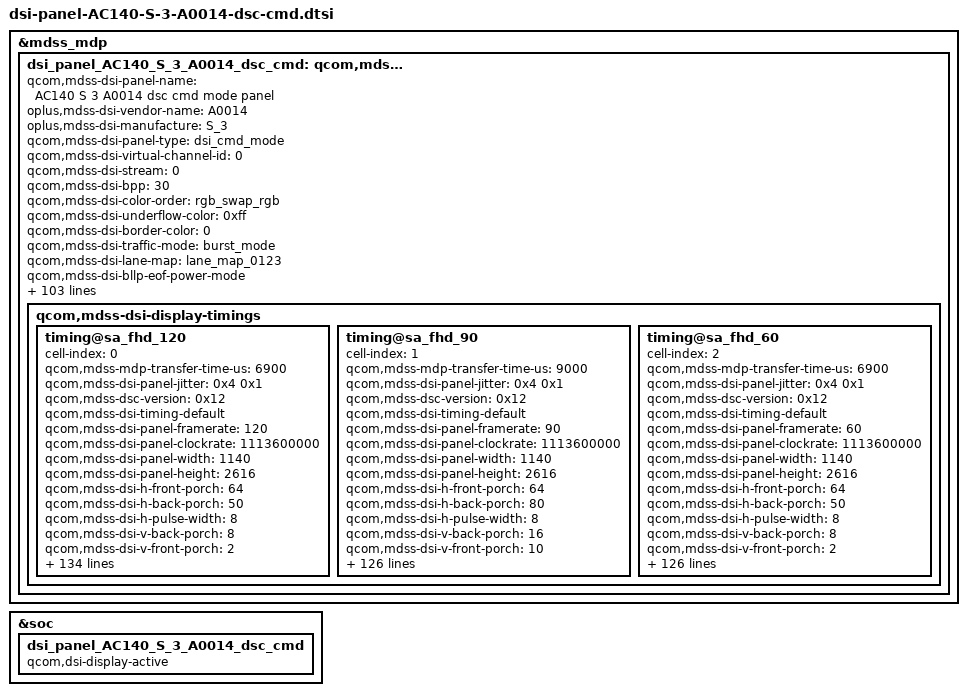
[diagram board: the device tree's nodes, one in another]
&mdss_mdp {
	dsi_panel_AC140_S_3_A0014_dsc_cmd: qcom,mdss_dsi_panel_AC140_S_3_A0014_dsc_cmd {
		qcom,mdss-dsi-panel-name = "AC140 S 3 A0014 dsc cmd mode panel";
		oplus,mdss-dsi-vendor-name = "A0014";
		oplus,mdss-dsi-manufacture = "S_3";
		qcom,mdss-dsi-panel-type = "dsi_cmd_mode";
		qcom,mdss-dsi-virtual-channel-id = <0>;
		qcom,mdss-dsi-stream = <0>;
		qcom,mdss-dsi-bpp = <30>;
		qcom,mdss-dsi-color-order = "rgb_swap_rgb";
		qcom,mdss-dsi-underflow-color = <0xff>;
		qcom,mdss-dsi-border-color = <0>;
		qcom,mdss-dsi-traffic-mode = "burst_mode";
		qcom,mdss-dsi-lane-map = "lane_map_0123";
		qcom,mdss-dsi-bllp-eof-power-mode;
		qcom,mdss-dsi-bllp-power-mode;
		qcom,mdss-dsi-lane-0-state;
		qcom,mdss-dsi-lane-1-state;
		qcom,mdss-dsi-lane-2-state;
		qcom,mdss-dsi-lane-3-state;
		qcom,mdss-dsi-dma-trigger = "trigger_sw";
		qcom,mdss-loading-effect;
		qcom,mdss-dsi-mdp-trigger = "none";
		qcom,mdss-dsi-reset-sequence = <1 2>, <0 5>, <1 30>;
		qcom,mdss-dsi-te-pin-select = <1>;
		qcom,mdss-dsi-te-dcs-command = <1>;
		qcom,mdss-pan-physical-width-dimension = <65>;
		qcom,mdss-pan-physical-height-dimension = <146>;
		qcom,mdss-dsi-init-delay-us = <1000>;
		qcom,mdss-dsi-te-check-enable;
		qcom,mdss-dsi-te-using-te-pin;
		//qcom,mdss-dsi-lp11-init;
		qcom,mdss-dsi-wr-mem-start = <0x2c>;
		qcom,mdss-dsi-wr-mem-continue = <0x3c>;
		qcom,mdss-dsi-panel-jitter = <0x4 0x1>;
		qcom,mdss-dsc-scr-version = <0x1>;
		qcom,mdss-bl-high2bit;
		/* HDR Setting */
		qcom,mdss-dsi-panel-hdr-enabled;
		qcom,mdss-dsi-panel-hdr-color-primaries = <15635 16450 34000 16000 13250 34500 7500 3000>;
		//update for [MPC15]android.mediapc.cts.PerformanceClassTest#testDisplayHdr pass
		//qcom,mdss-dsi-panel-peak-brightness = <16000000>;
		qcom,mdss-dsi-panel-peak-brightness = <22000000>;
		qcom,mdss-dsi-panel-average-brightness = <2000000>;
		qcom,mdss-dsi-panel-blackness-level = <4000>;
		qcom,dynamic-mode-switch-enabled;
		qcom,dynamic-mode-switch-type = "dynamic-resolution-switch-immediate";
		qcom,mdss-dsi-display-timings {
			timing@sa_fhd_120{
				cell-index = <0>;
				#include "dsi-panel-AC140-S-3-A0014-common.dtsi"
				qcom,mdss-mdp-transfer-time-us = <6900>;
				qcom,mdss-dsi-panel-jitter = <0x4 0x1>;
				qcom,mdss-dsc-version = <0x12>;
				qcom,mdss-dsi-timing-default;
				qcom,mdss-dsi-panel-framerate = <120>;
				qcom,mdss-dsi-panel-clockrate = <1113600000>;
				qcom,mdss-dsi-panel-width = <1140>;
				qcom,mdss-dsi-panel-height = <2616>;
				qcom,mdss-dsi-h-front-porch = <64>;
				qcom,mdss-dsi-h-back-porch = <50>;
				qcom,mdss-dsi-h-pulse-width = <8>;
				qcom,mdss-dsi-v-back-porch = <8>;
				qcom,mdss-dsi-v-front-porch = <2>;
				qcom,mdss-dsi-v-pulse-width = <2>;
				qcom,mdss-dsi-h-sync-pulse = <0>;

				qcom,mdss-dsi-h-left-border = <0>;
				qcom,mdss-dsi-h-right-border = <0>;
				qcom,mdss-dsi-v-top-border = <0>;
				qcom,mdss-dsi-v-bottom-border = <0>;
				qcom,dsi-mode-te-width-us = <270>;

				/* Apollo vsync config, need to measure TE signal */
				//oplus,apollo-panel-vsync-width = <13000>;
				//oplus,apollo-panel-vsync-period = <16600>;

				oplus,fod-on-vblank = <0>;
				oplus,fod-off-vblank = <0>;

				qcom,mdss-dsi-timing-switch-command = [
					//Switch to 120Hz(3+18pulse)
					15 00 00 40 00 00 02 2F 02
					39 00 00 40 00 00 06 35 00 00 00 00 00
					15 00 00 00 08 00 02 5A 10
					15 00 00 40 00 00 02 6D 00
					15 00 00 40 00 00 02 2F 32
					//Base 120hz(3+18pulse) SEQ Setting
					39 00 00 40 00 00 06 F0 55 AA 52 08 00
					15 00 00 40 00 00 02 6F 1C
					39 00 00 40 00 00 11 BA 01 00 00 00 00 00 00 00 00 00 00 00 00 00 00 00
					15 00 00 40 00 00 02 6F 2C
					39 00 00 40 00 00 11 BA 00 00 00 00 00 00 00 00 00 00 00 00 00 00 00 00
					15 00 00 40 00 00 02 6F 3C
					39 00 00 40 00 00 11 BA 00 00 00 00 00 00 00 00 00 00 00 00 00 00 00 00
					15 00 00 40 00 00 02 6F 4C
					39 00 00 40 00 00 11 BA 00 00 00 00 00 00 00 00 00 00 00 00 00 00 00 00
					15 00 00 40 00 00 02 6F 5C
					39 00 00 40 00 00 11 BA 01 01 01 01 01 01 01 01 01 01 01 01 01 01 01 01
					15 00 00 40 00 00 02 6F 6C
					39 00 00 40 00 00 09 BA 00 00 00 00 00 00 00 00
					15 00 00 40 00 00 02 6F 74
					39 00 00 40 00 00 11 BA 00 01 02 03 05 0B 17 77 00 02 05 08 11 59 00 00
					15 00 00 40 00 00 02 6F 84
					39 00 00 40 00 00 11 BA 00 01 02 03 05 0B 17 77 00 02 05 08 11 59 00 00
					15 00 00 40 00 00 02 6F 94
					39 00 00 40 00 00 11 BA 00 00 00 00 00 00 00 00 00 00 00 00 00 00 00 00
					15 00 00 40 00 00 02 6F A4
					39 00 00 40 00 00 11 BA 01 01 01 01 00 00 00 00 00 00 00 00 00 00 00 00
					15 00 00 40 00 00 02 6F B4
					39 00 00 40 00 00 05 BA 00 00 00 00
					15 00 00 40 00 00 02 6F B8
					39 00 00 40 00 00 09 BA 22 22 22 22 11 11 11 22
					15 00 00 40 00 00 02 6F C0
					39 00 00 00 00 00 09 BA 22 22 22 22 11 11 11 22
					];
				qcom,mdss-dsi-on-command = [
					39 00 00 40 00 00 06 F0 55 AA 52 08 00
					15 00 00 40 00 00 02 6F 03
					15 00 00 40 00 00 02 B5 65
					39 00 00 40 00 00 06 F0 55 AA 52 08 08
					15 00 00 40 00 00 02 6F 80
					39 00 00 40 00 00 0D B8 00 10 00 10 00 10 00 00 00 00 00 00
					39 00 00 00 00 00 11 E9 00 00 00 C5 18 94 0F E6 01 90 00 78 14 48 0F C6
					/* Drag optimization */
					39 00 00 40 00 00 06 F0 55 AA 52 08 08
					15 00 00 40 00 00 02 E0 31
					15 00 00 40 00 00 02 6F 05
					15 00 00 40 00 00 02 E0 20
					15 00 00 40 00 00 02 6F 02
					15 00 00 40 00 00 02 E1 05
					15 00 00 40 00 00 02 6F 02
					15 00 00 40 00 00 02 E2 0A
					15 00 00 40 00 00 02 6F 0E
					39 00 00 40 00 00 04 E1 00 00 0D
					15 00 00 40 00 00 02 6F 0E
					39 00 00 40 00 00 04 E2 02 06 13
					15 00 00 40 00 00 02 6F 0E
					39 00 00 40 00 00 04 E3 00 02 00
					15 00 00 40 00 00 02 6F 1E
					15 00 00 40 00 00 02 E1 00
					15 00 00 40 00 00 02 6F 1E
					15 00 00 40 00 00 02 E2 1C
					15 00 00 40 00 00 02 6F 2C
					15 00 00 40 00 00 02 E2 0A
					15 00 00 40 00 00 02 6F 2C
					15 00 00 40 00 00 02 E3 01
					15 00 00 40 00 00 02 6F 3A
					15 00 00 40 00 00 02 E1 04
					15 00 00 40 00 00 02 6F 3A
					15 00 00 40 00 00 02 E2 0B
					15 00 00 40 00 00 02 6F 48
					15 00 00 40 00 00 02 E2 06
					15 00 00 40 00 00 02 6F 48
					15 00 00 40 00 00 02 E3 04
					15 00 00 40 00 00 02 6F 56
					15 00 00 40 00 00 02 E2 06
					15 00 00 40 00 00 02 6F 56
					15 00 00 40 00 00 02 E3 04
					15 00 00 40 00 00 02 6F 64
					15 00 00 40 00 00 02 E2 04
					15 00 00 40 00 00 02 6F 64
					15 00 00 00 00 00 02 E3 01
					/* Power consumption optimization */
					39 00 00 40 00 00 06 F0 55 AA 52 08 03
					15 00 00 40 00 00 02 6F 33
					39 00 00 40 00 00 0B B0 00 00 00 00 00 00 00 00 00 00
					15 00 00 40 00 00 02 6F 3D
					39 00 00 40 00 00 0B B0 00 00 00 00 00 00 00 00 00 00
					15 00 00 40 00 00 02 6F 47
					39 00 00 40 00 00 0B B0 00 00 00 00 00 00 00 00 00 00
					15 00 00 40 00 00 02 6F 51
					39 00 00 40 00 00 0B B0 00 00 00 00 00 00 00 00 00 00
					15 00 00 40 00 00 02 6F 0C
					39 00 00 00 00 00 04 C3 44 00 04
					/*Common Setting*/
					39 00 00 40 00 00 06 F0 55 AA 52 08 00
					15 00 00 40 00 00 02 6F 5A
					39 00 00 00 00 00 08 D1 33 33 33 33 11 11 11
					39 00 00 40 00 00 06 F0 55 AA 52 08 01
					15 00 00 40 00 00 02 6F 03
					39 00 00 40 00 00 04 C5 00 24 24
					15 00 00 40 00 00 02 E5 00
					39 00 00 40 00 00 06 F0 55 AA 52 00 00
					39 00 00 40 00 00 05 FF AA 55 A5 80
					15 00 00 40 00 00 02 6F 16
					39 00 00 40 00 00 03 F4 02 74
					15 00 00 40 00 00 02 6F 31
					39 00 00 40 00 00 03 F8 01 73
					15 00 00 40 00 00 02 6F 15
					39 00 00 40 00 00 03 F8 01 8F
					15 00 00 40 00 00 02 6F 42
					15 00 00 40 00 00 02 F4 00
					15 00 00 40 00 00 02 6F 49
					15 00 00 40 00 00 02 F2 10
					39 00 00 40 00 00 05 FF AA 55 A5 81
					15 00 00 40 00 00 02 6F 0D
					15 00 00 40 00 00 02 FB 80
					15 00 00 40 00 00 02 6F 10
					15 00 00 40 00 00 02 FB 40
					15 00 00 40 00 00 02 6F 0C
					15 00 00 40 00 00 02 FD 08
					15 00 00 40 00 00 02 6F 05
					39 00 00 40 00 00 03 FE 3C 3C
					15 00 00 40 00 00 02 6F 0B
					15 00 00 40 00 00 02 FD 04
					39 00 00 40 00 00 05 FF AA 55 A5 82
					15 00 00 40 00 00 02 6F 09
					15 00 00 40 00 00 02 F2 FF
					39 00 00 40 00 00 05 FF AA 55 A5 83
					39 00 00 40 00 00 05 FF AA 55 A5 00
					05 00 00 00 00 00 01 35
					15 00 00 40 00 00 02 53 20
					39 00 00 40 00 00 05 2A 00 00 04 73
					39 00 00 40 00 00 05 2B 00 00 0A 37
					15 00 00 40 00 00 02 26 00
					39 00 00 00 00 00 03 81 01 19
					/*DSC Setting*/
					39 00 00 40 00 00 03 90 03 43
					39 00 00 00 00 00 13 91 A0 F0 00 0C D1 00 01 CC 00 50 00 2F 09 75 2D 7A 11 50
					//Switch to 120Hz(3+18pulse)
					15 00 00 40 00 00 02 2F 02
					39 00 00 40 00 00 06 35 00 00 00 00 00
					15 00 00 00 08 00 02 5A 10
					15 00 00 40 00 00 02 6D 00
					15 00 00 40 00 00 02 2F 32
					//Base 120hz(3+18pulse) SEQ Setting
					39 00 00 40 00 00 06 F0 55 AA 52 08 00
					15 00 00 40 00 00 02 6F 1C
					39 00 00 40 00 00 11 BA 01 00 00 00 00 00 00 00 00 00 00 00 00 00 00 00
					15 00 00 40 00 00 02 6F 2C
					39 00 00 40 00 00 11 BA 00 00 00 00 00 00 00 00 00 00 00 00 00 00 00 00
					15 00 00 40 00 00 02 6F 3C
					39 00 00 40 00 00 11 BA 00 00 00 00 00 00 00 00 00 00 00 00 00 00 00 00
					15 00 00 40 00 00 02 6F 4C
					39 00 00 40 00 00 11 BA 00 00 00 00 00 00 00 00 00 00 00 00 00 00 00 00
					15 00 00 40 00 00 02 6F 5C
					39 00 00 40 00 00 11 BA 01 01 01 01 01 01 01 01 01 01 01 01 01 01 01 01
					15 00 00 40 00 00 02 6F 6C
					39 00 00 40 00 00 09 BA 00 00 00 00 00 00 00 00
					15 00 00 40 00 00 02 6F 74
					39 00 00 40 00 00 11 BA 00 01 02 03 05 0B 17 77 00 02 05 08 11 59 00 00
					15 00 00 40 00 00 02 6F 84
					39 00 00 40 00 00 11 BA 00 01 02 03 05 0B 17 77 00 02 05 08 11 59 00 00
					15 00 00 40 00 00 02 6F 94
					39 00 00 40 00 00 11 BA 00 00 00 00 00 00 00 00 00 00 00 00 00 00 00 00
					15 00 00 40 00 00 02 6F A4
					39 00 00 40 00 00 11 BA 01 01 01 01 00 00 00 00 00 00 00 00 00 00 00 00
					15 00 00 40 00 00 02 6F B4
					39 00 00 40 00 00 05 BA 00 00 00 00
					15 00 00 40 00 00 02 6F B8
					39 00 00 40 00 00 09 BA 22 22 22 22 11 11 11 22
					15 00 00 40 00 00 02 6F C0
					39 00 00 00 00 00 09 BA 22 22 22 22 11 11 11 22
					/* delay 8ms make sure pmic timing normal */
					39 00 00 40 00 00 06 F0 55 AA 52 08 00
					15 00 00 40 00 00 02 6F 02
					39 00 00 00 00 00 03 B5 2A 95
					/*add VDC code resolve 100%APL brightness */
					39 00 00 40 00 00 06 F0 55 AA 52 08 08
					39 00 00 40 00 00 11 BE 03 F1 00 5B 02 C0 03 C6 BA 6C 03 C6 BA 6C 03 59
					39 00 00 40 00 00 02 6F 10
					39 00 00 40 00 00 11 BE CA BA 03 59 CA BA 01 22 04 BA 01 22 04 BA 01 01
					39 00 00 40 00 00 02 6F 20
					39 00 00 00 00 00 11 BE 56 6B 01 01 56 6B 04 A9 BB B4 01 66 1E B6 80 64
					39 00 00 40 00 00 06 F0 55 AA 52 08 07
					39 00 00 40 00 00 04 C0 07 01 F8
					15 00 00 40 00 00 02 6F 03
					39 00 00 40 00 00 05 C0 00 00 00 00
					39 00 00 40 00 00 16 C1 30 0F 02 40 04 00 FA 00 3F FE 12 00 3F FC 52 00 00 00 65 C0 00
					15 00 00 40 00 00 02 6F 15
					39 00 00 40 00 00 11 C1 20 00 1F 77 00 00 20 33 F0 E0 A8 0B 00 00 00 00
					15 00 00 40 00 00 02 6F 25
					39 00 00 40 00 00 08 C1 00 00 1E 00 00 20 00
					39 00 00 40 00 00 16 C2 38 0F 06 40 02 40 F8 80 3F FB 3D 40 3F FD E9 A0 00 00 78 D9 80
					15 00 00 40 00 00 02 6F 15
					39 00 00 40 00 00 11 C2 64 00 00 1E 00 21 85 33 F0 9C E2 0B B8 00 00 00
					15 00 00 40 00 00 02 6F 25
					39 00 00 40 00 00 08 C2 44 55 73 00 00 20 00
					39 00 00 40 00 00 16 C3 3C 00 0E 89 03 C1 0E C6 3F F1 59 00 00 00 00 00 00 00 00 00 00
					15 00 00 40 00 00 02 6F 15
					39 00 00 40 00 00 11 C3 70 00 00 1F 9A A3 16 33 C0 8D 1F 00 00 00 00 00
					15 00 00 40 00 00 02 6F 25
					39 00 00 40 00 00 08 C3 00 00 1F AA 17 37 00
					39 00 00 40 00 00 16 C4 34 00 03 84 03 C1 07 44 3F FC 6C 0C 00 03 93 F4 00 00 00 00 00
					15 00 00 40 00 00 02 6F 15
					39 00 00 40 00 00 11 C4 20 00 20 7D AA 17 37 33 C0 E0 5D 00 00 00 00 00
					15 00 00 40 00 00 02 6F 25
					39 00 00 40 00 00 08 C4 44 54 73 AA 17 37 00
					39 00 00 40 00 00 16 C5 2A 0F 0D 24 03 49 F2 DC 00 0A 36 88 00 01 BF 3C 7F FE 92 11 64
					15 00 00 40 00 00 02 6F 15
					39 00 00 40 00 00 11 C5 70 44 54 73 9A A4 16 33 0F 72 1F F2 32 00 00 00
					15 00 00 40 00 00 02 6F 25
					39 00 00 40 00 00 08 C5 00 00 00 00 00 00 00
					39 00 00 40 00 00 16 C6 2A 0F 01 E4 04 00 FA 80 00 01 20 30 00 04 15 60 7F FF 6D 54 00
					15 00 00 40 00 00 02 6F 15
					39 00 00 40 00 00 11 C6 00 34 FF 53 AA 17 37 33 0F 20 54 F5 80 00 00 00
					15 00 00 40 00 00 02 6F 25
					39 00 00 40 00 00 08 C6 00 00 00 00 00 00 00
					39 00 00 40 00 00 16 C7 26 00 02 40 04 84 06 60 00 00 64 00 3F FA 0B 00 00 00 00 00 00
					15 00 00 40 00 00 02 6F 15
					39 00 00 40 00 00 11 C7 1F 34 FC 54 00 00 20 33 30 20 A8 00 00 00 00 00
					15 00 00 40 00 00 02 6F 25
					39 00 00 40 00 00 08 C7 00 00 00 00 00 00 00
					39 00 00 40 00 00 16 C8 26 00 0B 64 02 A4 0A F8 00 03 D4 00 3F FC 2C 00 00 00 00 00 00
					15 00 00 40 00 00 02 6F 15
					39 00 00 40 00 00 11 C8 00 44 55 73 00 21 8F 33 30 6E E2 00 00 00 00 00
					15 00 00 40 00 00 02 6F 25
					39 00 00 40 00 00 08 C8 00 00 00 00 00 00 00
					39 00 00 40 00 00 16 C9 21 00 05 10 05 10 00 00 3F FE 93 80 3F FE 93 80 00 00 1C 84 20
					15 00 00 40 00 00 02 6F 15
					39 00 00 40 00 00 11 C9 0A 22 14 39 00 1C 41 55 F0 DC DC 05 10 F0 FF FF
					15 00 00 40 00 00 02 6F 25
					39 00 00 40 00 00 08 C9 00 00 00 00 00 00 00
					39 00 00 40 00 00 16 CA 27 00 05 10 05 10 00 00 00 00 00 00 3F FE 93 80 00 00 01 71 90
					15 00 00 40 00 00 02 6F 15
					39 00 00 40 00 00 11 CA 0A 22 3A 5F 00 1C 41 55 30 24 DC 00 00 C0 00 FF
					15 00 00 40 00 00 02 6F 25
					39 00 00 40 00 00 08 CA 00 00 00 00 00 00 00
					39 00 00 40 00 00 16 CB 2D 00 05 10 05 10 00 00 3F FE 93 80 00 00 00 00 00 00 01 71 90
					15 00 00 40 00 00 02 6F 15
					39 00 00 40 00 00 11 CB 19 22 14 39 00 42 67 55 C0 DC 24 00 00 30 FF 00
					15 00 00 40 00 00 02 6F 25
					39 00 00 40 00 00 08 CB 00 00 00 00 00 00 00
					39 00 00 40 00 00 16 CC 2B 00 05 10 05 10 00 00 00 00 00 00 00 00 00 00 7F FF E6 5F 00
					15 00 00 40 00 00 02 6F 15
					39 00 00 40 00 00 11 CC 19 22 3A 5F 00 42 67 55 0F 24 24 FA F0 00 00 00
					15 00 00 40 00 00 02 6F 25
					39 00 00 40 00 00 08 CC 00 00 00 00 00 00 00
					39 00 00 40 00 00 16 CD 00 00 00 00 00 00 00 00 00 00 00 00 00 00 00 00 00 00 00 00 00
					15 00 00 40 00 00 02 6F 15
					39 00 00 40 00 00 11 CD 00 00 00 00 00 00 00 00 00 00 00 00 00 00 00 00
					15 00 00 40 00 00 02 6F 25
					39 00 00 40 00 00 08 CD 00 00 00 00 00 00 00
					39 00 00 40 00 00 16 CE 00 00 00 00 00 00 00 00 00 00 00 00 00 00 00 00 00 00 00 00 00
					15 00 00 40 00 00 02 6F 15
					39 00 00 40 00 00 11 CE 00 00 00 00 00 00 00 00 00 00 00 00 00 00 00 00
					15 00 00 40 00 00 02 6F 25
					39 00 00 40 00 00 08 CE 00 00 00 00 00 00 00
					39 00 00 40 00 00 16 CF 00 00 00 00 00 00 00 00 00 00 00 00 00 00 00 00 00 00 00 00 00
					15 00 00 40 00 00 02 6F 15
					39 00 00 40 00 00 11 CF 00 00 00 00 00 00 00 00 00 00 00 00 00 00 00 00
					15 00 00 40 00 00 02 6F 25
					39 00 00 40 00 00 08 CF 00 00 00 00 00 00 00
					39 00 00 40 00 00 16 D0 00 00 00 00 00 00 00 00 00 00 00 00 00 00 00 00 00 00 00 00 00
					15 00 00 40 00 00 02 6F 15
					39 00 00 40 00 00 11 D0 00 00 00 00 00 00 00 00 00 00 00 00 00 00 00 00
					15 00 00 40 00 00 02 6F 25
					39 00 00 40 00 00 08 D0 00 00 00 00 00 00 00
					39 00 00 40 00 00 0F D1 80 00 00 00 00 04 73 80 00 00 00 00 04 73
					15 00 00 40 00 00 02 6F 0E
					39 00 00 40 00 00 0F D1 FF FE 70 57 49 04 73 FF FF 2A 07 00 04 73
					15 00 00 40 00 00 02 6F 1C
					39 00 00 40 00 00 0F D1 00 00 00 00 00 04 74 00 00 00 00 00 04 74
					15 00 00 40 00 00 02 6F 2A
					39 00 00 40 00 00 0C D1 00 00 66 70 00 04 74 00 00 9A E3
					39 00 00 00 00 00 12 D2 90 04 74 00 00 01 71 90 04 5C 00 00 1C 84 20 04 5C
					//SPR SETTING
					39 00 00 40 00 00 06 F0 55 AA 52 08 02
					15 00 00 40 00 00 02 C1 02
					39 00 00 40 00 00 05 C2 19 00 91 00
					39 00 00 40 00 00 06 F0 55 AA 52 08 03
					15 00 00 40 00 00 02 6F 08
					15 00 00 40 00 00 02 DE 00
					15 00 00 40 00 00 02 6F 09
					39 00 00 40 00 00 07 DE 30 14 25 10 34 25
					39 00 00 40 00 00 06 F0 55 AA 52 08 07
					39 00 00 40 00 00 06 B0 84 C4 00 00 40
					39 00 00 00 00 00 07 B1 08 18 00 18 08 00
					/*VDC setting only for EVT1 and before*/
					39 00 00 40 00 00 06 F0 55 AA 52 08 08
					39 00 00 40 00 00 02 6F 80
					39 00 00 40 00 00 0D B8 00 10 00 10 00 10 00 00 00 00 00 00
					39 00 00 00 00 00 11 E9 00 00 00 C5 18 94 0F E6 01 90 00 78 14 48 0F C6
					/*DDIC round corner*/
                    39 00 00 40 00 00 06 F0 55 AA 52 08 07
                    39 00 00 40 00 00 04 C0 07 01 F8
                    15 00 00 40 00 00 02 6F 03
                    39 00 00 40 00 00 05 C0 00 00 00 00
                    39 00 00 40 00 00 16 C1 36 00 03 49 0B 64 0C 3C 00 00 26 74 3F F3 88 64 00 00 00 00 00
                    15 00 00 40 00 00 02 6F 15
                    39 00 00 40 00 00 11 C1 1E 34 E1 51 00 00 1F 33 30 1F 90 00 00 00 00 00
                    15 00 00 40 00 00 02 6F 25
                    39 00 00 40 00 00 08 C1 44 52 73 00 00 1F 00
                    39 00 00 40 00 00 16 C2 36 00 0A 29 03 49 0B 8E 00 04 49 78 3F FB 6A D8 00 00 00 00 00
                    15 00 00 40 00 00 02 6F 15
                    39 00 00 40 00 00 11 C2 01 44 52 73 00 20 8D 33 30 6D DF 00 00 00 00 00
                    15 00 00 40 00 00 02 6F 25
                    39 00 00 40 00 00 08 C2 00 00 21 00 01 1F 00
                    39 00 00 40 00 00 16 C3 30 0F 0A 29 03 C1 F3 A6 3F F8 E6 92 3F FC A6 1A 00 00 BF 0E C5
                    15 00 00 40 00 00 02 6F 15
                    39 00 00 40 00 00 11 C3 02 00 00 21 00 20 8D 33 F0 93 DF 0E 0D 00 00 00
                    15 00 00 40 00 00 02 6F 25
                    39 00 00 40 00 00 08 C3 44 52 72 AA 18 37 00
                    39 00 00 40 00 00 16 C4 30 0F 03 C1 0B 64 F2 EC 3F FC B7 20 3F F8 AF E4 00 00 B7 F1 00
                    15 00 00 40 00 00 02 6F 15
                    39 00 00 40 00 00 11 C4 1D 00 22 92 00 00 1F 33 F0 E1 90 0D 90 00 00 00
                    15 00 00 40 00 00 02 6F 25
                    39 00 00 40 00 00 08 C4 00 00 21 AA 18 36 00
                    39 00 00 40 00 00 16 C5 2A 0F 03 49 0B 64 F3 C4 00 01 A1 B8 00 09 B5 64 7F FE A8 46 80
                    15 00 00 40 00 00 02 6F 15
                    39 00 00 40 00 00 11 C5 00 34 E1 51 AA 18 37 33 0F 1F 70 F2 70 00 00 00
                    15 00 00 40 00 00 02 6F 25
                    39 00 00 40 00 00 08 C5 00 00 00 00 00 00 00
                    39 00 00 40 00 00 16 C6 2A 0F 0A 29 03 49 F4 72 00 09 34 EE 00 01 C8 FE 7F FE A4 F4 E9
                    15 00 00 40 00 00 02 6F 15
                    39 00 00 40 00 00 11 C6 6B 44 52 73 9A AA 17 33 0F 6D 21 F1 F3 00 00 00
                    15 00 00 40 00 00 02 6F 25
                    39 00 00 40 00 00 08 C6 00 00 00 00 00 00 00
                    39 00 00 40 00 00 16 C7 2C 00 03 C1 0B 64 0D 14 3F FB 21 B4 00 04 8D E4 00 00 00 00 00
                    15 00 00 40 00 00 02 6F 15
                    39 00 00 40 00 00 11 C7 01 00 22 92 AA 18 37 33 C0 E1 70 00 00 00 00 00
                    15 00 00 40 00 00 02 6F 25
                    39 00 00 40 00 00 08 C7 00 00 00 00 00 00 00
                    39 00 00 40 00 00 16 C8 2C 00 0A 29 03 C1 0C 5A 3F F3 A4 40 00 00 27 8C 00 00 00 00 00
                    15 00 00 40 00 00 02 6F 15
                    39 00 00 40 00 00 11 C8 6A 00 00 21 9A AA 17 33 C0 93 21 00 00 00 00 00
                    15 00 00 40 00 00 02 6F 25
                    39 00 00 40 00 00 08 C8 00 00 00 00 00 00 00
                    39 00 00 40 00 00 16 C9 21 00 05 10 05 10 00 00 3F FE 93 80 3F FE 93 80 00 00 1C 84 20
                    15 00 00 40 00 00 02 6F 15
                    39 00 00 40 00 00 11 C9 0A 22 14 39 00 1C 41 55 F0 DC DC 05 10 F0 FF FF
                    15 00 00 40 00 00 02 6F 25
                    39 00 00 40 00 00 08 C9 00 00 00 00 00 00 00
                    39 00 00 40 00 00 16 CA 27 00 05 10 05 10 00 00 00 00 00 00 3F FE 93 80 00 00 01 71 90
                    15 00 00 40 00 00 02 6F 15
                    39 00 00 40 00 00 11 CA 0A 22 3A 5F 00 1C 41 55 30 24 DC 00 00 C0 00 FF
                    15 00 00 40 00 00 02 6F 25
                    39 00 00 40 00 00 08 CA 00 00 00 00 00 00 00
                    39 00 00 40 00 00 16 CB 2D 00 05 10 05 10 00 00 3F FE 93 80 00 00 00 00 00 00 01 71 90
                    15 00 00 40 00 00 02 6F 15
                    39 00 00 40 00 00 11 CB 19 22 14 39 00 42 67 55 C0 DC 24 00 00 30 FF 00
                    15 00 00 40 00 00 02 6F 25
                    39 00 00 40 00 00 08 CB 00 00 00 00 00 00 00
                    39 00 00 40 00 00 16 CC 2B 00 05 10 05 10 00 00 00 00 00 00 00 00 00 00 7F FF E6 5F 00
                    15 00 00 40 00 00 02 6F 15
                    39 00 00 40 00 00 11 CC 19 22 3A 5F 00 42 67 55 0F 24 24 FA F0 00 00 00
                    15 00 00 40 00 00 02 6F 25
                    39 00 00 40 00 00 08 CC 00 00 00 00 00 00 00
                    39 00 00 40 00 00 16 CD 00 00 00 00 00 00 00 00 00 00 00 00 00 00 00 00 00 00 00 00 00
                    15 00 00 40 00 00 02 6F 15
                    39 00 00 40 00 00 11 CD 00 00 00 00 00 00 00 00 00 00 00 00 00 00 00 00
                    15 00 00 40 00 00 02 6F 25
                    39 00 00 40 00 00 08 CD 00 00 00 00 00 00 00
                    39 00 00 40 00 00 16 CE 00 00 00 00 00 00 00 00 00 00 00 00 00 00 00 00 00 00 00 00 00
                    15 00 00 40 00 00 02 6F 15
                    39 00 00 40 00 00 11 CE 00 00 00 00 00 00 00 00 00 00 00 00 00 00 00 00
                    15 00 00 40 00 00 02 6F 25
                    39 00 00 40 00 00 08 CE 00 00 00 00 00 00 00
                    39 00 00 40 00 00 16 CF 00 00 00 00 00 00 00 00 00 00 00 00 00 00 00 00 00 00 00 00 00
                    15 00 00 40 00 00 02 6F 15
                    39 00 00 40 00 00 11 CF 00 00 00 00 00 00 00 00 00 00 00 00 00 00 00 00
                    15 00 00 40 00 00 02 6F 25
                    39 00 00 40 00 00 08 CF 00 00 00 00 00 00 00
                    39 00 00 40 00 00 16 D0 00 00 00 00 00 00 00 00 00 00 00 00 00 00 00 00 00 00 00 00 00
                    15 00 00 40 00 00 02 6F 15
                    39 00 00 40 00 00 11 D0 00 00 00 00 00 00 00 00 00 00 00 00 00 00 00 00
                    15 00 00 40 00 00 02 6F 25
                    39 00 00 40 00 00 08 D0 00 00 00 00 00 00 00
                    39 00 00 40 00 00 0F D1 00 00 B1 CB C0 04 74 00 00 B8 B0 E1 04 74
                    15 00 00 40 00 00 02 6F 0E
                    39 00 00 40 00 00 0F D1 00 00 00 00 00 00 00 00 00 00 00 00 00 00
                    15 00 00 40 00 00 02 6F 1C
                    39 00 00 40 00 00 0F D1 00 00 00 00 00 00 00 00 00 00 00 00 00 00
                    15 00 00 40 00 00 02 6F 2A
                    39 00 00 40 00 00 0C D1 7F FE 96 AF C0 00 00 7F FE 93 64
                    39 00 00 40 00 00 12 D2 A9 00 00 00 00 01 71 90 04 5C 00 00 1C 84 20 04 5C
                    39 00 00 40 00 00 06 F0 55 AA 52 08 00
                    15 00 00 40 00 00 02 6F 13
                    39 00 00 40 00 00 19 DF 00 00 00 00 00 00 00 00 00 00 00 00 00 00 00 00 00 00 00 00 00 00 00 00
                    39 00 00 00 00 00 0A 88 00 00 00 00 00 00 00 00 00
					/* elvdd 4.8V */
					39 00 00 40 00 00 06 F0 55 AA 52 08 00
					15 00 00 40 00 00 02 6F 63
					15 00 00 00 00 00 02 D5 20
					39 00 00 40 00 00 06 F0 55 AA 52 08 00
					15 00 00 40 00 00 02 BE 54
					15 00 00 40 00 00 02 6F 08
					15 00 00 00 00 00 02 B2 C0
					/* Remove black insertion */
					39 00 00 40 00 00 06 F0 55 AA 52 08 01
					15 00 00 40 00 00 02 6F 01
					15 00 00 40 00 00 02 D2 00
					39 00 00 00 00 00 06 F0 55 AA 52 08 00
					/* Elvdd timing delay */
					39 00 00 40 00 00 06 F0 55 AA 52 08 01
					15 00 00 40 00 00 02 CD 61
					39 00 00 00 00 00 06 F0 55 AA 52 08 00
					/* Enable 60 to 30 */
					39 00 00 40 00 00 06 F0 55 AA 52 08 00
					15 00 00 40 00 00 02 6F 6E
					39 00 00 00 00 00 03 D1 FF FF
					/* Vin3 delay */
					39 00 00 40 00 00 06 F0 55 AA 52 08 01
					15 00 00 40 00 00 02 6F 00
					15 00 00 40 00 00 02 D8 40
					39 00 00 00 00 00 06 F0 55 AA 52 08 00
					/*sleep out*/
					05 00 00 00 78 00 01 11
					/*display on*/
					05 00 00 00 00 00 01 29
				];
				qcom,mdss-dsi-optimize-on-command = [
					39 00 00 40 00 00 06 F0 55 AA 52 08 00
					15 00 00 40 00 00 02 6F 03
					15 00 00 40 00 00 02 B5 65
					39 00 00 40 00 00 06 F0 55 AA 52 08 08
					15 00 00 40 00 00 02 6F 80
					39 00 00 40 00 00 0D B8 00 10 00 10 00 10 00 00 00 00 00 00
					39 00 00 40 00 00 11 E9 00 00 00 C5 18 94 0F E6 01 90 00 78 14 48 0F C6
					/*Common Setting*/
					39 00 00 40 00 00 06 F0 55 AA 52 08 00
					15 00 00 40 00 00 02 6F 5A
					39 00 00 00 00 00 08 D1 33 33 33 33 11 11 11
					39 00 00 40 00 00 06 F0 55 AA 52 08 01
					15 00 00 40 00 00 02 6F 03
					39 00 00 40 00 00 04 C5 00 24 24
					15 00 00 40 00 00 02 E5 00
					39 00 00 40 00 00 06 F0 55 AA 52 00 00
					39 00 00 40 00 00 05 FF AA 55 A5 80
					15 00 00 40 00 00 02 6F 16
					39 00 00 40 00 00 03 F4 02 74
					15 00 00 40 00 00 02 6F 31
					39 00 00 40 00 00 03 F8 01 73
					15 00 00 40 00 00 02 6F 15
					39 00 00 40 00 00 03 F8 01 8F
					15 00 00 40 00 00 02 6F 42
					15 00 00 40 00 00 02 F4 00
					15 00 00 40 00 00 02 6F 49
					15 00 00 40 00 00 02 F2 10
					39 00 00 40 00 00 05 FF AA 55 A5 81
					15 00 00 40 00 00 02 6F 0D
					15 00 00 40 00 00 02 FB 80
					15 00 00 40 00 00 02 6F 10
					15 00 00 40 00 00 02 FB 40
					15 00 00 40 00 00 02 6F 0C
					15 00 00 40 00 00 02 FD 08
					15 00 00 40 00 00 02 6F 05
					39 00 00 40 00 00 03 FE 3C 3C
					15 00 00 40 00 00 02 6F 0B
					15 00 00 40 00 00 02 FD 04
					39 00 00 40 00 00 05 FF AA 55 A5 82
					15 00 00 40 00 00 02 6F 09
					15 00 00 40 00 00 02 F2 FF
					39 00 00 40 00 00 05 FF AA 55 A5 83
					39 00 00 40 00 00 05 FF AA 55 A5 00
					05 00 00 00 00 00 01 35
					15 00 00 40 00 00 02 53 20
					39 00 00 40 00 00 05 2A 00 00 04 73
					39 00 00 40 00 00 05 2B 00 00 0A 37
					15 00 00 40 00 00 02 26 00
					39 00 00 00 00 00 03 81 01 19
					/*DSC Setting*/
					39 00 00 40 00 00 03 90 03 43
					39 00 00 00 00 00 13 91 A0 F0 00 0C D1 00 01 CC 00 50 00 2F 09 75 2D 7A 11 50
					//Switch to 120Hz(3+18pulse)
					15 00 00 40 00 00 02 2F 02
					39 00 00 40 00 00 06 35 00 00 00 00 00
					15 00 00 00 08 00 02 5A 10
					15 00 00 40 00 00 02 6D 00
					15 00 00 40 00 00 02 2F 32
					//Base 120hz(3+18pulse) SEQ Setting
					39 00 00 40 00 00 06 F0 55 AA 52 08 00
					15 00 00 40 00 00 02 6F 1C
					39 00 00 40 00 00 11 BA 01 00 00 00 00 00 00 00 00 00 00 00 00 00 00 00
					15 00 00 40 00 00 02 6F 2C
					39 00 00 40 00 00 11 BA 00 00 00 00 00 00 00 00 00 00 00 00 00 00 00 00
					15 00 00 40 00 00 02 6F 3C
					39 00 00 40 00 00 11 BA 00 00 00 00 00 00 00 00 00 00 00 00 00 00 00 00
					15 00 00 40 00 00 02 6F 4C
					39 00 00 40 00 00 11 BA 00 00 00 00 00 00 00 00 00 00 00 00 00 00 00 00
					15 00 00 40 00 00 02 6F 5C
					39 00 00 40 00 00 11 BA 01 01 01 01 01 01 01 01 01 01 01 01 01 01 01 01
					15 00 00 40 00 00 02 6F 6C
					39 00 00 40 00 00 09 BA 00 00 00 00 00 00 00 00
					15 00 00 40 00 00 02 6F 74
					39 00 00 40 00 00 11 BA 00 01 02 03 05 0B 17 77 00 02 05 08 11 59 00 00
					15 00 00 40 00 00 02 6F 84
					39 00 00 40 00 00 11 BA 00 01 02 03 05 0B 17 77 00 02 05 08 11 59 00 00
					15 00 00 40 00 00 02 6F 94
					39 00 00 40 00 00 11 BA 00 00 00 00 00 00 00 00 00 00 00 00 00 00 00 00
					15 00 00 40 00 00 02 6F A4
					39 00 00 40 00 00 11 BA 01 01 01 01 00 00 00 00 00 00 00 00 00 00 00 00
					15 00 00 40 00 00 02 6F B4
					39 00 00 40 00 00 05 BA 00 00 00 00
					15 00 00 40 00 00 02 6F B8
					39 00 00 40 00 00 09 BA 22 22 22 22 11 11 11 22
					15 00 00 40 00 00 02 6F C0
					39 00 00 00 00 00 09 BA 22 22 22 22 11 11 11 22
					/* delay 8ms make sure pmic timing normal */
					39 00 00 40 00 00 06 F0 55 AA 52 08 00
					15 00 00 40 00 00 02 6F 02
					39 00 00 00 00 00 03 B5 2A 95
					/*add VDC code resolve 100%APL brightness */
					39 00 00 40 00 00 06 F0 55 AA 52 08 08
					39 00 00 40 00 00 11 BE 03 F1 00 5B 02 C0 03 C6 BA 6C 03 C6 BA 6C 03 59
					39 00 00 40 00 00 02 6F 10
					39 00 00 40 00 00 11 BE CA BA 03 59 CA BA 01 22 04 BA 01 22 04 BA 01 01
					39 00 00 40 00 00 02 6F 20
					39 00 00 00 00 00 11 BE 56 6B 01 01 56 6B 04 A9 BB B4 01 66 1E B6 80 64
					39 00 00 40 00 00 06 F0 55 AA 52 08 07
					39 00 00 40 00 00 04 C0 07 01 F8
					15 00 00 40 00 00 02 6F 03
					39 00 00 40 00 00 05 C0 00 00 00 00
					39 00 00 40 00 00 16 C1 30 0F 02 40 04 00 FA 00 3F FE 12 00 3F FC 52 00 00 00 65 C0 00
					15 00 00 40 00 00 02 6F 15
					39 00 00 40 00 00 11 C1 20 00 1F 77 00 00 20 33 F0 E0 A8 0B 00 00 00 00
					15 00 00 40 00 00 02 6F 25
					39 00 00 40 00 00 08 C1 00 00 1E 00 00 20 00
					39 00 00 40 00 00 16 C2 38 0F 06 40 02 40 F8 80 3F FB 3D 40 3F FD E9 A0 00 00 78 D9 80
					15 00 00 40 00 00 02 6F 15
					39 00 00 40 00 00 11 C2 64 00 00 1E 00 21 85 33 F0 9C E2 0B B8 00 00 00
					15 00 00 40 00 00 02 6F 25
					39 00 00 40 00 00 08 C2 44 55 73 00 00 20 00
					39 00 00 40 00 00 16 C3 3C 00 0E 89 03 C1 0E C6 3F F1 59 00 00 00 00 00 00 00 00 00 00
					15 00 00 40 00 00 02 6F 15
					39 00 00 40 00 00 11 C3 70 00 00 1F 9A A3 16 33 C0 8D 1F 00 00 00 00 00
					15 00 00 40 00 00 02 6F 25
					39 00 00 40 00 00 08 C3 00 00 1F AA 17 37 00
					39 00 00 40 00 00 16 C4 34 00 03 84 03 C1 07 44 3F FC 6C 0C 00 03 93 F4 00 00 00 00 00
					15 00 00 40 00 00 02 6F 15
					39 00 00 40 00 00 11 C4 20 00 20 7D AA 17 37 33 C0 E0 5D 00 00 00 00 00
					15 00 00 40 00 00 02 6F 25
					39 00 00 40 00 00 08 C4 44 54 73 AA 17 37 00
					39 00 00 40 00 00 16 C5 2A 0F 0D 24 03 49 F2 DC 00 0A 36 88 00 01 BF 3C 7F FE 92 11 64
					15 00 00 40 00 00 02 6F 15
					39 00 00 40 00 00 11 C5 70 44 54 73 9A A4 16 33 0F 72 1F F2 32 00 00 00
					15 00 00 40 00 00 02 6F 25
					39 00 00 40 00 00 08 C5 00 00 00 00 00 00 00
					39 00 00 40 00 00 16 C6 2A 0F 01 E4 04 00 FA 80 00 01 20 30 00 04 15 60 7F FF 6D 54 00
					15 00 00 40 00 00 02 6F 15
					39 00 00 40 00 00 11 C6 00 34 FF 53 AA 17 37 33 0F 20 54 F5 80 00 00 00
					15 00 00 40 00 00 02 6F 25
					39 00 00 40 00 00 08 C6 00 00 00 00 00 00 00
					39 00 00 40 00 00 16 C7 26 00 02 40 04 84 06 60 00 00 64 00 3F FA 0B 00 00 00 00 00 00
					15 00 00 40 00 00 02 6F 15
					39 00 00 40 00 00 11 C7 1F 34 FC 54 00 00 20 33 30 20 A8 00 00 00 00 00
					15 00 00 40 00 00 02 6F 25
					39 00 00 40 00 00 08 C7 00 00 00 00 00 00 00
					39 00 00 40 00 00 16 C8 26 00 0B 64 02 A4 0A F8 00 03 D4 00 3F FC 2C 00 00 00 00 00 00
					15 00 00 40 00 00 02 6F 15
					39 00 00 40 00 00 11 C8 00 44 55 73 00 21 8F 33 30 6E E2 00 00 00 00 00
					15 00 00 40 00 00 02 6F 25
					39 00 00 40 00 00 08 C8 00 00 00 00 00 00 00
					39 00 00 40 00 00 16 C9 21 00 05 10 05 10 00 00 3F FE 93 80 3F FE 93 80 00 00 1C 84 20
					15 00 00 40 00 00 02 6F 15
					39 00 00 40 00 00 11 C9 0A 22 14 39 00 1C 41 55 F0 DC DC 05 10 F0 FF FF
					15 00 00 40 00 00 02 6F 25
					39 00 00 40 00 00 08 C9 00 00 00 00 00 00 00
					39 00 00 40 00 00 16 CA 27 00 05 10 05 10 00 00 00 00 00 00 3F FE 93 80 00 00 01 71 90
					15 00 00 40 00 00 02 6F 15
					39 00 00 40 00 00 11 CA 0A 22 3A 5F 00 1C 41 55 30 24 DC 00 00 C0 00 FF
					15 00 00 40 00 00 02 6F 25
					39 00 00 40 00 00 08 CA 00 00 00 00 00 00 00
					39 00 00 40 00 00 16 CB 2D 00 05 10 05 10 00 00 3F FE 93 80 00 00 00 00 00 00 01 71 90
					15 00 00 40 00 00 02 6F 15
					39 00 00 40 00 00 11 CB 19 22 14 39 00 42 67 55 C0 DC 24 00 00 30 FF 00
					15 00 00 40 00 00 02 6F 25
					39 00 00 40 00 00 08 CB 00 00 00 00 00 00 00
					39 00 00 40 00 00 16 CC 2B 00 05 10 05 10 00 00 00 00 00 00 00 00 00 00 7F FF E6 5F 00
					15 00 00 40 00 00 02 6F 15
					39 00 00 40 00 00 11 CC 19 22 3A 5F 00 42 67 55 0F 24 24 FA F0 00 00 00
					15 00 00 40 00 00 02 6F 25
					39 00 00 40 00 00 08 CC 00 00 00 00 00 00 00
					39 00 00 40 00 00 16 CD 00 00 00 00 00 00 00 00 00 00 00 00 00 00 00 00 00 00 00 00 00
					15 00 00 40 00 00 02 6F 15
					39 00 00 40 00 00 11 CD 00 00 00 00 00 00 00 00 00 00 00 00 00 00 00 00
					15 00 00 40 00 00 02 6F 25
					39 00 00 40 00 00 08 CD 00 00 00 00 00 00 00
					39 00 00 40 00 00 16 CE 00 00 00 00 00 00 00 00 00 00 00 00 00 00 00 00 00 00 00 00 00
					15 00 00 40 00 00 02 6F 15
					39 00 00 40 00 00 11 CE 00 00 00 00 00 00 00 00 00 00 00 00 00 00 00 00
					15 00 00 40 00 00 02 6F 25
					39 00 00 40 00 00 08 CE 00 00 00 00 00 00 00
					39 00 00 40 00 00 16 CF 00 00 00 00 00 00 00 00 00 00 00 00 00 00 00 00 00 00 00 00 00
					15 00 00 40 00 00 02 6F 15
					39 00 00 40 00 00 11 CF 00 00 00 00 00 00 00 00 00 00 00 00 00 00 00 00
					15 00 00 40 00 00 02 6F 25
					39 00 00 40 00 00 08 CF 00 00 00 00 00 00 00
					39 00 00 40 00 00 16 D0 00 00 00 00 00 00 00 00 00 00 00 00 00 00 00 00 00 00 00 00 00
					15 00 00 40 00 00 02 6F 15
					39 00 00 40 00 00 11 D0 00 00 00 00 00 00 00 00 00 00 00 00 00 00 00 00
					15 00 00 40 00 00 02 6F 25
					39 00 00 40 00 00 08 D0 00 00 00 00 00 00 00
					39 00 00 40 00 00 0F D1 80 00 00 00 00 04 73 80 00 00 00 00 04 73
					15 00 00 40 00 00 02 6F 0E
					39 00 00 40 00 00 0F D1 FF FE 70 57 49 04 73 FF FF 2A 07 00 04 73
					15 00 00 40 00 00 02 6F 1C
					39 00 00 40 00 00 0F D1 00 00 00 00 00 04 74 00 00 00 00 00 04 74
					15 00 00 40 00 00 02 6F 2A
					39 00 00 40 00 00 0C D1 00 00 66 70 00 04 74 00 00 9A E3
					39 00 00 00 00 00 12 D2 90 04 74 00 00 01 71 90 04 5C 00 00 1C 84 20 04 5C
					//SPR SETTING
					39 00 00 40 00 00 06 F0 55 AA 52 08 02
					15 00 00 40 00 00 02 C1 02
					39 00 00 40 00 00 05 C2 19 00 91 00
					39 00 00 40 00 00 06 F0 55 AA 52 08 03
					15 00 00 40 00 00 02 6F 08
					15 00 00 40 00 00 02 DE 00
					15 00 00 40 00 00 02 6F 09
					39 00 00 40 00 00 07 DE 30 14 25 10 34 25
					39 00 00 40 00 00 06 F0 55 AA 52 08 07
					39 00 00 40 00 00 06 B0 84 C4 00 00 40
					39 00 00 00 00 00 07 B1 08 18 00 18 08 00
					/*VDC setting only for EVT1 and before*/
					39 00 00 40 00 00 06 F0 55 AA 52 08 08
					39 00 00 40 00 00 02 6F 80
					39 00 00 40 00 00 0D B8 00 10 00 10 00 10 00 00 00 00 00 00
					39 00 00 00 00 00 11 E9 00 00 00 C5 18 94 0F E6 01 90 00 78 14 48 0F C6
					/*DDIC round corner*/
                    39 00 00 40 00 00 06 F0 55 AA 52 08 07
                    39 00 00 40 00 00 04 C0 07 01 F8
                    15 00 00 40 00 00 02 6F 03
                    39 00 00 40 00 00 05 C0 00 00 00 00
                    39 00 00 40 00 00 16 C1 36 00 03 49 0B 64 0C 3C 00 00 26 74 3F F3 88 64 00 00 00 00 00
                    15 00 00 40 00 00 02 6F 15
                    39 00 00 40 00 00 11 C1 1E 34 E1 51 00 00 1F 33 30 1F 90 00 00 00 00 00
                    15 00 00 40 00 00 02 6F 25
                    39 00 00 40 00 00 08 C1 44 52 73 00 00 1F 00
                    39 00 00 40 00 00 16 C2 36 00 0A 29 03 49 0B 8E 00 04 49 78 3F FB 6A D8 00 00 00 00 00
                    15 00 00 40 00 00 02 6F 15
                    39 00 00 40 00 00 11 C2 01 44 52 73 00 20 8D 33 30 6D DF 00 00 00 00 00
                    15 00 00 40 00 00 02 6F 25
                    39 00 00 40 00 00 08 C2 00 00 21 00 01 1F 00
                    39 00 00 40 00 00 16 C3 30 0F 0A 29 03 C1 F3 A6 3F F8 E6 92 3F FC A6 1A 00 00 BF 0E C5
                    15 00 00 40 00 00 02 6F 15
                    39 00 00 40 00 00 11 C3 02 00 00 21 00 20 8D 33 F0 93 DF 0E 0D 00 00 00
                    15 00 00 40 00 00 02 6F 25
                    39 00 00 40 00 00 08 C3 44 52 72 AA 18 37 00
                    39 00 00 40 00 00 16 C4 30 0F 03 C1 0B 64 F2 EC 3F FC B7 20 3F F8 AF E4 00 00 B7 F1 00
                    15 00 00 40 00 00 02 6F 15
                    39 00 00 40 00 00 11 C4 1D 00 22 92 00 00 1F 33 F0 E1 90 0D 90 00 00 00
                    15 00 00 40 00 00 02 6F 25
                    39 00 00 40 00 00 08 C4 00 00 21 AA 18 36 00
                    39 00 00 40 00 00 16 C5 2A 0F 03 49 0B 64 F3 C4 00 01 A1 B8 00 09 B5 64 7F FE A8 46 80
                    15 00 00 40 00 00 02 6F 15
                    39 00 00 40 00 00 11 C5 00 34 E1 51 AA 18 37 33 0F 1F 70 F2 70 00 00 00
                    15 00 00 40 00 00 02 6F 25
                    39 00 00 40 00 00 08 C5 00 00 00 00 00 00 00
                    39 00 00 40 00 00 16 C6 2A 0F 0A 29 03 49 F4 72 00 09 34 EE 00 01 C8 FE 7F FE A4 F4 E9
                    15 00 00 40 00 00 02 6F 15
                    39 00 00 40 00 00 11 C6 6B 44 52 73 9A AA 17 33 0F 6D 21 F1 F3 00 00 00
                    15 00 00 40 00 00 02 6F 25
                    39 00 00 40 00 00 08 C6 00 00 00 00 00 00 00
                    39 00 00 40 00 00 16 C7 2C 00 03 C1 0B 64 0D 14 3F FB 21 B4 00 04 8D E4 00 00 00 00 00
                    15 00 00 40 00 00 02 6F 15
                    39 00 00 40 00 00 11 C7 01 00 22 92 AA 18 37 33 C0 E1 70 00 00 00 00 00
                    15 00 00 40 00 00 02 6F 25
                    39 00 00 40 00 00 08 C7 00 00 00 00 00 00 00
                    39 00 00 40 00 00 16 C8 2C 00 0A 29 03 C1 0C 5A 3F F3 A4 40 00 00 27 8C 00 00 00 00 00
                    15 00 00 40 00 00 02 6F 15
                    39 00 00 40 00 00 11 C8 6A 00 00 21 9A AA 17 33 C0 93 21 00 00 00 00 00
                    15 00 00 40 00 00 02 6F 25
                    39 00 00 40 00 00 08 C8 00 00 00 00 00 00 00
                    39 00 00 40 00 00 16 C9 21 00 05 10 05 10 00 00 3F FE 93 80 3F FE 93 80 00 00 1C 84 20
                    15 00 00 40 00 00 02 6F 15
                    39 00 00 40 00 00 11 C9 0A 22 14 39 00 1C 41 55 F0 DC DC 05 10 F0 FF FF
                    15 00 00 40 00 00 02 6F 25
                    39 00 00 40 00 00 08 C9 00 00 00 00 00 00 00
                    39 00 00 40 00 00 16 CA 27 00 05 10 05 10 00 00 00 00 00 00 3F FE 93 80 00 00 01 71 90
                    15 00 00 40 00 00 02 6F 15
                    39 00 00 40 00 00 11 CA 0A 22 3A 5F 00 1C 41 55 30 24 DC 00 00 C0 00 FF
                    15 00 00 40 00 00 02 6F 25
                    39 00 00 40 00 00 08 CA 00 00 00 00 00 00 00
                    39 00 00 40 00 00 16 CB 2D 00 05 10 05 10 00 00 3F FE 93 80 00 00 00 00 00 00 01 71 90
                    15 00 00 40 00 00 02 6F 15
                    39 00 00 40 00 00 11 CB 19 22 14 39 00 42 67 55 C0 DC 24 00 00 30 FF 00
                    15 00 00 40 00 00 02 6F 25
                    39 00 00 40 00 00 08 CB 00 00 00 00 00 00 00
                    39 00 00 40 00 00 16 CC 2B 00 05 10 05 10 00 00 00 00 00 00 00 00 00 00 7F FF E6 5F 00
                    15 00 00 40 00 00 02 6F 15
                    39 00 00 40 00 00 11 CC 19 22 3A 5F 00 42 67 55 0F 24 24 FA F0 00 00 00
                    15 00 00 40 00 00 02 6F 25
                    39 00 00 40 00 00 08 CC 00 00 00 00 00 00 00
                    39 00 00 40 00 00 16 CD 00 00 00 00 00 00 00 00 00 00 00 00 00 00 00 00 00 00 00 00 00
                    15 00 00 40 00 00 02 6F 15
                    39 00 00 40 00 00 11 CD 00 00 00 00 00 00 00 00 00 00 00 00 00 00 00 00
                    15 00 00 40 00 00 02 6F 25
                    39 00 00 40 00 00 08 CD 00 00 00 00 00 00 00
                    39 00 00 40 00 00 16 CE 00 00 00 00 00 00 00 00 00 00 00 00 00 00 00 00 00 00 00 00 00
                    15 00 00 40 00 00 02 6F 15
                    39 00 00 40 00 00 11 CE 00 00 00 00 00 00 00 00 00 00 00 00 00 00 00 00
                    15 00 00 40 00 00 02 6F 25
                    39 00 00 40 00 00 08 CE 00 00 00 00 00 00 00
                    39 00 00 40 00 00 16 CF 00 00 00 00 00 00 00 00 00 00 00 00 00 00 00 00 00 00 00 00 00
                    15 00 00 40 00 00 02 6F 15
                    39 00 00 40 00 00 11 CF 00 00 00 00 00 00 00 00 00 00 00 00 00 00 00 00
                    15 00 00 40 00 00 02 6F 25
                    39 00 00 40 00 00 08 CF 00 00 00 00 00 00 00
                    39 00 00 40 00 00 16 D0 00 00 00 00 00 00 00 00 00 00 00 00 00 00 00 00 00 00 00 00 00
                    15 00 00 40 00 00 02 6F 15
                    39 00 00 40 00 00 11 D0 00 00 00 00 00 00 00 00 00 00 00 00 00 00 00 00
                    15 00 00 40 00 00 02 6F 25
                    39 00 00 40 00 00 08 D0 00 00 00 00 00 00 00
                    39 00 00 40 00 00 0F D1 00 00 B1 CB C0 04 74 00 00 B8 B0 E1 04 74
                    15 00 00 40 00 00 02 6F 0E
                    39 00 00 40 00 00 0F D1 00 00 00 00 00 00 00 00 00 00 00 00 00 00
                    15 00 00 40 00 00 02 6F 1C
                    39 00 00 40 00 00 0F D1 00 00 00 00 00 00 00 00 00 00 00 00 00 00
                    15 00 00 40 00 00 02 6F 2A
                    39 00 00 40 00 00 0C D1 7F FE 96 AF C0 00 00 7F FE 93 64
                    39 00 00 40 00 00 12 D2 A9 00 00 00 00 01 71 90 04 5C 00 00 1C 84 20 04 5C
                    39 00 00 40 00 00 06 F0 55 AA 52 08 00
                    15 00 00 40 00 00 02 6F 13
                    39 00 00 40 00 00 19 DF 00 00 00 00 00 00 00 00 00 00 00 00 00 00 00 00 00 00 00 00 00 00 00 00
                    39 00 00 00 00 00 0A 88 00 00 00 00 00 00 00 00 00
					39 00 00 40 00 00 06 F0 55 AA 52 08 00
					15 00 00 40 00 00 02 BE 54
					15 00 00 40 00 00 02 6F 08
					15 00 00 00 00 00 02 B2 C0
					/* Remove black insertion */
					39 00 00 40 00 00 06 F0 55 AA 52 08 01
					15 00 00 40 00 00 02 6F 01
					15 00 00 40 00 00 02 D2 00
					39 00 00 00 00 00 06 F0 55 AA 52 08 00
					/* Elvdd timing delay */
					39 00 00 40 00 00 06 F0 55 AA 52 08 01
					15 00 00 40 00 00 02 CD 61
					39 00 00 00 00 00 06 F0 55 AA 52 08 00
					/* Enable 60 to 30 */
					39 00 00 40 00 00 06 F0 55 AA 52 08 00
					15 00 00 40 00 00 02 6F 6E
					39 00 00 00 00 00 03 D1 FF FF
					/* Vin3 delay */
					39 00 00 40 00 00 06 F0 55 AA 52 08 01
					15 00 00 40 00 00 02 6F 00
					15 00 00 40 00 00 02 D8 40
					39 00 00 00 00 00 06 F0 55 AA 52 08 00
					/*sleep out*/
					05 00 00 00 78 00 01 11
					/*display on*/
					05 00 00 00 00 00 01 29
				];
				qcom,mdss-dsi-panel-info-switch-page-command = [
					/*read panel info switch page 01*/
					39 00 00 00 00 00 06 F0 55 AA 52 08 01
				];
				qcom,mdss-dsi-default-switch-page-command = [
					/*switch default page*/
					39 00 00 00 00 00 06 F0 55 AA 52 08 00
				];
				qcom,mdss-dsi-off-command = [
					05 00 00 00 14 00 01 28
					05 00 00 00 78 00 01 10
				];
				qcom,mdss-dsi-lp1-command = [
					/* AOD mode on */
					39 00 00 40 00 00 02 5F 00
					39 00 00 40 00 00 06 F0 55 AA 52 08 00
					15 00 00 40 00 00 02 2F 02
					05 00 00 40 00 00 01 39
					/* AOD Switch */
					15 00 00 40 00 00 02 6F 04
					39 00 00 00 00 00 03 51 09 D3
				];
				qcom,mdss-dsi-nolp-command = [
					/* AOD Mode OFF */
					05 00 00 40 00 00 01 38
					/* AOD OFF SEQ 3+18pulse*/
					15 00 00 40 00 00 02 5A 10
					15 00 00 40 00 00 02 6D 00
					15 00 00 00 00 00 02 2F 32
				];
				qcom,mdss-dsi-aod-high-mode-command = [
					/* AOD 50nit */
					15 00 00 40 00 00 02 6F 04
					39 00 00 00 00 00 03 51 09 D3
				];
				qcom,mdss-dsi-aod-low-mode-command = [
					/* AOD 10nit */
					15 00 00 40 00 00 02 6F 04
					39 00 00 00 00 00 03 51 00 03
				];
				qcom,mdss-dsi-ultra-low-power-aod-on-command = [
					39 00 00 40 00 00 06 F0 55 AA 52 08 00
					15 00 00 40 00 00 02 6F 08
					39 00 00 40 00 00 05 BB 01 00 00 00
					15 00 00 40 00 00 02 6F 0C
					39 00 00 40 00 00 05 BB 01 00 00 00
					15 00 00 40 00 00 02 6F 10
					39 00 00 40 00 00 05 BB 01 00 00 00
					15 00 00 40 00 00 02 6F 14
					39 00 00 40 00 00 05 BB 01 00 00 00
					15 00 00 40 00 00 02 6F 18
					39 00 00 40 00 00 06 BB 01 00 1D 1D 00
					15 00 00 40 00 00 02 6F 1D
					39 00 00 40 00 00 05 BB 01 00 00 00
					15 00 00 00 00 00 02 2F 30
				];
				qcom,mdss-dsi-ultra-low-power-aod-off-command = [
					39 00 00 40 00 00 06 F0 55 AA 52 08 00
					15 00 00 00 00 00 02 2F 02
				];
				qcom,mdss-dsi-loading-effect-1-command = [
					/* Loading On 100% */
					39 00 00 00 00 00 02 5F 00
				];
				qcom,mdss-dsi-loading-effect-2-command = [
					/* Loading On 110% */
					39 00 00 00 00 00 02 5F 01
				];
				qcom,mdss-dsi-loading-effect-3-command = [
				];
				qcom,mdss-dsi-loading-effect-4-command = [
				];
				qcom,mdss-dsi-loading-effect-off-command = [
					39 00 00 00 00 00 02 5F 02
				];
				qcom,mdss-dsi-loading-effect-1-command-state = "dsi_hs_mode";
				qcom,mdss-dsi-loading-effect-2-command-state = "dsi_hs_mode";
				qcom,mdss-dsi-loading-effect-3-command-state = "dsi_hs_mode";
				qcom,mdss-dsi-loading-effect-4-command-state = "dsi_hs_mode";
				qcom,mdss-dsi-timing-switch-command-state = "dsi_hs_mode";
				qcom,mdss-dsi-on-command-state = "dsi_lp_mode";
				qcom,mdss-dsi-optimize-on-command-state = "dsi_lp_mode";
				qcom,mdss-dsi-off-command-state = "dsi_hs_mode";
				qcom,mdss-dsi-panel-info-switch-page-command-state = "dsi_lp_mode";
				qcom,mdss-dsi-default-switch-page-command-state = "dsi_lp_mode";

				qcom,lm-split = <570 570>;
				qcom,compression-mode = "dsc";
				qcom,mdss-dsc-encoders = <2>;
				qcom,mdss-dsc-slice-height = <12>;
				qcom,mdss-dsc-slice-width = <570>;
				qcom,mdss-dsc-slice-per-pkt = <2>;
				qcom,mdss-dsc-bit-per-component = <10>;
				qcom,mdss-dsc-bit-per-pixel = <8>;
				qcom,mdss-dsc-block-prediction-enable;
				qcom,src-chroma-format = <1>;
				/* SPR CONFIG */
				qcom,spr-pack-type = "pentile";
			};
			timing@sa_fhd_90{
				cell-index = <1>;
				#include "dsi-panel-AC140-S-3-A0014-common.dtsi"
				qcom,mdss-mdp-transfer-time-us = <9000>;
				qcom,mdss-dsi-panel-jitter = <0x4 0x1>;
				qcom,mdss-dsc-version = <0x12>;
				qcom,mdss-dsi-timing-default;
				qcom,mdss-dsi-panel-framerate = <90>;
				qcom,mdss-dsi-panel-clockrate = <1113600000>;
				qcom,mdss-dsi-panel-width = <1140>;
				qcom,mdss-dsi-panel-height = <2616>;
				qcom,mdss-dsi-h-front-porch = <64>;
				qcom,mdss-dsi-h-back-porch = <80>;
				qcom,mdss-dsi-h-pulse-width = <8>;
				qcom,mdss-dsi-v-back-porch = <16>;
				qcom,mdss-dsi-v-front-porch = <10>;
				qcom,mdss-dsi-v-pulse-width = <2>;
				qcom,mdss-dsi-h-sync-pulse = <0>;

				qcom,mdss-dsi-h-left-border = <0>;
				qcom,mdss-dsi-h-right-border = <0>;
				qcom,mdss-dsi-v-top-border = <0>;
				qcom,mdss-dsi-v-bottom-border = <0>;
				qcom,dsi-mode-te-width-us = <3020>;

				/* Apollo vsync config, need to measure TE signal */
				//oplus,apollo-panel-vsync-width = <13000>;
				//oplus,apollo-panel-vsync-period = <16600>;

				oplus,fod-on-vblank = <0>;
				oplus,fod-off-vblank = <0>;

				qcom,mdss-dsi-timing-switch-command = [
					//Switch to 90Hz(3+18pulse)
					15 00 00 40 00 00 02 2F 01
					39 00 00 40 00 00 06 35 00 00 00 00 00
					15 00 00 00 0B 00 02 5A 10
					15 00 00 40 00 00 02 6D 08
					15 00 00 40 00 00 02 2F 31
					//Base 120hz(1+18pulse) SEQ Setting
					39 00 00 40 00 00 06 F0 55 AA 52 08 00
					15 00 00 40 00 00 02 6F 1C
					39 00 00 40 00 00 11 BA 01 00 00 00 00 00 00 00 00 00 00 00 00 00 00 00
					15 00 00 40 00 00 02 6F 2C
					39 00 00 40 00 00 11 BA 00 00 00 00 00 00 00 00 00 00 00 00 00 00 00 00
					15 00 00 40 00 00 02 6F 3C
					39 00 00 40 00 00 11 BA 00 00 00 00 00 00 00 00 00 00 00 00 00 00 00 00
					15 00 00 40 00 00 02 6F 4C
					39 00 00 40 00 00 11 BA 00 00 00 00 00 00 00 00 00 00 00 00 00 00 00 00
					15 00 00 40 00 00 02 6F 5C
					39 00 00 40 00 00 11 BA 01 01 01 01 01 01 01 01 01 01 01 01 01 01 01 01
					15 00 00 40 00 00 02 6F 6C
					39 00 00 40 00 00 09 BA 00 00 00 00 00 00 00 00
					15 00 00 40 00 00 02 6F 74
					39 00 00 40 00 00 11 BA 00 01 02 03 05 0B 17 77 00 02 05 08 11 59 00 00
					15 00 00 40 00 00 02 6F 84
					39 00 00 40 00 00 11 BA 00 01 02 03 05 0B 17 77 00 02 05 08 11 59 00 00
					15 00 00 40 00 00 02 6F 94
					39 00 00 40 00 00 11 BA 00 00 00 00 00 00 00 00 00 00 00 00 00 00 00 00
					15 00 00 40 00 00 02 6F A4
					39 00 00 40 00 00 11 BA 01 01 01 01 00 00 00 00 00 00 00 00 00 00 00 00
					15 00 00 40 00 00 02 6F B4
					39 00 00 40 00 00 05 BA 00 00 00 00
					15 00 00 40 00 00 02 6F B8
					39 00 00 40 00 00 09 BA 33 33 33 33 11 11 11 33
					15 00 00 40 00 00 02 6F C0
					39 00 00 00 00 00 09 BA 00 00 00 00 11 11 11 00
					];
				qcom,mdss-dsi-on-command = [
					39 00 00 40 00 00 06 F0 55 AA 52 08 00
					15 00 00 40 00 00 02 6F 03
					15 00 00 40 00 00 02 B5 65
					39 00 00 40 00 00 06 F0 55 AA 52 08 08
					15 00 00 40 00 00 02 6F 80
					39 00 00 40 00 00 0D B8 00 10 00 10 00 10 00 00 00 00 00 00
					39 00 00 00 00 00 11 E9 00 00 00 C5 18 94 0F E6 01 90 00 78 14 48 0F C6
					/* Drag optimization */
					39 00 00 40 00 00 06 F0 55 AA 52 08 08
					15 00 00 40 00 00 02 E0 31
					15 00 00 40 00 00 02 6F 05
					15 00 00 40 00 00 02 E0 20
					15 00 00 40 00 00 02 6F 02
					15 00 00 40 00 00 02 E1 05
					15 00 00 40 00 00 02 6F 02
					15 00 00 40 00 00 02 E2 0A
					15 00 00 40 00 00 02 6F 0E
					39 00 00 40 00 00 04 E1 00 00 0D
					15 00 00 40 00 00 02 6F 0E
					39 00 00 40 00 00 04 E2 02 06 13
					15 00 00 40 00 00 02 6F 0E
					39 00 00 40 00 00 04 E3 00 02 00
					15 00 00 40 00 00 02 6F 1E
					15 00 00 40 00 00 02 E1 00
					15 00 00 40 00 00 02 6F 1E
					15 00 00 40 00 00 02 E2 1C
					15 00 00 40 00 00 02 6F 2C
					15 00 00 40 00 00 02 E2 0A
					15 00 00 40 00 00 02 6F 2C
					15 00 00 40 00 00 02 E3 01
					15 00 00 40 00 00 02 6F 3A
					15 00 00 40 00 00 02 E1 04
					15 00 00 40 00 00 02 6F 3A
					15 00 00 40 00 00 02 E2 0B
					15 00 00 40 00 00 02 6F 48
					15 00 00 40 00 00 02 E2 06
					15 00 00 40 00 00 02 6F 48
					15 00 00 40 00 00 02 E3 04
					15 00 00 40 00 00 02 6F 56
					15 00 00 40 00 00 02 E2 06
					15 00 00 40 00 00 02 6F 56
					15 00 00 40 00 00 02 E3 04
					15 00 00 40 00 00 02 6F 64
					15 00 00 40 00 00 02 E2 04
					15 00 00 40 00 00 02 6F 64
					15 00 00 00 00 00 02 E3 01
					/* Power consumption optimization */
					39 00 00 40 00 00 06 F0 55 AA 52 08 03
					15 00 00 40 00 00 02 6F 33
					39 00 00 40 00 00 0B B0 00 00 00 00 00 00 00 00 00 00
					15 00 00 40 00 00 02 6F 3D
					39 00 00 40 00 00 0B B0 00 00 00 00 00 00 00 00 00 00
					15 00 00 40 00 00 02 6F 47
					39 00 00 40 00 00 0B B0 00 00 00 00 00 00 00 00 00 00
					15 00 00 40 00 00 02 6F 51
					39 00 00 40 00 00 0B B0 00 00 00 00 00 00 00 00 00 00
					15 00 00 40 00 00 02 6F 0C
					39 00 00 00 00 00 04 C3 44 00 04
					/*Common Setting*/
					39 00 00 40 00 00 06 F0 55 AA 52 08 00
					15 00 00 40 00 00 02 6F 5A
					39 00 00 00 00 00 08 D1 33 33 33 33 11 11 11
					39 00 00 40 00 00 06 F0 55 AA 52 08 01
					15 00 00 40 00 00 02 6F 03
					39 00 00 40 00 00 04 C5 00 24 24
					15 00 00 40 00 00 02 E5 00
					39 00 00 40 00 00 06 F0 55 AA 52 00 00
					39 00 00 40 00 00 05 FF AA 55 A5 80
					15 00 00 40 00 00 02 6F 16
					39 00 00 40 00 00 03 F4 02 74
					15 00 00 40 00 00 02 6F 31
					39 00 00 40 00 00 03 F8 01 73
					15 00 00 40 00 00 02 6F 15
					39 00 00 40 00 00 03 F8 01 8F
					15 00 00 40 00 00 02 6F 42
					15 00 00 40 00 00 02 F4 00
					15 00 00 40 00 00 02 6F 49
					15 00 00 40 00 00 02 F2 10
					39 00 00 40 00 00 05 FF AA 55 A5 81
					15 00 00 40 00 00 02 6F 0D
					15 00 00 40 00 00 02 FB 80
					15 00 00 40 00 00 02 6F 10
					15 00 00 40 00 00 02 FB 40
					15 00 00 40 00 00 02 6F 0C
					15 00 00 40 00 00 02 FD 08
					15 00 00 40 00 00 02 6F 05
					39 00 00 40 00 00 03 FE 3C 3C
					15 00 00 40 00 00 02 6F 0B
					15 00 00 40 00 00 02 FD 04
					39 00 00 40 00 00 05 FF AA 55 A5 82
					15 00 00 40 00 00 02 6F 09
					15 00 00 40 00 00 02 F2 FF
					39 00 00 40 00 00 05 FF AA 55 A5 83
					39 00 00 40 00 00 05 FF AA 55 A5 00
					05 00 00 00 00 00 01 35
					15 00 00 40 00 00 02 53 20
					39 00 00 40 00 00 05 2A 00 00 04 73
					39 00 00 40 00 00 05 2B 00 00 0A 37
					15 00 00 40 00 00 02 26 00
					39 00 00 00 00 00 03 81 01 19
					/*DSC Setting*/
					39 00 00 40 00 00 03 90 03 43
					39 00 00 00 00 00 13 91 A0 F0 00 0C D1 00 01 CC 00 50 00 2F 09 75 2D 7A 11 50
					//Switch to 90Hz(3+18pulse)
					15 00 00 40 00 00 02 2F 01
					39 00 00 40 00 00 06 35 00 00 00 00 00
					15 00 00 00 0B 00 02 5A 10
					15 00 00 40 00 00 02 6D 08
					15 00 00 40 00 00 02 2F 31
					//Base 120hz(1+18pulse) SEQ Setting
					39 00 00 40 00 00 06 F0 55 AA 52 08 00
					15 00 00 40 00 00 02 6F 1C
					39 00 00 40 00 00 11 BA 01 00 00 00 00 00 00 00 00 00 00 00 00 00 00 00
					15 00 00 40 00 00 02 6F 2C
					39 00 00 40 00 00 11 BA 00 00 00 00 00 00 00 00 00 00 00 00 00 00 00 00
					15 00 00 40 00 00 02 6F 3C
					39 00 00 40 00 00 11 BA 00 00 00 00 00 00 00 00 00 00 00 00 00 00 00 00
					15 00 00 40 00 00 02 6F 4C
					39 00 00 40 00 00 11 BA 00 00 00 00 00 00 00 00 00 00 00 00 00 00 00 00
					15 00 00 40 00 00 02 6F 5C
					39 00 00 40 00 00 11 BA 01 01 01 01 01 01 01 01 01 01 01 01 01 01 01 01
					15 00 00 40 00 00 02 6F 6C
					39 00 00 40 00 00 09 BA 00 00 00 00 00 00 00 00
					15 00 00 40 00 00 02 6F 74
					39 00 00 40 00 00 11 BA 00 01 02 03 05 0B 17 77 00 02 05 08 11 59 00 00
					15 00 00 40 00 00 02 6F 84
					39 00 00 40 00 00 11 BA 00 01 02 03 05 0B 17 77 00 02 05 08 11 59 00 00
					15 00 00 40 00 00 02 6F 94
					39 00 00 40 00 00 11 BA 00 00 00 00 00 00 00 00 00 00 00 00 00 00 00 00
					15 00 00 40 00 00 02 6F A4
					39 00 00 40 00 00 11 BA 01 01 01 01 00 00 00 00 00 00 00 00 00 00 00 00
					15 00 00 40 00 00 02 6F B4
					39 00 00 40 00 00 05 BA 00 00 00 00
					15 00 00 40 00 00 02 6F B8
					39 00 00 40 00 00 09 BA 33 33 33 33 11 11 11 33
					15 00 00 40 00 00 02 6F C0
					39 00 00 00 00 00 09 BA 00 00 00 00 11 11 11 00
					/* delay 8ms make sure pmic timing normal */
					39 00 00 40 00 00 06 F0 55 AA 52 08 00
					15 00 00 40 00 00 02 6F 02
					39 00 00 00 00 00 03 B5 2A 95
					/*add VDC code resolve 100%APL brightness */
					39 00 00 40 00 00 06 F0 55 AA 52 08 08
					39 00 00 40 00 00 11 BE 03 F1 00 5B 02 C0 03 C6 BA 6C 03 C6 BA 6C 03 59
					39 00 00 40 00 00 02 6F 10
					39 00 00 40 00 00 11 BE CA BA 03 59 CA BA 01 22 04 BA 01 22 04 BA 01 01
					39 00 00 40 00 00 02 6F 20
					39 00 00 00 00 00 11 BE 56 6B 01 01 56 6B 04 A9 BB B4 01 66 1E B6 80 64
					39 00 00 40 00 00 06 F0 55 AA 52 08 07
					39 00 00 40 00 00 04 C0 07 01 F8
					15 00 00 40 00 00 02 6F 03
					39 00 00 40 00 00 05 C0 00 00 00 00
					39 00 00 40 00 00 16 C1 30 0F 02 40 04 00 FA 00 3F FE 12 00 3F FC 52 00 00 00 65 C0 00
					15 00 00 40 00 00 02 6F 15
					39 00 00 40 00 00 11 C1 20 00 1F 77 00 00 20 33 F0 E0 A8 0B 00 00 00 00
					15 00 00 40 00 00 02 6F 25
					39 00 00 40 00 00 08 C1 00 00 1E 00 00 20 00
					39 00 00 40 00 00 16 C2 38 0F 06 40 02 40 F8 80 3F FB 3D 40 3F FD E9 A0 00 00 78 D9 80
					15 00 00 40 00 00 02 6F 15
					39 00 00 40 00 00 11 C2 64 00 00 1E 00 21 85 33 F0 9C E2 0B B8 00 00 00
					15 00 00 40 00 00 02 6F 25
					39 00 00 40 00 00 08 C2 44 55 73 00 00 20 00
					39 00 00 40 00 00 16 C3 3C 00 0E 89 03 C1 0E C6 3F F1 59 00 00 00 00 00 00 00 00 00 00
					15 00 00 40 00 00 02 6F 15
					39 00 00 40 00 00 11 C3 70 00 00 1F 9A A3 16 33 C0 8D 1F 00 00 00 00 00
					15 00 00 40 00 00 02 6F 25
					39 00 00 40 00 00 08 C3 00 00 1F AA 17 37 00
					39 00 00 40 00 00 16 C4 34 00 03 84 03 C1 07 44 3F FC 6C 0C 00 03 93 F4 00 00 00 00 00
					15 00 00 40 00 00 02 6F 15
					39 00 00 40 00 00 11 C4 20 00 20 7D AA 17 37 33 C0 E0 5D 00 00 00 00 00
					15 00 00 40 00 00 02 6F 25
					39 00 00 40 00 00 08 C4 44 54 73 AA 17 37 00
					39 00 00 40 00 00 16 C5 2A 0F 0D 24 03 49 F2 DC 00 0A 36 88 00 01 BF 3C 7F FE 92 11 64
					15 00 00 40 00 00 02 6F 15
					39 00 00 40 00 00 11 C5 70 44 54 73 9A A4 16 33 0F 72 1F F2 32 00 00 00
					15 00 00 40 00 00 02 6F 25
					39 00 00 40 00 00 08 C5 00 00 00 00 00 00 00
					39 00 00 40 00 00 16 C6 2A 0F 01 E4 04 00 FA 80 00 01 20 30 00 04 15 60 7F FF 6D 54 00
					15 00 00 40 00 00 02 6F 15
					39 00 00 40 00 00 11 C6 00 34 FF 53 AA 17 37 33 0F 20 54 F5 80 00 00 00
					15 00 00 40 00 00 02 6F 25
					39 00 00 40 00 00 08 C6 00 00 00 00 00 00 00
					39 00 00 40 00 00 16 C7 26 00 02 40 04 84 06 60 00 00 64 00 3F FA 0B 00 00 00 00 00 00
					15 00 00 40 00 00 02 6F 15
					39 00 00 40 00 00 11 C7 1F 34 FC 54 00 00 20 33 30 20 A8 00 00 00 00 00
					15 00 00 40 00 00 02 6F 25
					39 00 00 40 00 00 08 C7 00 00 00 00 00 00 00
					39 00 00 40 00 00 16 C8 26 00 0B 64 02 A4 0A F8 00 03 D4 00 3F FC 2C 00 00 00 00 00 00
					15 00 00 40 00 00 02 6F 15
					39 00 00 40 00 00 11 C8 00 44 55 73 00 21 8F 33 30 6E E2 00 00 00 00 00
					15 00 00 40 00 00 02 6F 25
					39 00 00 40 00 00 08 C8 00 00 00 00 00 00 00
					39 00 00 40 00 00 16 C9 21 00 05 10 05 10 00 00 3F FE 93 80 3F FE 93 80 00 00 1C 84 20
					15 00 00 40 00 00 02 6F 15
					39 00 00 40 00 00 11 C9 0A 22 14 39 00 1C 41 55 F0 DC DC 05 10 F0 FF FF
					15 00 00 40 00 00 02 6F 25
					39 00 00 40 00 00 08 C9 00 00 00 00 00 00 00
					39 00 00 40 00 00 16 CA 27 00 05 10 05 10 00 00 00 00 00 00 3F FE 93 80 00 00 01 71 90
					15 00 00 40 00 00 02 6F 15
					39 00 00 40 00 00 11 CA 0A 22 3A 5F 00 1C 41 55 30 24 DC 00 00 C0 00 FF
					15 00 00 40 00 00 02 6F 25
					39 00 00 40 00 00 08 CA 00 00 00 00 00 00 00
					39 00 00 40 00 00 16 CB 2D 00 05 10 05 10 00 00 3F FE 93 80 00 00 00 00 00 00 01 71 90
					15 00 00 40 00 00 02 6F 15
					39 00 00 40 00 00 11 CB 19 22 14 39 00 42 67 55 C0 DC 24 00 00 30 FF 00
					15 00 00 40 00 00 02 6F 25
					39 00 00 40 00 00 08 CB 00 00 00 00 00 00 00
					39 00 00 40 00 00 16 CC 2B 00 05 10 05 10 00 00 00 00 00 00 00 00 00 00 7F FF E6 5F 00
					15 00 00 40 00 00 02 6F 15
					39 00 00 40 00 00 11 CC 19 22 3A 5F 00 42 67 55 0F 24 24 FA F0 00 00 00
					15 00 00 40 00 00 02 6F 25
					39 00 00 40 00 00 08 CC 00 00 00 00 00 00 00
					39 00 00 40 00 00 16 CD 00 00 00 00 00 00 00 00 00 00 00 00 00 00 00 00 00 00 00 00 00
					15 00 00 40 00 00 02 6F 15
					39 00 00 40 00 00 11 CD 00 00 00 00 00 00 00 00 00 00 00 00 00 00 00 00
					15 00 00 40 00 00 02 6F 25
					39 00 00 40 00 00 08 CD 00 00 00 00 00 00 00
					39 00 00 40 00 00 16 CE 00 00 00 00 00 00 00 00 00 00 00 00 00 00 00 00 00 00 00 00 00
					15 00 00 40 00 00 02 6F 15
					39 00 00 40 00 00 11 CE 00 00 00 00 00 00 00 00 00 00 00 00 00 00 00 00
					15 00 00 40 00 00 02 6F 25
					39 00 00 40 00 00 08 CE 00 00 00 00 00 00 00
					39 00 00 40 00 00 16 CF 00 00 00 00 00 00 00 00 00 00 00 00 00 00 00 00 00 00 00 00 00
					15 00 00 40 00 00 02 6F 15
					39 00 00 40 00 00 11 CF 00 00 00 00 00 00 00 00 00 00 00 00 00 00 00 00
					15 00 00 40 00 00 02 6F 25
					39 00 00 40 00 00 08 CF 00 00 00 00 00 00 00
					39 00 00 40 00 00 16 D0 00 00 00 00 00 00 00 00 00 00 00 00 00 00 00 00 00 00 00 00 00
					15 00 00 40 00 00 02 6F 15
					39 00 00 40 00 00 11 D0 00 00 00 00 00 00 00 00 00 00 00 00 00 00 00 00
					15 00 00 40 00 00 02 6F 25
					39 00 00 40 00 00 08 D0 00 00 00 00 00 00 00
					39 00 00 40 00 00 0F D1 80 00 00 00 00 04 73 80 00 00 00 00 04 73
					15 00 00 40 00 00 02 6F 0E
					39 00 00 40 00 00 0F D1 FF FE 70 57 49 04 73 FF FF 2A 07 00 04 73
					15 00 00 40 00 00 02 6F 1C
					39 00 00 40 00 00 0F D1 00 00 00 00 00 04 74 00 00 00 00 00 04 74
					15 00 00 40 00 00 02 6F 2A
					39 00 00 40 00 00 0C D1 00 00 66 70 00 04 74 00 00 9A E3
					39 00 00 00 00 00 12 D2 90 04 74 00 00 01 71 90 04 5C 00 00 1C 84 20 04 5C
					//SPR SETTING
					39 00 00 40 00 00 06 F0 55 AA 52 08 02
					15 00 00 40 00 00 02 C1 02
					39 00 00 40 00 00 05 C2 19 00 91 00
					39 00 00 40 00 00 06 F0 55 AA 52 08 03
					15 00 00 40 00 00 02 6F 08
					15 00 00 40 00 00 02 DE 00
					15 00 00 40 00 00 02 6F 09
					39 00 00 40 00 00 07 DE 30 14 25 10 34 25
					39 00 00 40 00 00 06 F0 55 AA 52 08 07
					39 00 00 40 00 00 06 B0 84 C4 00 00 40
					39 00 00 00 00 00 07 B1 08 18 00 18 08 00
					/*VDC setting only for EVT1 and before*/
					39 00 00 40 00 00 06 F0 55 AA 52 08 08
					39 00 00 40 00 00 02 6F 80
					39 00 00 40 00 00 0D B8 00 10 00 10 00 10 00 00 00 00 00 00
					39 00 00 00 00 00 11 E9 00 00 00 C5 18 94 0F E6 01 90 00 78 14 48 0F C6
					/*DDIC round corner*/
                    39 00 00 40 00 00 06 F0 55 AA 52 08 07
                    39 00 00 40 00 00 04 C0 07 01 F8
                    15 00 00 40 00 00 02 6F 03
                    39 00 00 40 00 00 05 C0 00 00 00 00
                    39 00 00 40 00 00 16 C1 36 00 03 49 0B 64 0C 3C 00 00 26 74 3F F3 88 64 00 00 00 00 00
                    15 00 00 40 00 00 02 6F 15
                    39 00 00 40 00 00 11 C1 1E 34 E1 51 00 00 1F 33 30 1F 90 00 00 00 00 00
                    15 00 00 40 00 00 02 6F 25
                    39 00 00 40 00 00 08 C1 44 52 73 00 00 1F 00
                    39 00 00 40 00 00 16 C2 36 00 0A 29 03 49 0B 8E 00 04 49 78 3F FB 6A D8 00 00 00 00 00
                    15 00 00 40 00 00 02 6F 15
                    39 00 00 40 00 00 11 C2 01 44 52 73 00 20 8D 33 30 6D DF 00 00 00 00 00
                    15 00 00 40 00 00 02 6F 25
                    39 00 00 40 00 00 08 C2 00 00 21 00 01 1F 00
                    39 00 00 40 00 00 16 C3 30 0F 0A 29 03 C1 F3 A6 3F F8 E6 92 3F FC A6 1A 00 00 BF 0E C5
                    15 00 00 40 00 00 02 6F 15
                    39 00 00 40 00 00 11 C3 02 00 00 21 00 20 8D 33 F0 93 DF 0E 0D 00 00 00
                    15 00 00 40 00 00 02 6F 25
                    39 00 00 40 00 00 08 C3 44 52 72 AA 18 37 00
                    39 00 00 40 00 00 16 C4 30 0F 03 C1 0B 64 F2 EC 3F FC B7 20 3F F8 AF E4 00 00 B7 F1 00
                    15 00 00 40 00 00 02 6F 15
                    39 00 00 40 00 00 11 C4 1D 00 22 92 00 00 1F 33 F0 E1 90 0D 90 00 00 00
                    15 00 00 40 00 00 02 6F 25
                    39 00 00 40 00 00 08 C4 00 00 21 AA 18 36 00
                    39 00 00 40 00 00 16 C5 2A 0F 03 49 0B 64 F3 C4 00 01 A1 B8 00 09 B5 64 7F FE A8 46 80
                    15 00 00 40 00 00 02 6F 15
                    39 00 00 40 00 00 11 C5 00 34 E1 51 AA 18 37 33 0F 1F 70 F2 70 00 00 00
                    15 00 00 40 00 00 02 6F 25
                    39 00 00 40 00 00 08 C5 00 00 00 00 00 00 00
                    39 00 00 40 00 00 16 C6 2A 0F 0A 29 03 49 F4 72 00 09 34 EE 00 01 C8 FE 7F FE A4 F4 E9
                    15 00 00 40 00 00 02 6F 15
                    39 00 00 40 00 00 11 C6 6B 44 52 73 9A AA 17 33 0F 6D 21 F1 F3 00 00 00
                    15 00 00 40 00 00 02 6F 25
                    39 00 00 40 00 00 08 C6 00 00 00 00 00 00 00
                    39 00 00 40 00 00 16 C7 2C 00 03 C1 0B 64 0D 14 3F FB 21 B4 00 04 8D E4 00 00 00 00 00
                    15 00 00 40 00 00 02 6F 15
                    39 00 00 40 00 00 11 C7 01 00 22 92 AA 18 37 33 C0 E1 70 00 00 00 00 00
                    15 00 00 40 00 00 02 6F 25
                    39 00 00 40 00 00 08 C7 00 00 00 00 00 00 00
                    39 00 00 40 00 00 16 C8 2C 00 0A 29 03 C1 0C 5A 3F F3 A4 40 00 00 27 8C 00 00 00 00 00
                    15 00 00 40 00 00 02 6F 15
                    39 00 00 40 00 00 11 C8 6A 00 00 21 9A AA 17 33 C0 93 21 00 00 00 00 00
                    15 00 00 40 00 00 02 6F 25
                    39 00 00 40 00 00 08 C8 00 00 00 00 00 00 00
                    39 00 00 40 00 00 16 C9 21 00 05 10 05 10 00 00 3F FE 93 80 3F FE 93 80 00 00 1C 84 20
                    15 00 00 40 00 00 02 6F 15
                    39 00 00 40 00 00 11 C9 0A 22 14 39 00 1C 41 55 F0 DC DC 05 10 F0 FF FF
                    15 00 00 40 00 00 02 6F 25
                    39 00 00 40 00 00 08 C9 00 00 00 00 00 00 00
                    39 00 00 40 00 00 16 CA 27 00 05 10 05 10 00 00 00 00 00 00 3F FE 93 80 00 00 01 71 90
                    15 00 00 40 00 00 02 6F 15
                    39 00 00 40 00 00 11 CA 0A 22 3A 5F 00 1C 41 55 30 24 DC 00 00 C0 00 FF
                    15 00 00 40 00 00 02 6F 25
                    39 00 00 40 00 00 08 CA 00 00 00 00 00 00 00
                    39 00 00 40 00 00 16 CB 2D 00 05 10 05 10 00 00 3F FE 93 80 00 00 00 00 00 00 01 71 90
                    15 00 00 40 00 00 02 6F 15
                    39 00 00 40 00 00 11 CB 19 22 14 39 00 42 67 55 C0 DC 24 00 00 30 FF 00
                    15 00 00 40 00 00 02 6F 25
                    39 00 00 40 00 00 08 CB 00 00 00 00 00 00 00
                    39 00 00 40 00 00 16 CC 2B 00 05 10 05 10 00 00 00 00 00 00 00 00 00 00 7F FF E6 5F 00
                    15 00 00 40 00 00 02 6F 15
                    39 00 00 40 00 00 11 CC 19 22 3A 5F 00 42 67 55 0F 24 24 FA F0 00 00 00
                    15 00 00 40 00 00 02 6F 25
                    39 00 00 40 00 00 08 CC 00 00 00 00 00 00 00
                    39 00 00 40 00 00 16 CD 00 00 00 00 00 00 00 00 00 00 00 00 00 00 00 00 00 00 00 00 00
                    15 00 00 40 00 00 02 6F 15
                    39 00 00 40 00 00 11 CD 00 00 00 00 00 00 00 00 00 00 00 00 00 00 00 00
                    15 00 00 40 00 00 02 6F 25
                    39 00 00 40 00 00 08 CD 00 00 00 00 00 00 00
                    39 00 00 40 00 00 16 CE 00 00 00 00 00 00 00 00 00 00 00 00 00 00 00 00 00 00 00 00 00
                    15 00 00 40 00 00 02 6F 15
                    39 00 00 40 00 00 11 CE 00 00 00 00 00 00 00 00 00 00 00 00 00 00 00 00
                    15 00 00 40 00 00 02 6F 25
                    39 00 00 40 00 00 08 CE 00 00 00 00 00 00 00
                    39 00 00 40 00 00 16 CF 00 00 00 00 00 00 00 00 00 00 00 00 00 00 00 00 00 00 00 00 00
                    15 00 00 40 00 00 02 6F 15
                    39 00 00 40 00 00 11 CF 00 00 00 00 00 00 00 00 00 00 00 00 00 00 00 00
                    15 00 00 40 00 00 02 6F 25
                    39 00 00 40 00 00 08 CF 00 00 00 00 00 00 00
                    39 00 00 40 00 00 16 D0 00 00 00 00 00 00 00 00 00 00 00 00 00 00 00 00 00 00 00 00 00
                    15 00 00 40 00 00 02 6F 15
                    39 00 00 40 00 00 11 D0 00 00 00 00 00 00 00 00 00 00 00 00 00 00 00 00
                    15 00 00 40 00 00 02 6F 25
                    39 00 00 40 00 00 08 D0 00 00 00 00 00 00 00
                    39 00 00 40 00 00 0F D1 00 00 B1 CB C0 04 74 00 00 B8 B0 E1 04 74
                    15 00 00 40 00 00 02 6F 0E
                    39 00 00 40 00 00 0F D1 00 00 00 00 00 00 00 00 00 00 00 00 00 00
                    15 00 00 40 00 00 02 6F 1C
                    39 00 00 40 00 00 0F D1 00 00 00 00 00 00 00 00 00 00 00 00 00 00
                    15 00 00 40 00 00 02 6F 2A
                    39 00 00 40 00 00 0C D1 7F FE 96 AF C0 00 00 7F FE 93 64
                    39 00 00 40 00 00 12 D2 A9 00 00 00 00 01 71 90 04 5C 00 00 1C 84 20 04 5C
                    39 00 00 40 00 00 06 F0 55 AA 52 08 00
                    15 00 00 40 00 00 02 6F 13
                    39 00 00 40 00 00 19 DF 00 00 00 00 00 00 00 00 00 00 00 00 00 00 00 00 00 00 00 00 00 00 00 00
                    39 00 00 00 00 00 0A 88 00 00 00 00 00 00 00 00 00
					/* elvdd 4.8V */
					39 00 00 40 00 00 06 F0 55 AA 52 08 00
					15 00 00 40 00 00 02 6F 63
					15 00 00 00 00 00 02 D5 20
					39 00 00 40 00 00 06 F0 55 AA 52 08 00
					15 00 00 40 00 00 02 BE 54
					15 00 00 40 00 00 02 6F 08
					15 00 00 00 00 00 02 B2 C0
					/* Remove black insertion */
					39 00 00 40 00 00 06 F0 55 AA 52 08 01
					15 00 00 40 00 00 02 6F 01
					15 00 00 40 00 00 02 D2 00
					39 00 00 00 00 00 06 F0 55 AA 52 08 00
					/* Elvdd timing delay */
					39 00 00 40 00 00 06 F0 55 AA 52 08 01
					15 00 00 40 00 00 02 CD 61
					39 00 00 00 00 00 06 F0 55 AA 52 08 00
					/* Enable 60 to 30 */
					39 00 00 40 00 00 06 F0 55 AA 52 08 00
					15 00 00 40 00 00 02 6F 6E
					39 00 00 00 00 00 03 D1 FF FF
					/* Vin3 delay */
					39 00 00 40 00 00 06 F0 55 AA 52 08 01
					15 00 00 40 00 00 02 6F 00
					15 00 00 40 00 00 02 D8 40
					39 00 00 00 00 00 06 F0 55 AA 52 08 00
					/*sleep out*/
					05 00 00 00 78 00 01 11
					/*display on*/
					05 00 00 00 00 00 01 29
				];
				qcom,mdss-dsi-optimize-on-command = [
					39 00 00 40 00 00 06 F0 55 AA 52 08 00
					15 00 00 40 00 00 02 6F 03
					15 00 00 40 00 00 02 B5 65
					39 00 00 40 00 00 06 F0 55 AA 52 08 08
					15 00 00 40 00 00 02 6F 80
					39 00 00 40 00 00 0D B8 00 10 00 10 00 10 00 00 00 00 00 00
					39 00 00 40 00 00 11 E9 00 00 00 C5 18 94 0F E6 01 90 00 78 14 48 0F C6
					/*Common Setting*/
					39 00 00 40 00 00 06 F0 55 AA 52 08 00
					15 00 00 40 00 00 02 6F 5A
					39 00 00 00 00 00 08 D1 33 33 33 33 11 11 11
					39 00 00 40 00 00 06 F0 55 AA 52 08 01
					15 00 00 40 00 00 02 6F 03
					39 00 00 40 00 00 04 C5 00 24 24
					15 00 00 40 00 00 02 E5 00
					39 00 00 40 00 00 06 F0 55 AA 52 00 00
					39 00 00 40 00 00 05 FF AA 55 A5 80
					15 00 00 40 00 00 02 6F 16
					39 00 00 40 00 00 03 F4 02 74
					15 00 00 40 00 00 02 6F 31
					39 00 00 40 00 00 03 F8 01 73
					15 00 00 40 00 00 02 6F 15
					39 00 00 40 00 00 03 F8 01 8F
					15 00 00 40 00 00 02 6F 42
					15 00 00 40 00 00 02 F4 00
					15 00 00 40 00 00 02 6F 49
					15 00 00 40 00 00 02 F2 10
					39 00 00 40 00 00 05 FF AA 55 A5 81
					15 00 00 40 00 00 02 6F 0D
					15 00 00 40 00 00 02 FB 80
					15 00 00 40 00 00 02 6F 10
					15 00 00 40 00 00 02 FB 40
					15 00 00 40 00 00 02 6F 0C
					15 00 00 40 00 00 02 FD 08
					15 00 00 40 00 00 02 6F 05
					39 00 00 40 00 00 03 FE 3C 3C
					15 00 00 40 00 00 02 6F 0B
					15 00 00 40 00 00 02 FD 04
					39 00 00 40 00 00 05 FF AA 55 A5 82
					15 00 00 40 00 00 02 6F 09
					15 00 00 40 00 00 02 F2 FF
					39 00 00 40 00 00 05 FF AA 55 A5 83
					39 00 00 40 00 00 05 FF AA 55 A5 00
					05 00 00 00 00 00 01 35
					15 00 00 40 00 00 02 53 20
					39 00 00 40 00 00 05 2A 00 00 04 73
					39 00 00 40 00 00 05 2B 00 00 0A 37
					15 00 00 40 00 00 02 26 00
					39 00 00 00 00 00 03 81 01 19
					/*DSC Setting*/
					39 00 00 40 00 00 03 90 03 43
					39 00 00 00 00 00 13 91 A0 F0 00 0C D1 00 01 CC 00 50 00 2F 09 75 2D 7A 11 50
					//Switch to 90Hz(3+18pulse)
					15 00 00 40 00 00 02 2F 01
					39 00 00 40 00 00 06 35 00 00 00 00 00
					15 00 00 00 0B 00 02 5A 10
					15 00 00 40 00 00 02 6D 08
					15 00 00 40 00 00 02 2F 31
					//Base 120hz(1+18pulse) SEQ Setting
					39 00 00 40 00 00 06 F0 55 AA 52 08 00
					15 00 00 40 00 00 02 6F 1C
					39 00 00 40 00 00 11 BA 01 00 00 00 00 00 00 00 00 00 00 00 00 00 00 00
					15 00 00 40 00 00 02 6F 2C
					39 00 00 40 00 00 11 BA 00 00 00 00 00 00 00 00 00 00 00 00 00 00 00 00
					15 00 00 40 00 00 02 6F 3C
					39 00 00 40 00 00 11 BA 00 00 00 00 00 00 00 00 00 00 00 00 00 00 00 00
					15 00 00 40 00 00 02 6F 4C
					39 00 00 40 00 00 11 BA 00 00 00 00 00 00 00 00 00 00 00 00 00 00 00 00
					15 00 00 40 00 00 02 6F 5C
					39 00 00 40 00 00 11 BA 01 01 01 01 01 01 01 01 01 01 01 01 01 01 01 01
					15 00 00 40 00 00 02 6F 6C
					39 00 00 40 00 00 09 BA 00 00 00 00 00 00 00 00
					15 00 00 40 00 00 02 6F 74
					39 00 00 40 00 00 11 BA 00 01 02 03 05 0B 17 77 00 02 05 08 11 59 00 00
					15 00 00 40 00 00 02 6F 84
					39 00 00 40 00 00 11 BA 00 01 02 03 05 0B 17 77 00 02 05 08 11 59 00 00
					15 00 00 40 00 00 02 6F 94
					39 00 00 40 00 00 11 BA 00 00 00 00 00 00 00 00 00 00 00 00 00 00 00 00
					15 00 00 40 00 00 02 6F A4
					39 00 00 40 00 00 11 BA 01 01 01 01 00 00 00 00 00 00 00 00 00 00 00 00
					15 00 00 40 00 00 02 6F B4
					39 00 00 40 00 00 05 BA 00 00 00 00
					15 00 00 40 00 00 02 6F B8
					39 00 00 40 00 00 09 BA 33 33 33 33 11 11 11 33
					15 00 00 40 00 00 02 6F C0
					39 00 00 00 00 00 09 BA 00 00 00 00 11 11 11 00
					/* delay 8ms make sure pmic timing normal */
					39 00 00 40 00 00 06 F0 55 AA 52 08 00
					15 00 00 40 00 00 02 6F 02
					39 00 00 00 00 00 03 B5 2A 95
					/*add VDC code resolve 100%APL brightness */
					39 00 00 40 00 00 06 F0 55 AA 52 08 08
					39 00 00 40 00 00 11 BE 03 F1 00 5B 02 C0 03 C6 BA 6C 03 C6 BA 6C 03 59
					39 00 00 40 00 00 02 6F 10
					39 00 00 40 00 00 11 BE CA BA 03 59 CA BA 01 22 04 BA 01 22 04 BA 01 01
					39 00 00 40 00 00 02 6F 20
					39 00 00 00 00 00 11 BE 56 6B 01 01 56 6B 04 A9 BB B4 01 66 1E B6 80 64
					39 00 00 40 00 00 06 F0 55 AA 52 08 07
					39 00 00 40 00 00 04 C0 07 01 F8
					15 00 00 40 00 00 02 6F 03
					39 00 00 40 00 00 05 C0 00 00 00 00
					39 00 00 40 00 00 16 C1 30 0F 02 40 04 00 FA 00 3F FE 12 00 3F FC 52 00 00 00 65 C0 00
					15 00 00 40 00 00 02 6F 15
					39 00 00 40 00 00 11 C1 20 00 1F 77 00 00 20 33 F0 E0 A8 0B 00 00 00 00
					15 00 00 40 00 00 02 6F 25
					39 00 00 40 00 00 08 C1 00 00 1E 00 00 20 00
					39 00 00 40 00 00 16 C2 38 0F 06 40 02 40 F8 80 3F FB 3D 40 3F FD E9 A0 00 00 78 D9 80
					15 00 00 40 00 00 02 6F 15
					39 00 00 40 00 00 11 C2 64 00 00 1E 00 21 85 33 F0 9C E2 0B B8 00 00 00
					15 00 00 40 00 00 02 6F 25
					39 00 00 40 00 00 08 C2 44 55 73 00 00 20 00
					39 00 00 40 00 00 16 C3 3C 00 0E 89 03 C1 0E C6 3F F1 59 00 00 00 00 00 00 00 00 00 00
					15 00 00 40 00 00 02 6F 15
					39 00 00 40 00 00 11 C3 70 00 00 1F 9A A3 16 33 C0 8D 1F 00 00 00 00 00
					15 00 00 40 00 00 02 6F 25
					39 00 00 40 00 00 08 C3 00 00 1F AA 17 37 00
					39 00 00 40 00 00 16 C4 34 00 03 84 03 C1 07 44 3F FC 6C 0C 00 03 93 F4 00 00 00 00 00
					15 00 00 40 00 00 02 6F 15
					39 00 00 40 00 00 11 C4 20 00 20 7D AA 17 37 33 C0 E0 5D 00 00 00 00 00
					15 00 00 40 00 00 02 6F 25
					39 00 00 40 00 00 08 C4 44 54 73 AA 17 37 00
					39 00 00 40 00 00 16 C5 2A 0F 0D 24 03 49 F2 DC 00 0A 36 88 00 01 BF 3C 7F FE 92 11 64
					15 00 00 40 00 00 02 6F 15
					39 00 00 40 00 00 11 C5 70 44 54 73 9A A4 16 33 0F 72 1F F2 32 00 00 00
					15 00 00 40 00 00 02 6F 25
					39 00 00 40 00 00 08 C5 00 00 00 00 00 00 00
					39 00 00 40 00 00 16 C6 2A 0F 01 E4 04 00 FA 80 00 01 20 30 00 04 15 60 7F FF 6D 54 00
					15 00 00 40 00 00 02 6F 15
					39 00 00 40 00 00 11 C6 00 34 FF 53 AA 17 37 33 0F 20 54 F5 80 00 00 00
					15 00 00 40 00 00 02 6F 25
					39 00 00 40 00 00 08 C6 00 00 00 00 00 00 00
					39 00 00 40 00 00 16 C7 26 00 02 40 04 84 06 60 00 00 64 00 3F FA 0B 00 00 00 00 00 00
					15 00 00 40 00 00 02 6F 15
					39 00 00 40 00 00 11 C7 1F 34 FC 54 00 00 20 33 30 20 A8 00 00 00 00 00
					15 00 00 40 00 00 02 6F 25
					39 00 00 40 00 00 08 C7 00 00 00 00 00 00 00
					39 00 00 40 00 00 16 C8 26 00 0B 64 02 A4 0A F8 00 03 D4 00 3F FC 2C 00 00 00 00 00 00
					15 00 00 40 00 00 02 6F 15
					39 00 00 40 00 00 11 C8 00 44 55 73 00 21 8F 33 30 6E E2 00 00 00 00 00
					15 00 00 40 00 00 02 6F 25
					39 00 00 40 00 00 08 C8 00 00 00 00 00 00 00
					39 00 00 40 00 00 16 C9 21 00 05 10 05 10 00 00 3F FE 93 80 3F FE 93 80 00 00 1C 84 20
					15 00 00 40 00 00 02 6F 15
					39 00 00 40 00 00 11 C9 0A 22 14 39 00 1C 41 55 F0 DC DC 05 10 F0 FF FF
					15 00 00 40 00 00 02 6F 25
					39 00 00 40 00 00 08 C9 00 00 00 00 00 00 00
					39 00 00 40 00 00 16 CA 27 00 05 10 05 10 00 00 00 00 00 00 3F FE 93 80 00 00 01 71 90
					15 00 00 40 00 00 02 6F 15
					39 00 00 40 00 00 11 CA 0A 22 3A 5F 00 1C 41 55 30 24 DC 00 00 C0 00 FF
					15 00 00 40 00 00 02 6F 25
					39 00 00 40 00 00 08 CA 00 00 00 00 00 00 00
					39 00 00 40 00 00 16 CB 2D 00 05 10 05 10 00 00 3F FE 93 80 00 00 00 00 00 00 01 71 90
					15 00 00 40 00 00 02 6F 15
					39 00 00 40 00 00 11 CB 19 22 14 39 00 42 67 55 C0 DC 24 00 00 30 FF 00
					15 00 00 40 00 00 02 6F 25
					39 00 00 40 00 00 08 CB 00 00 00 00 00 00 00
					39 00 00 40 00 00 16 CC 2B 00 05 10 05 10 00 00 00 00 00 00 00 00 00 00 7F FF E6 5F 00
					15 00 00 40 00 00 02 6F 15
					39 00 00 40 00 00 11 CC 19 22 3A 5F 00 42 67 55 0F 24 24 FA F0 00 00 00
					15 00 00 40 00 00 02 6F 25
					39 00 00 40 00 00 08 CC 00 00 00 00 00 00 00
					39 00 00 40 00 00 16 CD 00 00 00 00 00 00 00 00 00 00 00 00 00 00 00 00 00 00 00 00 00
					15 00 00 40 00 00 02 6F 15
					39 00 00 40 00 00 11 CD 00 00 00 00 00 00 00 00 00 00 00 00 00 00 00 00
					15 00 00 40 00 00 02 6F 25
					39 00 00 40 00 00 08 CD 00 00 00 00 00 00 00
					39 00 00 40 00 00 16 CE 00 00 00 00 00 00 00 00 00 00 00 00 00 00 00 00 00 00 00 00 00
					15 00 00 40 00 00 02 6F 15
					39 00 00 40 00 00 11 CE 00 00 00 00 00 00 00 00 00 00 00 00 00 00 00 00
					15 00 00 40 00 00 02 6F 25
					39 00 00 40 00 00 08 CE 00 00 00 00 00 00 00
					39 00 00 40 00 00 16 CF 00 00 00 00 00 00 00 00 00 00 00 00 00 00 00 00 00 00 00 00 00
					15 00 00 40 00 00 02 6F 15
					39 00 00 40 00 00 11 CF 00 00 00 00 00 00 00 00 00 00 00 00 00 00 00 00
					15 00 00 40 00 00 02 6F 25
					39 00 00 40 00 00 08 CF 00 00 00 00 00 00 00
					39 00 00 40 00 00 16 D0 00 00 00 00 00 00 00 00 00 00 00 00 00 00 00 00 00 00 00 00 00
					15 00 00 40 00 00 02 6F 15
					39 00 00 40 00 00 11 D0 00 00 00 00 00 00 00 00 00 00 00 00 00 00 00 00
					15 00 00 40 00 00 02 6F 25
					39 00 00 40 00 00 08 D0 00 00 00 00 00 00 00
					39 00 00 40 00 00 0F D1 80 00 00 00 00 04 73 80 00 00 00 00 04 73
					15 00 00 40 00 00 02 6F 0E
					39 00 00 40 00 00 0F D1 FF FE 70 57 49 04 73 FF FF 2A 07 00 04 73
					15 00 00 40 00 00 02 6F 1C
					39 00 00 40 00 00 0F D1 00 00 00 00 00 04 74 00 00 00 00 00 04 74
					15 00 00 40 00 00 02 6F 2A
					39 00 00 40 00 00 0C D1 00 00 66 70 00 04 74 00 00 9A E3
					39 00 00 00 00 00 12 D2 90 04 74 00 00 01 71 90 04 5C 00 00 1C 84 20 04 5C
					//SPR SETTING
					39 00 00 40 00 00 06 F0 55 AA 52 08 02
					15 00 00 40 00 00 02 C1 02
					39 00 00 40 00 00 05 C2 19 00 91 00
					39 00 00 40 00 00 06 F0 55 AA 52 08 03
					15 00 00 40 00 00 02 6F 08
					15 00 00 40 00 00 02 DE 00
					15 00 00 40 00 00 02 6F 09
					39 00 00 40 00 00 07 DE 30 14 25 10 34 25
					39 00 00 40 00 00 06 F0 55 AA 52 08 07
					39 00 00 40 00 00 06 B0 84 C4 00 00 40
					39 00 00 00 00 00 07 B1 08 18 00 18 08 00
					/*VDC setting only for EVT1 and before*/
					39 00 00 40 00 00 06 F0 55 AA 52 08 08
					39 00 00 40 00 00 02 6F 80
					39 00 00 40 00 00 0D B8 00 10 00 10 00 10 00 00 00 00 00 00
					39 00 00 00 00 00 11 E9 00 00 00 C5 18 94 0F E6 01 90 00 78 14 48 0F C6
					/*DDIC round corner*/
                    39 00 00 40 00 00 06 F0 55 AA 52 08 07
                    39 00 00 40 00 00 04 C0 07 01 F8
                    15 00 00 40 00 00 02 6F 03
                    39 00 00 40 00 00 05 C0 00 00 00 00
                    39 00 00 40 00 00 16 C1 36 00 03 49 0B 64 0C 3C 00 00 26 74 3F F3 88 64 00 00 00 00 00
                    15 00 00 40 00 00 02 6F 15
                    39 00 00 40 00 00 11 C1 1E 34 E1 51 00 00 1F 33 30 1F 90 00 00 00 00 00
                    15 00 00 40 00 00 02 6F 25
                    39 00 00 40 00 00 08 C1 44 52 73 00 00 1F 00
                    39 00 00 40 00 00 16 C2 36 00 0A 29 03 49 0B 8E 00 04 49 78 3F FB 6A D8 00 00 00 00 00
                    15 00 00 40 00 00 02 6F 15
                    39 00 00 40 00 00 11 C2 01 44 52 73 00 20 8D 33 30 6D DF 00 00 00 00 00
                    15 00 00 40 00 00 02 6F 25
                    39 00 00 40 00 00 08 C2 00 00 21 00 01 1F 00
                    39 00 00 40 00 00 16 C3 30 0F 0A 29 03 C1 F3 A6 3F F8 E6 92 3F FC A6 1A 00 00 BF 0E C5
                    15 00 00 40 00 00 02 6F 15
                    39 00 00 40 00 00 11 C3 02 00 00 21 00 20 8D 33 F0 93 DF 0E 0D 00 00 00
                    15 00 00 40 00 00 02 6F 25
                    39 00 00 40 00 00 08 C3 44 52 72 AA 18 37 00
                    39 00 00 40 00 00 16 C4 30 0F 03 C1 0B 64 F2 EC 3F FC B7 20 3F F8 AF E4 00 00 B7 F1 00
                    15 00 00 40 00 00 02 6F 15
                    39 00 00 40 00 00 11 C4 1D 00 22 92 00 00 1F 33 F0 E1 90 0D 90 00 00 00
                    15 00 00 40 00 00 02 6F 25
                    39 00 00 40 00 00 08 C4 00 00 21 AA 18 36 00
                    39 00 00 40 00 00 16 C5 2A 0F 03 49 0B 64 F3 C4 00 01 A1 B8 00 09 B5 64 7F FE A8 46 80
                    15 00 00 40 00 00 02 6F 15
                    39 00 00 40 00 00 11 C5 00 34 E1 51 AA 18 37 33 0F 1F 70 F2 70 00 00 00
                    15 00 00 40 00 00 02 6F 25
                    39 00 00 40 00 00 08 C5 00 00 00 00 00 00 00
                    39 00 00 40 00 00 16 C6 2A 0F 0A 29 03 49 F4 72 00 09 34 EE 00 01 C8 FE 7F FE A4 F4 E9
                    15 00 00 40 00 00 02 6F 15
                    39 00 00 40 00 00 11 C6 6B 44 52 73 9A AA 17 33 0F 6D 21 F1 F3 00 00 00
                    15 00 00 40 00 00 02 6F 25
                    39 00 00 40 00 00 08 C6 00 00 00 00 00 00 00
                    39 00 00 40 00 00 16 C7 2C 00 03 C1 0B 64 0D 14 3F FB 21 B4 00 04 8D E4 00 00 00 00 00
                    15 00 00 40 00 00 02 6F 15
                    39 00 00 40 00 00 11 C7 01 00 22 92 AA 18 37 33 C0 E1 70 00 00 00 00 00
                    15 00 00 40 00 00 02 6F 25
                    39 00 00 40 00 00 08 C7 00 00 00 00 00 00 00
                    39 00 00 40 00 00 16 C8 2C 00 0A 29 03 C1 0C 5A 3F F3 A4 40 00 00 27 8C 00 00 00 00 00
                    15 00 00 40 00 00 02 6F 15
                    39 00 00 40 00 00 11 C8 6A 00 00 21 9A AA 17 33 C0 93 21 00 00 00 00 00
                    15 00 00 40 00 00 02 6F 25
                    39 00 00 40 00 00 08 C8 00 00 00 00 00 00 00
                    39 00 00 40 00 00 16 C9 21 00 05 10 05 10 00 00 3F FE 93 80 3F FE 93 80 00 00 1C 84 20
                    15 00 00 40 00 00 02 6F 15
                    39 00 00 40 00 00 11 C9 0A 22 14 39 00 1C 41 55 F0 DC DC 05 10 F0 FF FF
                    15 00 00 40 00 00 02 6F 25
                    39 00 00 40 00 00 08 C9 00 00 00 00 00 00 00
                    39 00 00 40 00 00 16 CA 27 00 05 10 05 10 00 00 00 00 00 00 3F FE 93 80 00 00 01 71 90
                    15 00 00 40 00 00 02 6F 15
                    39 00 00 40 00 00 11 CA 0A 22 3A 5F 00 1C 41 55 30 24 DC 00 00 C0 00 FF
                    15 00 00 40 00 00 02 6F 25
                    39 00 00 40 00 00 08 CA 00 00 00 00 00 00 00
                    39 00 00 40 00 00 16 CB 2D 00 05 10 05 10 00 00 3F FE 93 80 00 00 00 00 00 00 01 71 90
                    15 00 00 40 00 00 02 6F 15
                    39 00 00 40 00 00 11 CB 19 22 14 39 00 42 67 55 C0 DC 24 00 00 30 FF 00
                    15 00 00 40 00 00 02 6F 25
                    39 00 00 40 00 00 08 CB 00 00 00 00 00 00 00
                    39 00 00 40 00 00 16 CC 2B 00 05 10 05 10 00 00 00 00 00 00 00 00 00 00 7F FF E6 5F 00
                    15 00 00 40 00 00 02 6F 15
                    39 00 00 40 00 00 11 CC 19 22 3A 5F 00 42 67 55 0F 24 24 FA F0 00 00 00
                    15 00 00 40 00 00 02 6F 25
                    39 00 00 40 00 00 08 CC 00 00 00 00 00 00 00
                    39 00 00 40 00 00 16 CD 00 00 00 00 00 00 00 00 00 00 00 00 00 00 00 00 00 00 00 00 00
                    15 00 00 40 00 00 02 6F 15
                    39 00 00 40 00 00 11 CD 00 00 00 00 00 00 00 00 00 00 00 00 00 00 00 00
                    15 00 00 40 00 00 02 6F 25
                    39 00 00 40 00 00 08 CD 00 00 00 00 00 00 00
                    39 00 00 40 00 00 16 CE 00 00 00 00 00 00 00 00 00 00 00 00 00 00 00 00 00 00 00 00 00
                    15 00 00 40 00 00 02 6F 15
                    39 00 00 40 00 00 11 CE 00 00 00 00 00 00 00 00 00 00 00 00 00 00 00 00
                    15 00 00 40 00 00 02 6F 25
                    39 00 00 40 00 00 08 CE 00 00 00 00 00 00 00
                    39 00 00 40 00 00 16 CF 00 00 00 00 00 00 00 00 00 00 00 00 00 00 00 00 00 00 00 00 00
                    15 00 00 40 00 00 02 6F 15
                    39 00 00 40 00 00 11 CF 00 00 00 00 00 00 00 00 00 00 00 00 00 00 00 00
                    15 00 00 40 00 00 02 6F 25
                    39 00 00 40 00 00 08 CF 00 00 00 00 00 00 00
                    39 00 00 40 00 00 16 D0 00 00 00 00 00 00 00 00 00 00 00 00 00 00 00 00 00 00 00 00 00
                    15 00 00 40 00 00 02 6F 15
                    39 00 00 40 00 00 11 D0 00 00 00 00 00 00 00 00 00 00 00 00 00 00 00 00
                    15 00 00 40 00 00 02 6F 25
                    39 00 00 40 00 00 08 D0 00 00 00 00 00 00 00
                    39 00 00 40 00 00 0F D1 00 00 B1 CB C0 04 74 00 00 B8 B0 E1 04 74
                    15 00 00 40 00 00 02 6F 0E
                    39 00 00 40 00 00 0F D1 00 00 00 00 00 00 00 00 00 00 00 00 00 00
                    15 00 00 40 00 00 02 6F 1C
                    39 00 00 40 00 00 0F D1 00 00 00 00 00 00 00 00 00 00 00 00 00 00
                    15 00 00 40 00 00 02 6F 2A
                    39 00 00 40 00 00 0C D1 7F FE 96 AF C0 00 00 7F FE 93 64
                    39 00 00 40 00 00 12 D2 A9 00 00 00 00 01 71 90 04 5C 00 00 1C 84 20 04 5C
                    39 00 00 40 00 00 06 F0 55 AA 52 08 00
                    15 00 00 40 00 00 02 6F 13
                    39 00 00 40 00 00 19 DF 00 00 00 00 00 00 00 00 00 00 00 00 00 00 00 00 00 00 00 00 00 00 00 00
                    39 00 00 00 00 00 0A 88 00 00 00 00 00 00 00 00 00
					39 00 00 40 00 00 06 F0 55 AA 52 08 00
					15 00 00 40 00 00 02 BE 54
					15 00 00 40 00 00 02 6F 08
					15 00 00 00 00 00 02 B2 C0
					/* Remove black insertion */
					39 00 00 40 00 00 06 F0 55 AA 52 08 01
					15 00 00 40 00 00 02 6F 01
					15 00 00 40 00 00 02 D2 00
					39 00 00 00 00 00 06 F0 55 AA 52 08 00
					/* Elvdd timing delay */
					39 00 00 40 00 00 06 F0 55 AA 52 08 01
					15 00 00 40 00 00 02 CD 61
					39 00 00 00 00 00 06 F0 55 AA 52 08 00
					/* Enable 60 to 30 */
					39 00 00 40 00 00 06 F0 55 AA 52 08 00
					15 00 00 40 00 00 02 6F 6E
					39 00 00 00 00 00 03 D1 FF FF
					/* Vin3 delay */
					39 00 00 40 00 00 06 F0 55 AA 52 08 01
					15 00 00 40 00 00 02 6F 00
					15 00 00 40 00 00 02 D8 40
					39 00 00 00 00 00 06 F0 55 AA 52 08 00
					/*sleep out*/
					05 00 00 00 78 00 01 11
					/*display on*/
					05 00 00 00 00 00 01 29
				];
				qcom,mdss-dsi-panel-info-switch-page-command = [
					/*read panel info switch page 01*/
					39 00 00 00 00 00 06 F0 55 AA 52 08 01
				];
				qcom,mdss-dsi-default-switch-page-command = [
					/*switch default page*/
					39 00 00 00 00 00 06 F0 55 AA 52 08 00
				];
				qcom,mdss-dsi-off-command = [
					05 00 00 00 14 00 01 28
					05 00 00 00 78 00 01 10
				];
				qcom,mdss-dsi-lp1-command = [
					/* AOD mode on */
					39 00 00 40 00 00 02 5F 00
					39 00 00 40 00 00 06 F0 55 AA 52 08 00
					15 00 00 40 00 00 02 2F 01
					05 00 00 40 00 00 01 39
					/* AOD Switch */
					15 00 00 40 00 00 02 6F 04
					39 00 00 00 00 00 03 51 09 D3
				];
				qcom,mdss-dsi-nolp-command = [
					/* AOD Mode OFF */
					05 00 00 40 00 00 01 38
					/* AOD OFF SEQ 3+18pulse*/
					15 00 00 40 00 00 02 5A 10
					15 00 00 40 00 00 02 6D 08
					15 00 00 00 00 00 02 2F 31
				];
				qcom,mdss-dsi-aod-high-mode-command = [
					/* AOD 50nit */
					15 00 00 40 00 00 02 6F 04
					39 00 00 00 00 00 03 51 09 D3
				];
				qcom,mdss-dsi-aod-low-mode-command = [
					/* AOD 10nit */
					15 00 00 40 00 00 02 6F 04
					39 00 00 00 00 00 03 51 00 03
				];
				 qcom,mdss-dsi-ultra-low-power-aod-on-command = [
                                        39 00 00 40 00 00 06 F0 55 AA 52 08 00
                                        15 00 00 40 00 00 02 6F 08
                                        39 00 00 40 00 00 05 BB 01 00 00 00
                                        15 00 00 40 00 00 02 6F 0C
                                        39 00 00 40 00 00 05 BB 01 00 00 00
                                        15 00 00 40 00 00 02 6F 10
                                        39 00 00 40 00 00 05 BB 01 00 00 00
                                        15 00 00 40 00 00 02 6F 14
                                        39 00 00 40 00 00 05 BB 01 00 00 00
                                        15 00 00 40 00 00 02 6F 18
                                        39 00 00 40 00 00 06 BB 01 00 1D 1D 00
                                        15 00 00 40 00 00 02 6F 1D
                                        39 00 00 40 00 00 05 BB 01 00 00 00
                                        15 00 00 00 00 00 02 2F 30
                                ];
				qcom,mdss-dsi-ultra-low-power-aod-off-command = [
					39 00 00 40 00 00 06 F0 55 AA 52 08 00
					15 00 00 00 00 00 02 2F 02
				];
				qcom,mdss-dsi-loading-effect-1-command = [
					/* Loading On 100% */
					39 00 00 00 00 00 02 5F 00
				];
				qcom,mdss-dsi-loading-effect-2-command = [
					/* Loading On 110% */
					39 00 00 00 00 00 02 5F 01
				];
				qcom,mdss-dsi-loading-effect-3-command = [
				];
				qcom,mdss-dsi-loading-effect-4-command = [
				];
				qcom,mdss-dsi-loading-effect-off-command = [
					39 00 00 00 00 00 02 5F 02
				];
				qcom,mdss-dsi-loading-effect-1-command-state = "dsi_hs_mode";
				qcom,mdss-dsi-loading-effect-2-command-state = "dsi_hs_mode";
				qcom,mdss-dsi-loading-effect-3-command-state = "dsi_hs_mode";
				qcom,mdss-dsi-loading-effect-4-command-state = "dsi_hs_mode";
				qcom,mdss-dsi-timing-switch-command-state = "dsi_hs_mode";
				qcom,mdss-dsi-on-command-state = "dsi_lp_mode";
				qcom,mdss-dsi-optimize-on-command-state = "dsi_lp_mode";
				qcom,mdss-dsi-off-command-state = "dsi_hs_mode";
				qcom,mdss-dsi-panel-info-switch-page-command-state = "dsi_lp_mode";
				qcom,mdss-dsi-default-switch-page-command-state = "dsi_lp_mode";

				qcom,lm-split = <570 570>;
				qcom,compression-mode = "dsc";
				qcom,mdss-dsc-encoders = <2>;
				qcom,mdss-dsc-slice-height = <12>;
				qcom,mdss-dsc-slice-width = <570>;
				qcom,mdss-dsc-slice-per-pkt = <2>;
				qcom,mdss-dsc-bit-per-component = <10>;
				qcom,mdss-dsc-bit-per-pixel = <8>;
				qcom,mdss-dsc-block-prediction-enable;
				qcom,src-chroma-format = <1>;
				/* SPR CONFIG */
				qcom,spr-pack-type = "pentile";
			};
			timing@sa_fhd_60{
				cell-index = <2>;
				#include "dsi-panel-AC140-S-3-A0014-common.dtsi"
				qcom,mdss-mdp-transfer-time-us = <6900>;
				qcom,mdss-dsi-panel-jitter = <0x4 0x1>;
				qcom,mdss-dsc-version = <0x12>;
				qcom,mdss-dsi-timing-default;
				qcom,mdss-dsi-panel-framerate = <60>;
				qcom,mdss-dsi-panel-clockrate = <1113600000>;
				qcom,mdss-dsi-panel-width = <1140>;
				qcom,mdss-dsi-panel-height = <2616>;
				qcom,mdss-dsi-h-front-porch = <64>;
				qcom,mdss-dsi-h-back-porch = <50>;
				qcom,mdss-dsi-h-pulse-width = <8>;
				qcom,mdss-dsi-v-back-porch = <8>;
				qcom,mdss-dsi-v-front-porch = <2>;
				qcom,mdss-dsi-v-pulse-width = <2>;
				qcom,mdss-dsi-h-sync-pulse = <0>;

				qcom,mdss-dsi-h-left-border = <0>;
				qcom,mdss-dsi-h-right-border = <0>;
				qcom,mdss-dsi-v-top-border = <0>;
				qcom,mdss-dsi-v-bottom-border = <0>;
				qcom,dsi-mode-te-width-us = <270>;

				/* Apollo vsync config, need to measure TE signal */
				//oplus,apollo-panel-vsync-width = <13000>;
				//oplus,apollo-panel-vsync-period = <16600>;

				oplus,fod-on-vblank = <0>;
				oplus,fod-off-vblank = <0>;

				qcom,mdss-dsi-timing-switch-command = [
					//Switch to 60Hz(3+18pulse)
					15 00 00 40 00 00 02 2F 02
					39 00 00 40 00 00 06 35 00 00 00 00 01
					15 00 00 00 10 00 02 5A 10
					15 00 00 40 00 00 02 6D 01
					15 00 00 40 00 00 02 2F 32
					//Base 60hz(3+18) SEQ Setting
					39 00 00 40 00 00 06 F0 55 AA 52 08 00
					15 00 00 40 00 00 02 6F 1C
					39 00 00 40 00 00 11 BA 01 00 00 00 01 00 00 00 01 00 00 00 00 00 00 00
					15 00 00 40 00 00 02 6F 2C
					39 00 00 40 00 00 11 BA 00 00 00 00 00 00 00 00 00 00 00 00 00 00 00 00
					15 00 00 40 00 00 02 6F 3C
					39 00 00 40 00 00 11 BA 00 00 00 00 00 00 00 00 00 00 00 00 00 00 00 00
					15 00 00 40 00 00 02 6F 4C
					39 00 00 40 00 00 11 BA 00 00 00 00 00 00 00 00 00 00 00 00 00 00 00 00
					15 00 00 40 00 00 02 6F 5C
					39 00 00 40 00 00 11 BA 01 01 01 01 01 01 01 01 01 01 01 01 01 01 01 01
					15 00 00 40 00 00 02 6F 6C
					39 00 00 40 00 00 09 BA 00 00 00 00 00 00 00 00
					15 00 00 40 00 00 02 6F 74
					39 00 00 40 00 00 11 BA 01 01 02 03 05 0B 17 77 00 02 05 08 11 59 00 00
					15 00 00 40 00 00 02 6F 84
					39 00 00 40 00 00 11 BA 01 01 02 03 05 0B 17 77 01 02 05 08 11 59 00 00
					15 00 00 40 00 00 02 6F 94
					39 00 00 40 00 00 11 BA 00 00 00 00 00 00 00 00 00 00 00 00 00 00 00 00
					15 00 00 40 00 00 02 6F A4
					39 00 00 40 00 00 11 BA 01 01 01 01 00 00 00 00 00 00 00 00 00 00 00 00
					15 00 00 40 00 00 02 6F B4
					39 00 00 40 00 00 05 BA 00 00 00 00
					15 00 00 40 00 00 02 6F B8
					39 00 00 40 00 00 09 BA 22 22 22 22 11 11 11 22
					15 00 00 40 00 00 02 6F C0
					39 00 00 00 00 00 09 BA 22 22 22 22 11 11 11 22
					];
				qcom,mdss-dsi-on-command = [
					39 00 00 40 00 00 06 F0 55 AA 52 08 00
					15 00 00 40 00 00 02 6F 03
					15 00 00 40 00 00 02 B5 65
					39 00 00 40 00 00 06 F0 55 AA 52 08 08
					15 00 00 40 00 00 02 6F 80
					39 00 00 40 00 00 0D B8 00 10 00 10 00 10 00 00 00 00 00 00
					39 00 00 00 00 00 11 E9 00 00 00 C5 18 94 0F E6 01 90 00 78 14 48 0F C6
					/* Drag optimization */
					39 00 00 40 00 00 06 F0 55 AA 52 08 08
					15 00 00 40 00 00 02 E0 31
					15 00 00 40 00 00 02 6F 05
					15 00 00 40 00 00 02 E0 20
					15 00 00 40 00 00 02 6F 02
					15 00 00 40 00 00 02 E1 05
					15 00 00 40 00 00 02 6F 02
					15 00 00 40 00 00 02 E2 0A
					15 00 00 40 00 00 02 6F 0E
					39 00 00 40 00 00 04 E1 00 00 0D
					15 00 00 40 00 00 02 6F 0E
					39 00 00 40 00 00 04 E2 02 06 13
					15 00 00 40 00 00 02 6F 0E
					39 00 00 40 00 00 04 E3 00 02 00
					15 00 00 40 00 00 02 6F 1E
					15 00 00 40 00 00 02 E1 00
					15 00 00 40 00 00 02 6F 1E
					15 00 00 40 00 00 02 E2 1C
					15 00 00 40 00 00 02 6F 2C
					15 00 00 40 00 00 02 E2 0A
					15 00 00 40 00 00 02 6F 2C
					15 00 00 40 00 00 02 E3 01
					15 00 00 40 00 00 02 6F 3A
					15 00 00 40 00 00 02 E1 04
					15 00 00 40 00 00 02 6F 3A
					15 00 00 40 00 00 02 E2 0B
					15 00 00 40 00 00 02 6F 48
					15 00 00 40 00 00 02 E2 06
					15 00 00 40 00 00 02 6F 48
					15 00 00 40 00 00 02 E3 04
					15 00 00 40 00 00 02 6F 56
					15 00 00 40 00 00 02 E2 06
					15 00 00 40 00 00 02 6F 56
					15 00 00 40 00 00 02 E3 04
					15 00 00 40 00 00 02 6F 64
					15 00 00 40 00 00 02 E2 04
					15 00 00 40 00 00 02 6F 64
					15 00 00 00 00 00 02 E3 01
					/* Power consumption optimization */
					39 00 00 40 00 00 06 F0 55 AA 52 08 03
					15 00 00 40 00 00 02 6F 33
					39 00 00 40 00 00 0B B0 00 00 00 00 00 00 00 00 00 00
					15 00 00 40 00 00 02 6F 3D
					39 00 00 40 00 00 0B B0 00 00 00 00 00 00 00 00 00 00
					15 00 00 40 00 00 02 6F 47
					39 00 00 40 00 00 0B B0 00 00 00 00 00 00 00 00 00 00
					15 00 00 40 00 00 02 6F 51
					39 00 00 40 00 00 0B B0 00 00 00 00 00 00 00 00 00 00
					15 00 00 40 00 00 02 6F 0C
					39 00 00 00 00 00 04 C3 44 00 04
					/*Common Setting*/
					39 00 00 40 00 00 06 F0 55 AA 52 08 00
					15 00 00 40 00 00 02 6F 5A
					39 00 00 00 00 00 08 D1 33 33 33 33 11 11 11
					39 00 00 40 00 00 06 F0 55 AA 52 08 01
					15 00 00 40 00 00 02 6F 03
					39 00 00 40 00 00 04 C5 00 24 24
					15 00 00 40 00 00 02 E5 00
					39 00 00 40 00 00 06 F0 55 AA 52 00 00
					39 00 00 40 00 00 05 FF AA 55 A5 80
					15 00 00 40 00 00 02 6F 16
					39 00 00 40 00 00 03 F4 02 74
					15 00 00 40 00 00 02 6F 31
					39 00 00 40 00 00 03 F8 01 73
					15 00 00 40 00 00 02 6F 15
					39 00 00 40 00 00 03 F8 01 8F
					15 00 00 40 00 00 02 6F 42
					15 00 00 40 00 00 02 F4 00
					15 00 00 40 00 00 02 6F 49
					15 00 00 40 00 00 02 F2 10
					39 00 00 40 00 00 05 FF AA 55 A5 81
					15 00 00 40 00 00 02 6F 0D
					15 00 00 40 00 00 02 FB 80
					15 00 00 40 00 00 02 6F 10
					15 00 00 40 00 00 02 FB 40
					15 00 00 40 00 00 02 6F 0C
					15 00 00 40 00 00 02 FD 08
					15 00 00 40 00 00 02 6F 05
					39 00 00 40 00 00 03 FE 3C 3C
					15 00 00 40 00 00 02 6F 0B
					15 00 00 40 00 00 02 FD 04
					39 00 00 40 00 00 05 FF AA 55 A5 82
					15 00 00 40 00 00 02 6F 09
					15 00 00 40 00 00 02 F2 FF
					39 00 00 40 00 00 05 FF AA 55 A5 83
					39 00 00 40 00 00 05 FF AA 55 A5 00
					05 00 00 00 00 00 01 35
					15 00 00 40 00 00 02 53 20
					39 00 00 40 00 00 05 2A 00 00 04 73
					39 00 00 40 00 00 05 2B 00 00 0A 37
					15 00 00 40 00 00 02 26 00
					39 00 00 00 00 00 03 81 01 19
					/*DSC Setting*/
					39 00 00 40 00 00 03 90 03 43
					39 00 00 00 00 00 13 91 A0 F0 00 0C D1 00 01 CC 00 50 00 2F 09 75 2D 7A 11 50
					//Switch to 60Hz(3+18pulse)
					15 00 00 40 00 00 02 2F 02
					39 00 00 40 00 00 06 35 00 00 00 00 01
					15 00 00 00 10 00 02 5A 10
					15 00 00 40 00 00 02 6D 01
					15 00 00 40 00 00 02 2F 32
					//Base 60hz(3+18) SEQ Setting
					39 00 00 40 00 00 06 F0 55 AA 52 08 00
					15 00 00 40 00 00 02 6F 1C
					39 00 00 40 00 00 11 BA 01 00 00 00 01 00 00 00 01 00 00 00 00 00 00 00
					15 00 00 40 00 00 02 6F 2C
					39 00 00 40 00 00 11 BA 00 00 00 00 00 00 00 00 00 00 00 00 00 00 00 00
					15 00 00 40 00 00 02 6F 3C
					39 00 00 40 00 00 11 BA 00 00 00 00 00 00 00 00 00 00 00 00 00 00 00 00
					15 00 00 40 00 00 02 6F 4C
					39 00 00 40 00 00 11 BA 00 00 00 00 00 00 00 00 00 00 00 00 00 00 00 00
					15 00 00 40 00 00 02 6F 5C
					39 00 00 40 00 00 11 BA 01 01 01 01 01 01 01 01 01 01 01 01 01 01 01 01
					15 00 00 40 00 00 02 6F 6C
					39 00 00 40 00 00 09 BA 00 00 00 00 00 00 00 00
					15 00 00 40 00 00 02 6F 74
					39 00 00 40 00 00 11 BA 01 01 02 03 05 0B 17 77 00 02 05 08 11 59 00 00
					15 00 00 40 00 00 02 6F 84
					39 00 00 40 00 00 11 BA 01 01 02 03 05 0B 17 77 01 02 05 08 11 59 00 00
					15 00 00 40 00 00 02 6F 94
					39 00 00 40 00 00 11 BA 00 00 00 00 00 00 00 00 00 00 00 00 00 00 00 00
					15 00 00 40 00 00 02 6F A4
					39 00 00 40 00 00 11 BA 01 01 01 01 00 00 00 00 00 00 00 00 00 00 00 00
					15 00 00 40 00 00 02 6F B4
					39 00 00 40 00 00 05 BA 00 00 00 00
					15 00 00 40 00 00 02 6F B8
					39 00 00 40 00 00 09 BA 22 22 22 22 11 11 11 22
					15 00 00 40 00 00 02 6F C0
					39 00 00 00 00 00 09 BA 22 22 22 22 11 11 11 22
					/* delay 8ms make sure pmic timing normal */
					39 00 00 40 00 00 06 F0 55 AA 52 08 00
					15 00 00 40 00 00 02 6F 02
					39 00 00 00 00 00 03 B5 2A 95
					/*add VDC code resolve 100%APL brightness */
					39 00 00 40 00 00 06 F0 55 AA 52 08 08
					39 00 00 40 00 00 11 BE 03 F1 00 5B 02 C0 03 C6 BA 6C 03 C6 BA 6C 03 59
					39 00 00 40 00 00 02 6F 10
					39 00 00 40 00 00 11 BE CA BA 03 59 CA BA 01 22 04 BA 01 22 04 BA 01 01
					39 00 00 40 00 00 02 6F 20
					39 00 00 00 00 00 11 BE 56 6B 01 01 56 6B 04 A9 BB B4 01 66 1E B6 80 64
					39 00 00 40 00 00 06 F0 55 AA 52 08 07
					39 00 00 40 00 00 04 C0 07 01 F8
					15 00 00 40 00 00 02 6F 03
					39 00 00 40 00 00 05 C0 00 00 00 00
					39 00 00 40 00 00 16 C1 30 0F 02 40 04 00 FA 00 3F FE 12 00 3F FC 52 00 00 00 65 C0 00
					15 00 00 40 00 00 02 6F 15
					39 00 00 40 00 00 11 C1 20 00 1F 77 00 00 20 33 F0 E0 A8 0B 00 00 00 00
					15 00 00 40 00 00 02 6F 25
					39 00 00 40 00 00 08 C1 00 00 1E 00 00 20 00
					39 00 00 40 00 00 16 C2 38 0F 06 40 02 40 F8 80 3F FB 3D 40 3F FD E9 A0 00 00 78 D9 80
					15 00 00 40 00 00 02 6F 15
					39 00 00 40 00 00 11 C2 64 00 00 1E 00 21 85 33 F0 9C E2 0B B8 00 00 00
					15 00 00 40 00 00 02 6F 25
					39 00 00 40 00 00 08 C2 44 55 73 00 00 20 00
					39 00 00 40 00 00 16 C3 3C 00 0E 89 03 C1 0E C6 3F F1 59 00 00 00 00 00 00 00 00 00 00
					15 00 00 40 00 00 02 6F 15
					39 00 00 40 00 00 11 C3 70 00 00 1F 9A A3 16 33 C0 8D 1F 00 00 00 00 00
					15 00 00 40 00 00 02 6F 25
					39 00 00 40 00 00 08 C3 00 00 1F AA 17 37 00
					39 00 00 40 00 00 16 C4 34 00 03 84 03 C1 07 44 3F FC 6C 0C 00 03 93 F4 00 00 00 00 00
					15 00 00 40 00 00 02 6F 15
					39 00 00 40 00 00 11 C4 20 00 20 7D AA 17 37 33 C0 E0 5D 00 00 00 00 00
					15 00 00 40 00 00 02 6F 25
					39 00 00 40 00 00 08 C4 44 54 73 AA 17 37 00
					39 00 00 40 00 00 16 C5 2A 0F 0D 24 03 49 F2 DC 00 0A 36 88 00 01 BF 3C 7F FE 92 11 64
					15 00 00 40 00 00 02 6F 15
					39 00 00 40 00 00 11 C5 70 44 54 73 9A A4 16 33 0F 72 1F F2 32 00 00 00
					15 00 00 40 00 00 02 6F 25
					39 00 00 40 00 00 08 C5 00 00 00 00 00 00 00
					39 00 00 40 00 00 16 C6 2A 0F 01 E4 04 00 FA 80 00 01 20 30 00 04 15 60 7F FF 6D 54 00
					15 00 00 40 00 00 02 6F 15
					39 00 00 40 00 00 11 C6 00 34 FF 53 AA 17 37 33 0F 20 54 F5 80 00 00 00
					15 00 00 40 00 00 02 6F 25
					39 00 00 40 00 00 08 C6 00 00 00 00 00 00 00
					39 00 00 40 00 00 16 C7 26 00 02 40 04 84 06 60 00 00 64 00 3F FA 0B 00 00 00 00 00 00
					15 00 00 40 00 00 02 6F 15
					39 00 00 40 00 00 11 C7 1F 34 FC 54 00 00 20 33 30 20 A8 00 00 00 00 00
					15 00 00 40 00 00 02 6F 25
					39 00 00 40 00 00 08 C7 00 00 00 00 00 00 00
					39 00 00 40 00 00 16 C8 26 00 0B 64 02 A4 0A F8 00 03 D4 00 3F FC 2C 00 00 00 00 00 00
					15 00 00 40 00 00 02 6F 15
					39 00 00 40 00 00 11 C8 00 44 55 73 00 21 8F 33 30 6E E2 00 00 00 00 00
					15 00 00 40 00 00 02 6F 25
					39 00 00 40 00 00 08 C8 00 00 00 00 00 00 00
					39 00 00 40 00 00 16 C9 21 00 05 10 05 10 00 00 3F FE 93 80 3F FE 93 80 00 00 1C 84 20
					15 00 00 40 00 00 02 6F 15
					39 00 00 40 00 00 11 C9 0A 22 14 39 00 1C 41 55 F0 DC DC 05 10 F0 FF FF
					15 00 00 40 00 00 02 6F 25
					39 00 00 40 00 00 08 C9 00 00 00 00 00 00 00
					39 00 00 40 00 00 16 CA 27 00 05 10 05 10 00 00 00 00 00 00 3F FE 93 80 00 00 01 71 90
					15 00 00 40 00 00 02 6F 15
					39 00 00 40 00 00 11 CA 0A 22 3A 5F 00 1C 41 55 30 24 DC 00 00 C0 00 FF
					15 00 00 40 00 00 02 6F 25
					39 00 00 40 00 00 08 CA 00 00 00 00 00 00 00
					39 00 00 40 00 00 16 CB 2D 00 05 10 05 10 00 00 3F FE 93 80 00 00 00 00 00 00 01 71 90
					15 00 00 40 00 00 02 6F 15
					39 00 00 40 00 00 11 CB 19 22 14 39 00 42 67 55 C0 DC 24 00 00 30 FF 00
					15 00 00 40 00 00 02 6F 25
					39 00 00 40 00 00 08 CB 00 00 00 00 00 00 00
					39 00 00 40 00 00 16 CC 2B 00 05 10 05 10 00 00 00 00 00 00 00 00 00 00 7F FF E6 5F 00
					15 00 00 40 00 00 02 6F 15
					39 00 00 40 00 00 11 CC 19 22 3A 5F 00 42 67 55 0F 24 24 FA F0 00 00 00
					15 00 00 40 00 00 02 6F 25
					39 00 00 40 00 00 08 CC 00 00 00 00 00 00 00
					39 00 00 40 00 00 16 CD 00 00 00 00 00 00 00 00 00 00 00 00 00 00 00 00 00 00 00 00 00
					15 00 00 40 00 00 02 6F 15
					39 00 00 40 00 00 11 CD 00 00 00 00 00 00 00 00 00 00 00 00 00 00 00 00
					15 00 00 40 00 00 02 6F 25
					39 00 00 40 00 00 08 CD 00 00 00 00 00 00 00
					39 00 00 40 00 00 16 CE 00 00 00 00 00 00 00 00 00 00 00 00 00 00 00 00 00 00 00 00 00
					15 00 00 40 00 00 02 6F 15
					39 00 00 40 00 00 11 CE 00 00 00 00 00 00 00 00 00 00 00 00 00 00 00 00
					15 00 00 40 00 00 02 6F 25
					39 00 00 40 00 00 08 CE 00 00 00 00 00 00 00
					39 00 00 40 00 00 16 CF 00 00 00 00 00 00 00 00 00 00 00 00 00 00 00 00 00 00 00 00 00
					15 00 00 40 00 00 02 6F 15
					39 00 00 40 00 00 11 CF 00 00 00 00 00 00 00 00 00 00 00 00 00 00 00 00
					15 00 00 40 00 00 02 6F 25
					39 00 00 40 00 00 08 CF 00 00 00 00 00 00 00
					39 00 00 40 00 00 16 D0 00 00 00 00 00 00 00 00 00 00 00 00 00 00 00 00 00 00 00 00 00
					15 00 00 40 00 00 02 6F 15
					39 00 00 40 00 00 11 D0 00 00 00 00 00 00 00 00 00 00 00 00 00 00 00 00
					15 00 00 40 00 00 02 6F 25
					39 00 00 40 00 00 08 D0 00 00 00 00 00 00 00
					39 00 00 40 00 00 0F D1 80 00 00 00 00 04 73 80 00 00 00 00 04 73
					15 00 00 40 00 00 02 6F 0E
					39 00 00 40 00 00 0F D1 FF FE 70 57 49 04 73 FF FF 2A 07 00 04 73
					15 00 00 40 00 00 02 6F 1C
					39 00 00 40 00 00 0F D1 00 00 00 00 00 04 74 00 00 00 00 00 04 74
					15 00 00 40 00 00 02 6F 2A
					39 00 00 40 00 00 0C D1 00 00 66 70 00 04 74 00 00 9A E3
					39 00 00 00 00 00 12 D2 90 04 74 00 00 01 71 90 04 5C 00 00 1C 84 20 04 5C
					//SPR SETTING
					39 00 00 40 00 00 06 F0 55 AA 52 08 02
					15 00 00 40 00 00 02 C1 02
					39 00 00 40 00 00 05 C2 19 00 91 00
					39 00 00 40 00 00 06 F0 55 AA 52 08 03
					15 00 00 40 00 00 02 6F 08
					15 00 00 40 00 00 02 DE 00
					15 00 00 40 00 00 02 6F 09
					39 00 00 40 00 00 07 DE 30 14 25 10 34 25
					39 00 00 40 00 00 06 F0 55 AA 52 08 07
					39 00 00 40 00 00 06 B0 84 C4 00 00 40
					39 00 00 00 00 00 07 B1 08 18 00 18 08 00
					/*VDC setting only for EVT1 and before*/
					39 00 00 40 00 00 06 F0 55 AA 52 08 08
					39 00 00 40 00 00 02 6F 80
					39 00 00 40 00 00 0D B8 00 10 00 10 00 10 00 00 00 00 00 00
					39 00 00 00 00 00 11 E9 00 00 00 C5 18 94 0F E6 01 90 00 78 14 48 0F C6
					/*DDIC round corner*/
                    39 00 00 40 00 00 06 F0 55 AA 52 08 07
                    39 00 00 40 00 00 04 C0 07 01 F8
                    15 00 00 40 00 00 02 6F 03
                    39 00 00 40 00 00 05 C0 00 00 00 00
                    39 00 00 40 00 00 16 C1 36 00 03 49 0B 64 0C 3C 00 00 26 74 3F F3 88 64 00 00 00 00 00
                    15 00 00 40 00 00 02 6F 15
                    39 00 00 40 00 00 11 C1 1E 34 E1 51 00 00 1F 33 30 1F 90 00 00 00 00 00
                    15 00 00 40 00 00 02 6F 25
                    39 00 00 40 00 00 08 C1 44 52 73 00 00 1F 00
                    39 00 00 40 00 00 16 C2 36 00 0A 29 03 49 0B 8E 00 04 49 78 3F FB 6A D8 00 00 00 00 00
                    15 00 00 40 00 00 02 6F 15
                    39 00 00 40 00 00 11 C2 01 44 52 73 00 20 8D 33 30 6D DF 00 00 00 00 00
                    15 00 00 40 00 00 02 6F 25
                    39 00 00 40 00 00 08 C2 00 00 21 00 01 1F 00
                    39 00 00 40 00 00 16 C3 30 0F 0A 29 03 C1 F3 A6 3F F8 E6 92 3F FC A6 1A 00 00 BF 0E C5
                    15 00 00 40 00 00 02 6F 15
                    39 00 00 40 00 00 11 C3 02 00 00 21 00 20 8D 33 F0 93 DF 0E 0D 00 00 00
                    15 00 00 40 00 00 02 6F 25
                    39 00 00 40 00 00 08 C3 44 52 72 AA 18 37 00
                    39 00 00 40 00 00 16 C4 30 0F 03 C1 0B 64 F2 EC 3F FC B7 20 3F F8 AF E4 00 00 B7 F1 00
                    15 00 00 40 00 00 02 6F 15
                    39 00 00 40 00 00 11 C4 1D 00 22 92 00 00 1F 33 F0 E1 90 0D 90 00 00 00
                    15 00 00 40 00 00 02 6F 25
                    39 00 00 40 00 00 08 C4 00 00 21 AA 18 36 00
                    39 00 00 40 00 00 16 C5 2A 0F 03 49 0B 64 F3 C4 00 01 A1 B8 00 09 B5 64 7F FE A8 46 80
                    15 00 00 40 00 00 02 6F 15
                    39 00 00 40 00 00 11 C5 00 34 E1 51 AA 18 37 33 0F 1F 70 F2 70 00 00 00
                    15 00 00 40 00 00 02 6F 25
                    39 00 00 40 00 00 08 C5 00 00 00 00 00 00 00
                    39 00 00 40 00 00 16 C6 2A 0F 0A 29 03 49 F4 72 00 09 34 EE 00 01 C8 FE 7F FE A4 F4 E9
                    15 00 00 40 00 00 02 6F 15
                    39 00 00 40 00 00 11 C6 6B 44 52 73 9A AA 17 33 0F 6D 21 F1 F3 00 00 00
                    15 00 00 40 00 00 02 6F 25
                    39 00 00 40 00 00 08 C6 00 00 00 00 00 00 00
                    39 00 00 40 00 00 16 C7 2C 00 03 C1 0B 64 0D 14 3F FB 21 B4 00 04 8D E4 00 00 00 00 00
                    15 00 00 40 00 00 02 6F 15
                    39 00 00 40 00 00 11 C7 01 00 22 92 AA 18 37 33 C0 E1 70 00 00 00 00 00
                    15 00 00 40 00 00 02 6F 25
                    39 00 00 40 00 00 08 C7 00 00 00 00 00 00 00
                    39 00 00 40 00 00 16 C8 2C 00 0A 29 03 C1 0C 5A 3F F3 A4 40 00 00 27 8C 00 00 00 00 00
                    15 00 00 40 00 00 02 6F 15
                    39 00 00 40 00 00 11 C8 6A 00 00 21 9A AA 17 33 C0 93 21 00 00 00 00 00
                    15 00 00 40 00 00 02 6F 25
                    39 00 00 40 00 00 08 C8 00 00 00 00 00 00 00
                    39 00 00 40 00 00 16 C9 21 00 05 10 05 10 00 00 3F FE 93 80 3F FE 93 80 00 00 1C 84 20
                    15 00 00 40 00 00 02 6F 15
                    39 00 00 40 00 00 11 C9 0A 22 14 39 00 1C 41 55 F0 DC DC 05 10 F0 FF FF
                    15 00 00 40 00 00 02 6F 25
                    39 00 00 40 00 00 08 C9 00 00 00 00 00 00 00
                    39 00 00 40 00 00 16 CA 27 00 05 10 05 10 00 00 00 00 00 00 3F FE 93 80 00 00 01 71 90
                    15 00 00 40 00 00 02 6F 15
                    39 00 00 40 00 00 11 CA 0A 22 3A 5F 00 1C 41 55 30 24 DC 00 00 C0 00 FF
                    15 00 00 40 00 00 02 6F 25
                    39 00 00 40 00 00 08 CA 00 00 00 00 00 00 00
                    39 00 00 40 00 00 16 CB 2D 00 05 10 05 10 00 00 3F FE 93 80 00 00 00 00 00 00 01 71 90
                    15 00 00 40 00 00 02 6F 15
                    39 00 00 40 00 00 11 CB 19 22 14 39 00 42 67 55 C0 DC 24 00 00 30 FF 00
                    15 00 00 40 00 00 02 6F 25
                    39 00 00 40 00 00 08 CB 00 00 00 00 00 00 00
                    39 00 00 40 00 00 16 CC 2B 00 05 10 05 10 00 00 00 00 00 00 00 00 00 00 7F FF E6 5F 00
                    15 00 00 40 00 00 02 6F 15
                    39 00 00 40 00 00 11 CC 19 22 3A 5F 00 42 67 55 0F 24 24 FA F0 00 00 00
                    15 00 00 40 00 00 02 6F 25
                    39 00 00 40 00 00 08 CC 00 00 00 00 00 00 00
                    39 00 00 40 00 00 16 CD 00 00 00 00 00 00 00 00 00 00 00 00 00 00 00 00 00 00 00 00 00
                    15 00 00 40 00 00 02 6F 15
                    39 00 00 40 00 00 11 CD 00 00 00 00 00 00 00 00 00 00 00 00 00 00 00 00
                    15 00 00 40 00 00 02 6F 25
                    39 00 00 40 00 00 08 CD 00 00 00 00 00 00 00
                    39 00 00 40 00 00 16 CE 00 00 00 00 00 00 00 00 00 00 00 00 00 00 00 00 00 00 00 00 00
                    15 00 00 40 00 00 02 6F 15
                    39 00 00 40 00 00 11 CE 00 00 00 00 00 00 00 00 00 00 00 00 00 00 00 00
                    15 00 00 40 00 00 02 6F 25
                    39 00 00 40 00 00 08 CE 00 00 00 00 00 00 00
                    39 00 00 40 00 00 16 CF 00 00 00 00 00 00 00 00 00 00 00 00 00 00 00 00 00 00 00 00 00
                    15 00 00 40 00 00 02 6F 15
                    39 00 00 40 00 00 11 CF 00 00 00 00 00 00 00 00 00 00 00 00 00 00 00 00
                    15 00 00 40 00 00 02 6F 25
                    39 00 00 40 00 00 08 CF 00 00 00 00 00 00 00
                    39 00 00 40 00 00 16 D0 00 00 00 00 00 00 00 00 00 00 00 00 00 00 00 00 00 00 00 00 00
                    15 00 00 40 00 00 02 6F 15
                    39 00 00 40 00 00 11 D0 00 00 00 00 00 00 00 00 00 00 00 00 00 00 00 00
                    15 00 00 40 00 00 02 6F 25
                    39 00 00 40 00 00 08 D0 00 00 00 00 00 00 00
                    39 00 00 40 00 00 0F D1 00 00 B1 CB C0 04 74 00 00 B8 B0 E1 04 74
                    15 00 00 40 00 00 02 6F 0E
                    39 00 00 40 00 00 0F D1 00 00 00 00 00 00 00 00 00 00 00 00 00 00
                    15 00 00 40 00 00 02 6F 1C
                    39 00 00 40 00 00 0F D1 00 00 00 00 00 00 00 00 00 00 00 00 00 00
                    15 00 00 40 00 00 02 6F 2A
                    39 00 00 40 00 00 0C D1 7F FE 96 AF C0 00 00 7F FE 93 64
                    39 00 00 40 00 00 12 D2 A9 00 00 00 00 01 71 90 04 5C 00 00 1C 84 20 04 5C
                    39 00 00 40 00 00 06 F0 55 AA 52 08 00
                    15 00 00 40 00 00 02 6F 13
                    39 00 00 40 00 00 19 DF 00 00 00 00 00 00 00 00 00 00 00 00 00 00 00 00 00 00 00 00 00 00 00 00
                    39 00 00 00 00 00 0A 88 00 00 00 00 00 00 00 00 00
					/* elvdd 4.8V */
					39 00 00 40 00 00 06 F0 55 AA 52 08 00
					15 00 00 40 00 00 02 6F 63
					15 00 00 00 00 00 02 D5 20
					39 00 00 40 00 00 06 F0 55 AA 52 08 00
					15 00 00 40 00 00 02 BE 54
					15 00 00 40 00 00 02 6F 08
					15 00 00 00 00 00 02 B2 C0
					/* Remove black insertion */
					39 00 00 40 00 00 06 F0 55 AA 52 08 01
					15 00 00 40 00 00 02 6F 01
					15 00 00 40 00 00 02 D2 00
					39 00 00 00 00 00 06 F0 55 AA 52 08 00
					/* Elvdd timing delay */
					39 00 00 40 00 00 06 F0 55 AA 52 08 01
					15 00 00 40 00 00 02 CD 61
					39 00 00 00 00 00 06 F0 55 AA 52 08 00
					/* Enable 60 to 30 */
					39 00 00 40 00 00 06 F0 55 AA 52 08 00
					15 00 00 40 00 00 02 6F 6E
					39 00 00 00 00 00 03 D1 FF FF
					/* Vin3 delay */
					39 00 00 40 00 00 06 F0 55 AA 52 08 01
					15 00 00 40 00 00 02 6F 00
					15 00 00 40 00 00 02 D8 40
					39 00 00 00 00 00 06 F0 55 AA 52 08 00
					/*sleep out*/
					05 00 00 00 78 00 01 11
					/*display on*/
					05 00 00 00 00 00 01 29
				];
				qcom,mdss-dsi-optimize-on-command = [
					39 00 00 40 00 00 06 F0 55 AA 52 08 00
					15 00 00 40 00 00 02 6F 03
					15 00 00 40 00 00 02 B5 65
					39 00 00 40 00 00 06 F0 55 AA 52 08 08
					15 00 00 40 00 00 02 6F 80
					39 00 00 40 00 00 0D B8 00 10 00 10 00 10 00 00 00 00 00 00
					39 00 00 40 00 00 11 E9 00 00 00 C5 18 94 0F E6 01 90 00 78 14 48 0F C6
					/*Common Setting*/
					39 00 00 40 00 00 06 F0 55 AA 52 08 00
					15 00 00 40 00 00 02 6F 5A
					39 00 00 00 00 00 08 D1 33 33 33 33 11 11 11
					39 00 00 40 00 00 06 F0 55 AA 52 08 01
					15 00 00 40 00 00 02 6F 03
					39 00 00 40 00 00 04 C5 00 24 24
					15 00 00 40 00 00 02 E5 00
					39 00 00 40 00 00 06 F0 55 AA 52 00 00
					39 00 00 40 00 00 05 FF AA 55 A5 80
					15 00 00 40 00 00 02 6F 16
					39 00 00 40 00 00 03 F4 02 74
					15 00 00 40 00 00 02 6F 31
					39 00 00 40 00 00 03 F8 01 73
					15 00 00 40 00 00 02 6F 15
					39 00 00 40 00 00 03 F8 01 8F
					15 00 00 40 00 00 02 6F 42
					15 00 00 40 00 00 02 F4 00
					15 00 00 40 00 00 02 6F 49
					15 00 00 40 00 00 02 F2 10
					39 00 00 40 00 00 05 FF AA 55 A5 81
					15 00 00 40 00 00 02 6F 0D
					15 00 00 40 00 00 02 FB 80
					15 00 00 40 00 00 02 6F 10
					15 00 00 40 00 00 02 FB 40
					15 00 00 40 00 00 02 6F 0C
					15 00 00 40 00 00 02 FD 08
					15 00 00 40 00 00 02 6F 05
					39 00 00 40 00 00 03 FE 3C 3C
					15 00 00 40 00 00 02 6F 0B
					15 00 00 40 00 00 02 FD 04
					39 00 00 40 00 00 05 FF AA 55 A5 82
					15 00 00 40 00 00 02 6F 09
					15 00 00 40 00 00 02 F2 FF
					39 00 00 40 00 00 05 FF AA 55 A5 83
					39 00 00 40 00 00 05 FF AA 55 A5 00
					05 00 00 00 00 00 01 35
					15 00 00 40 00 00 02 53 20
					39 00 00 40 00 00 05 2A 00 00 04 73
					39 00 00 40 00 00 05 2B 00 00 0A 37
					15 00 00 40 00 00 02 26 00
					39 00 00 00 00 00 03 81 01 19
					/*DSC Setting*/
					39 00 00 40 00 00 03 90 03 43
					39 00 00 00 00 00 13 91 A0 F0 00 0C D1 00 01 CC 00 50 00 2F 09 75 2D 7A 11 50
					//Switch to 60Hz(3+18pulse)
					15 00 00 40 00 00 02 2F 02
					39 00 00 40 00 00 06 35 00 00 00 00 01
					15 00 00 00 10 00 02 5A 10
					15 00 00 40 00 00 02 6D 01
					15 00 00 40 00 00 02 2F 32
					//Base 60hz(3+18) SEQ Setting
					39 00 00 40 00 00 06 F0 55 AA 52 08 00
					15 00 00 40 00 00 02 6F 1C
					39 00 00 40 00 00 11 BA 01 00 00 00 01 00 00 00 01 00 00 00 00 00 00 00
					15 00 00 40 00 00 02 6F 2C
					39 00 00 40 00 00 11 BA 00 00 00 00 00 00 00 00 00 00 00 00 00 00 00 00
					15 00 00 40 00 00 02 6F 3C
					39 00 00 40 00 00 11 BA 00 00 00 00 00 00 00 00 00 00 00 00 00 00 00 00
					15 00 00 40 00 00 02 6F 4C
					39 00 00 40 00 00 11 BA 00 00 00 00 00 00 00 00 00 00 00 00 00 00 00 00
					15 00 00 40 00 00 02 6F 5C
					39 00 00 40 00 00 11 BA 01 01 01 01 01 01 01 01 01 01 01 01 01 01 01 01
					15 00 00 40 00 00 02 6F 6C
					39 00 00 40 00 00 09 BA 00 00 00 00 00 00 00 00
					15 00 00 40 00 00 02 6F 74
					39 00 00 40 00 00 11 BA 01 01 02 03 05 0B 17 77 00 02 05 08 11 59 00 00
					15 00 00 40 00 00 02 6F 84
					39 00 00 40 00 00 11 BA 01 01 02 03 05 0B 17 77 01 02 05 08 11 59 00 00
					15 00 00 40 00 00 02 6F 94
					39 00 00 40 00 00 11 BA 00 00 00 00 00 00 00 00 00 00 00 00 00 00 00 00
					15 00 00 40 00 00 02 6F A4
					39 00 00 40 00 00 11 BA 01 01 01 01 00 00 00 00 00 00 00 00 00 00 00 00
					15 00 00 40 00 00 02 6F B4
					39 00 00 40 00 00 05 BA 00 00 00 00
					15 00 00 40 00 00 02 6F B8
					39 00 00 40 00 00 09 BA 22 22 22 22 11 11 11 22
					15 00 00 40 00 00 02 6F C0
					39 00 00 00 00 00 09 BA 22 22 22 22 11 11 11 22
					/* delay 8ms make sure pmic timing normal */
					39 00 00 40 00 00 06 F0 55 AA 52 08 00
					15 00 00 40 00 00 02 6F 02
					39 00 00 00 00 00 03 B5 2A 95
					/*add VDC code resolve 100%APL brightness */
					39 00 00 40 00 00 06 F0 55 AA 52 08 08
					39 00 00 40 00 00 11 BE 03 F1 00 5B 02 C0 03 C6 BA 6C 03 C6 BA 6C 03 59
					39 00 00 40 00 00 02 6F 10
					39 00 00 40 00 00 11 BE CA BA 03 59 CA BA 01 22 04 BA 01 22 04 BA 01 01
					39 00 00 40 00 00 02 6F 20
					39 00 00 00 00 00 11 BE 56 6B 01 01 56 6B 04 A9 BB B4 01 66 1E B6 80 64
					39 00 00 40 00 00 06 F0 55 AA 52 08 07
					39 00 00 40 00 00 04 C0 07 01 F8
					15 00 00 40 00 00 02 6F 03
					39 00 00 40 00 00 05 C0 00 00 00 00
					39 00 00 40 00 00 16 C1 30 0F 02 40 04 00 FA 00 3F FE 12 00 3F FC 52 00 00 00 65 C0 00
					15 00 00 40 00 00 02 6F 15
					39 00 00 40 00 00 11 C1 20 00 1F 77 00 00 20 33 F0 E0 A8 0B 00 00 00 00
					15 00 00 40 00 00 02 6F 25
					39 00 00 40 00 00 08 C1 00 00 1E 00 00 20 00
					39 00 00 40 00 00 16 C2 38 0F 06 40 02 40 F8 80 3F FB 3D 40 3F FD E9 A0 00 00 78 D9 80
					15 00 00 40 00 00 02 6F 15
					39 00 00 40 00 00 11 C2 64 00 00 1E 00 21 85 33 F0 9C E2 0B B8 00 00 00
					15 00 00 40 00 00 02 6F 25
					39 00 00 40 00 00 08 C2 44 55 73 00 00 20 00
					39 00 00 40 00 00 16 C3 3C 00 0E 89 03 C1 0E C6 3F F1 59 00 00 00 00 00 00 00 00 00 00
					15 00 00 40 00 00 02 6F 15
					39 00 00 40 00 00 11 C3 70 00 00 1F 9A A3 16 33 C0 8D 1F 00 00 00 00 00
					15 00 00 40 00 00 02 6F 25
					39 00 00 40 00 00 08 C3 00 00 1F AA 17 37 00
					39 00 00 40 00 00 16 C4 34 00 03 84 03 C1 07 44 3F FC 6C 0C 00 03 93 F4 00 00 00 00 00
					15 00 00 40 00 00 02 6F 15
					39 00 00 40 00 00 11 C4 20 00 20 7D AA 17 37 33 C0 E0 5D 00 00 00 00 00
					15 00 00 40 00 00 02 6F 25
					39 00 00 40 00 00 08 C4 44 54 73 AA 17 37 00
					39 00 00 40 00 00 16 C5 2A 0F 0D 24 03 49 F2 DC 00 0A 36 88 00 01 BF 3C 7F FE 92 11 64
					15 00 00 40 00 00 02 6F 15
					39 00 00 40 00 00 11 C5 70 44 54 73 9A A4 16 33 0F 72 1F F2 32 00 00 00
					15 00 00 40 00 00 02 6F 25
					39 00 00 40 00 00 08 C5 00 00 00 00 00 00 00
					39 00 00 40 00 00 16 C6 2A 0F 01 E4 04 00 FA 80 00 01 20 30 00 04 15 60 7F FF 6D 54 00
					15 00 00 40 00 00 02 6F 15
					39 00 00 40 00 00 11 C6 00 34 FF 53 AA 17 37 33 0F 20 54 F5 80 00 00 00
					15 00 00 40 00 00 02 6F 25
					39 00 00 40 00 00 08 C6 00 00 00 00 00 00 00
					39 00 00 40 00 00 16 C7 26 00 02 40 04 84 06 60 00 00 64 00 3F FA 0B 00 00 00 00 00 00
					15 00 00 40 00 00 02 6F 15
					39 00 00 40 00 00 11 C7 1F 34 FC 54 00 00 20 33 30 20 A8 00 00 00 00 00
					15 00 00 40 00 00 02 6F 25
					39 00 00 40 00 00 08 C7 00 00 00 00 00 00 00
					39 00 00 40 00 00 16 C8 26 00 0B 64 02 A4 0A F8 00 03 D4 00 3F FC 2C 00 00 00 00 00 00
					15 00 00 40 00 00 02 6F 15
					39 00 00 40 00 00 11 C8 00 44 55 73 00 21 8F 33 30 6E E2 00 00 00 00 00
					15 00 00 40 00 00 02 6F 25
					39 00 00 40 00 00 08 C8 00 00 00 00 00 00 00
					39 00 00 40 00 00 16 C9 21 00 05 10 05 10 00 00 3F FE 93 80 3F FE 93 80 00 00 1C 84 20
					15 00 00 40 00 00 02 6F 15
					39 00 00 40 00 00 11 C9 0A 22 14 39 00 1C 41 55 F0 DC DC 05 10 F0 FF FF
					15 00 00 40 00 00 02 6F 25
					39 00 00 40 00 00 08 C9 00 00 00 00 00 00 00
					39 00 00 40 00 00 16 CA 27 00 05 10 05 10 00 00 00 00 00 00 3F FE 93 80 00 00 01 71 90
					15 00 00 40 00 00 02 6F 15
					39 00 00 40 00 00 11 CA 0A 22 3A 5F 00 1C 41 55 30 24 DC 00 00 C0 00 FF
					15 00 00 40 00 00 02 6F 25
					39 00 00 40 00 00 08 CA 00 00 00 00 00 00 00
					39 00 00 40 00 00 16 CB 2D 00 05 10 05 10 00 00 3F FE 93 80 00 00 00 00 00 00 01 71 90
					15 00 00 40 00 00 02 6F 15
					39 00 00 40 00 00 11 CB 19 22 14 39 00 42 67 55 C0 DC 24 00 00 30 FF 00
					15 00 00 40 00 00 02 6F 25
					39 00 00 40 00 00 08 CB 00 00 00 00 00 00 00
					39 00 00 40 00 00 16 CC 2B 00 05 10 05 10 00 00 00 00 00 00 00 00 00 00 7F FF E6 5F 00
					15 00 00 40 00 00 02 6F 15
					39 00 00 40 00 00 11 CC 19 22 3A 5F 00 42 67 55 0F 24 24 FA F0 00 00 00
					15 00 00 40 00 00 02 6F 25
					39 00 00 40 00 00 08 CC 00 00 00 00 00 00 00
					39 00 00 40 00 00 16 CD 00 00 00 00 00 00 00 00 00 00 00 00 00 00 00 00 00 00 00 00 00
					15 00 00 40 00 00 02 6F 15
					39 00 00 40 00 00 11 CD 00 00 00 00 00 00 00 00 00 00 00 00 00 00 00 00
					15 00 00 40 00 00 02 6F 25
					39 00 00 40 00 00 08 CD 00 00 00 00 00 00 00
					39 00 00 40 00 00 16 CE 00 00 00 00 00 00 00 00 00 00 00 00 00 00 00 00 00 00 00 00 00
					15 00 00 40 00 00 02 6F 15
					39 00 00 40 00 00 11 CE 00 00 00 00 00 00 00 00 00 00 00 00 00 00 00 00
					15 00 00 40 00 00 02 6F 25
					39 00 00 40 00 00 08 CE 00 00 00 00 00 00 00
					39 00 00 40 00 00 16 CF 00 00 00 00 00 00 00 00 00 00 00 00 00 00 00 00 00 00 00 00 00
					15 00 00 40 00 00 02 6F 15
					39 00 00 40 00 00 11 CF 00 00 00 00 00 00 00 00 00 00 00 00 00 00 00 00
					15 00 00 40 00 00 02 6F 25
					39 00 00 40 00 00 08 CF 00 00 00 00 00 00 00
					39 00 00 40 00 00 16 D0 00 00 00 00 00 00 00 00 00 00 00 00 00 00 00 00 00 00 00 00 00
					15 00 00 40 00 00 02 6F 15
					39 00 00 40 00 00 11 D0 00 00 00 00 00 00 00 00 00 00 00 00 00 00 00 00
					15 00 00 40 00 00 02 6F 25
					39 00 00 40 00 00 08 D0 00 00 00 00 00 00 00
					39 00 00 40 00 00 0F D1 80 00 00 00 00 04 73 80 00 00 00 00 04 73
					15 00 00 40 00 00 02 6F 0E
					39 00 00 40 00 00 0F D1 FF FE 70 57 49 04 73 FF FF 2A 07 00 04 73
					15 00 00 40 00 00 02 6F 1C
					39 00 00 40 00 00 0F D1 00 00 00 00 00 04 74 00 00 00 00 00 04 74
					15 00 00 40 00 00 02 6F 2A
					39 00 00 40 00 00 0C D1 00 00 66 70 00 04 74 00 00 9A E3
					39 00 00 00 00 00 12 D2 90 04 74 00 00 01 71 90 04 5C 00 00 1C 84 20 04 5C
					//SPR SETTING
					39 00 00 40 00 00 06 F0 55 AA 52 08 02
					15 00 00 40 00 00 02 C1 02
					39 00 00 40 00 00 05 C2 19 00 91 00
					39 00 00 40 00 00 06 F0 55 AA 52 08 03
					15 00 00 40 00 00 02 6F 08
					15 00 00 40 00 00 02 DE 00
					15 00 00 40 00 00 02 6F 09
					39 00 00 40 00 00 07 DE 30 14 25 10 34 25
					39 00 00 40 00 00 06 F0 55 AA 52 08 07
					39 00 00 40 00 00 06 B0 84 C4 00 00 40
					39 00 00 00 00 00 07 B1 08 18 00 18 08 00
					/*VDC setting only for EVT1 and before*/
					39 00 00 40 00 00 06 F0 55 AA 52 08 08
					39 00 00 40 00 00 02 6F 80
					39 00 00 40 00 00 0D B8 00 10 00 10 00 10 00 00 00 00 00 00
					39 00 00 00 00 00 11 E9 00 00 00 C5 18 94 0F E6 01 90 00 78 14 48 0F C6
					/*DDIC round corner*/
                    39 00 00 40 00 00 06 F0 55 AA 52 08 07
                    39 00 00 40 00 00 04 C0 07 01 F8
                    15 00 00 40 00 00 02 6F 03
                    39 00 00 40 00 00 05 C0 00 00 00 00
                    39 00 00 40 00 00 16 C1 36 00 03 49 0B 64 0C 3C 00 00 26 74 3F F3 88 64 00 00 00 00 00
                    15 00 00 40 00 00 02 6F 15
                    39 00 00 40 00 00 11 C1 1E 34 E1 51 00 00 1F 33 30 1F 90 00 00 00 00 00
                    15 00 00 40 00 00 02 6F 25
                    39 00 00 40 00 00 08 C1 44 52 73 00 00 1F 00
                    39 00 00 40 00 00 16 C2 36 00 0A 29 03 49 0B 8E 00 04 49 78 3F FB 6A D8 00 00 00 00 00
                    15 00 00 40 00 00 02 6F 15
                    39 00 00 40 00 00 11 C2 01 44 52 73 00 20 8D 33 30 6D DF 00 00 00 00 00
                    15 00 00 40 00 00 02 6F 25
                    39 00 00 40 00 00 08 C2 00 00 21 00 01 1F 00
                    39 00 00 40 00 00 16 C3 30 0F 0A 29 03 C1 F3 A6 3F F8 E6 92 3F FC A6 1A 00 00 BF 0E C5
                    15 00 00 40 00 00 02 6F 15
                    39 00 00 40 00 00 11 C3 02 00 00 21 00 20 8D 33 F0 93 DF 0E 0D 00 00 00
                    15 00 00 40 00 00 02 6F 25
                    39 00 00 40 00 00 08 C3 44 52 72 AA 18 37 00
                    39 00 00 40 00 00 16 C4 30 0F 03 C1 0B 64 F2 EC 3F FC B7 20 3F F8 AF E4 00 00 B7 F1 00
                    15 00 00 40 00 00 02 6F 15
                    39 00 00 40 00 00 11 C4 1D 00 22 92 00 00 1F 33 F0 E1 90 0D 90 00 00 00
                    15 00 00 40 00 00 02 6F 25
                    39 00 00 40 00 00 08 C4 00 00 21 AA 18 36 00
                    39 00 00 40 00 00 16 C5 2A 0F 03 49 0B 64 F3 C4 00 01 A1 B8 00 09 B5 64 7F FE A8 46 80
                    15 00 00 40 00 00 02 6F 15
                    39 00 00 40 00 00 11 C5 00 34 E1 51 AA 18 37 33 0F 1F 70 F2 70 00 00 00
                    15 00 00 40 00 00 02 6F 25
                    39 00 00 40 00 00 08 C5 00 00 00 00 00 00 00
                    39 00 00 40 00 00 16 C6 2A 0F 0A 29 03 49 F4 72 00 09 34 EE 00 01 C8 FE 7F FE A4 F4 E9
                    15 00 00 40 00 00 02 6F 15
                    39 00 00 40 00 00 11 C6 6B 44 52 73 9A AA 17 33 0F 6D 21 F1 F3 00 00 00
                    15 00 00 40 00 00 02 6F 25
                    39 00 00 40 00 00 08 C6 00 00 00 00 00 00 00
                    39 00 00 40 00 00 16 C7 2C 00 03 C1 0B 64 0D 14 3F FB 21 B4 00 04 8D E4 00 00 00 00 00
                    15 00 00 40 00 00 02 6F 15
                    39 00 00 40 00 00 11 C7 01 00 22 92 AA 18 37 33 C0 E1 70 00 00 00 00 00
                    15 00 00 40 00 00 02 6F 25
                    39 00 00 40 00 00 08 C7 00 00 00 00 00 00 00
                    39 00 00 40 00 00 16 C8 2C 00 0A 29 03 C1 0C 5A 3F F3 A4 40 00 00 27 8C 00 00 00 00 00
                    15 00 00 40 00 00 02 6F 15
                    39 00 00 40 00 00 11 C8 6A 00 00 21 9A AA 17 33 C0 93 21 00 00 00 00 00
                    15 00 00 40 00 00 02 6F 25
                    39 00 00 40 00 00 08 C8 00 00 00 00 00 00 00
                    39 00 00 40 00 00 16 C9 21 00 05 10 05 10 00 00 3F FE 93 80 3F FE 93 80 00 00 1C 84 20
                    15 00 00 40 00 00 02 6F 15
                    39 00 00 40 00 00 11 C9 0A 22 14 39 00 1C 41 55 F0 DC DC 05 10 F0 FF FF
                    15 00 00 40 00 00 02 6F 25
                    39 00 00 40 00 00 08 C9 00 00 00 00 00 00 00
                    39 00 00 40 00 00 16 CA 27 00 05 10 05 10 00 00 00 00 00 00 3F FE 93 80 00 00 01 71 90
                    15 00 00 40 00 00 02 6F 15
                    39 00 00 40 00 00 11 CA 0A 22 3A 5F 00 1C 41 55 30 24 DC 00 00 C0 00 FF
                    15 00 00 40 00 00 02 6F 25
                    39 00 00 40 00 00 08 CA 00 00 00 00 00 00 00
                    39 00 00 40 00 00 16 CB 2D 00 05 10 05 10 00 00 3F FE 93 80 00 00 00 00 00 00 01 71 90
                    15 00 00 40 00 00 02 6F 15
                    39 00 00 40 00 00 11 CB 19 22 14 39 00 42 67 55 C0 DC 24 00 00 30 FF 00
                    15 00 00 40 00 00 02 6F 25
                    39 00 00 40 00 00 08 CB 00 00 00 00 00 00 00
                    39 00 00 40 00 00 16 CC 2B 00 05 10 05 10 00 00 00 00 00 00 00 00 00 00 7F FF E6 5F 00
                    15 00 00 40 00 00 02 6F 15
                    39 00 00 40 00 00 11 CC 19 22 3A 5F 00 42 67 55 0F 24 24 FA F0 00 00 00
                    15 00 00 40 00 00 02 6F 25
                    39 00 00 40 00 00 08 CC 00 00 00 00 00 00 00
                    39 00 00 40 00 00 16 CD 00 00 00 00 00 00 00 00 00 00 00 00 00 00 00 00 00 00 00 00 00
                    15 00 00 40 00 00 02 6F 15
                    39 00 00 40 00 00 11 CD 00 00 00 00 00 00 00 00 00 00 00 00 00 00 00 00
                    15 00 00 40 00 00 02 6F 25
                    39 00 00 40 00 00 08 CD 00 00 00 00 00 00 00
                    39 00 00 40 00 00 16 CE 00 00 00 00 00 00 00 00 00 00 00 00 00 00 00 00 00 00 00 00 00
                    15 00 00 40 00 00 02 6F 15
                    39 00 00 40 00 00 11 CE 00 00 00 00 00 00 00 00 00 00 00 00 00 00 00 00
                    15 00 00 40 00 00 02 6F 25
                    39 00 00 40 00 00 08 CE 00 00 00 00 00 00 00
                    39 00 00 40 00 00 16 CF 00 00 00 00 00 00 00 00 00 00 00 00 00 00 00 00 00 00 00 00 00
                    15 00 00 40 00 00 02 6F 15
                    39 00 00 40 00 00 11 CF 00 00 00 00 00 00 00 00 00 00 00 00 00 00 00 00
                    15 00 00 40 00 00 02 6F 25
                    39 00 00 40 00 00 08 CF 00 00 00 00 00 00 00
                    39 00 00 40 00 00 16 D0 00 00 00 00 00 00 00 00 00 00 00 00 00 00 00 00 00 00 00 00 00
                    15 00 00 40 00 00 02 6F 15
                    39 00 00 40 00 00 11 D0 00 00 00 00 00 00 00 00 00 00 00 00 00 00 00 00
                    15 00 00 40 00 00 02 6F 25
                    39 00 00 40 00 00 08 D0 00 00 00 00 00 00 00
                    39 00 00 40 00 00 0F D1 00 00 B1 CB C0 04 74 00 00 B8 B0 E1 04 74
                    15 00 00 40 00 00 02 6F 0E
                    39 00 00 40 00 00 0F D1 00 00 00 00 00 00 00 00 00 00 00 00 00 00
                    15 00 00 40 00 00 02 6F 1C
                    39 00 00 40 00 00 0F D1 00 00 00 00 00 00 00 00 00 00 00 00 00 00
                    15 00 00 40 00 00 02 6F 2A
                    39 00 00 40 00 00 0C D1 7F FE 96 AF C0 00 00 7F FE 93 64
                    39 00 00 40 00 00 12 D2 A9 00 00 00 00 01 71 90 04 5C 00 00 1C 84 20 04 5C
                    39 00 00 40 00 00 06 F0 55 AA 52 08 00
                    15 00 00 40 00 00 02 6F 13
                    39 00 00 40 00 00 19 DF 00 00 00 00 00 00 00 00 00 00 00 00 00 00 00 00 00 00 00 00 00 00 00 00
                    39 00 00 00 00 00 0A 88 00 00 00 00 00 00 00 00 00
					39 00 00 40 00 00 06 F0 55 AA 52 08 00
					15 00 00 40 00 00 02 BE 54
					15 00 00 40 00 00 02 6F 08
					15 00 00 00 00 00 02 B2 C0
					/* Remove black insertion */
					39 00 00 40 00 00 06 F0 55 AA 52 08 01
					15 00 00 40 00 00 02 6F 01
					15 00 00 40 00 00 02 D2 00
					39 00 00 00 00 00 06 F0 55 AA 52 08 00
					/* Elvdd timing delay */
					39 00 00 40 00 00 06 F0 55 AA 52 08 01
					15 00 00 40 00 00 02 CD 61
					39 00 00 00 00 00 06 F0 55 AA 52 08 00
					/* Enable 60 to 30 */
					39 00 00 40 00 00 06 F0 55 AA 52 08 00
					15 00 00 40 00 00 02 6F 6E
					39 00 00 00 00 00 03 D1 FF FF
					/* Vin3 delay */
					39 00 00 40 00 00 06 F0 55 AA 52 08 01
					15 00 00 40 00 00 02 6F 00
					15 00 00 40 00 00 02 D8 40
					39 00 00 00 00 00 06 F0 55 AA 52 08 00
					/*sleep out*/
					05 00 00 00 78 00 01 11
					/*display on*/
					05 00 00 00 00 00 01 29
				];
				qcom,mdss-dsi-panel-info-switch-page-command = [
					/*read panel info switch page 01*/
					39 00 00 00 00 00 06 F0 55 AA 52 08 01
				];
				qcom,mdss-dsi-default-switch-page-command = [
					/*switch default page*/
					39 00 00 00 00 00 06 F0 55 AA 52 08 00
				];
				qcom,mdss-dsi-off-command = [
					05 00 00 00 14 00 01 28
					05 00 00 00 78 00 01 10
				];
				qcom,mdss-dsi-lp1-command = [
					/* AOD mode on */
					39 00 00 40 00 00 02 5F 00
					39 00 00 40 00 00 06 F0 55 AA 52 08 00
					15 00 00 40 00 00 02 2F 02
					39 00 00 40 00 00 06 35 00 00 00 00 00
					05 00 00 40 00 00 01 39
					/* AOD Switch */
					15 00 00 40 00 00 02 6F 04
					39 00 00 00 00 00 03 51 09 D3
				];
				qcom,mdss-dsi-nolp-command = [
					/* AOD Mode OFF */
					05 00 00 40 00 00 01 38
					39 00 00 40 00 00 06 35 00 00 00 00 01
					/* AOD OFF SEQ 3+18pulse*/
					15 00 00 40 00 00 02 6D 01
					15 00 00 00 00 00 02 2F 32
				];
				qcom,mdss-dsi-aod-high-mode-command = [
					/* AOD 50nit */
					15 00 00 40 00 00 02 6F 04
					39 00 00 00 00 00 03 51 09 D3
				];
				qcom,mdss-dsi-aod-low-mode-command = [
					/* AOD 10nit */
					15 00 00 40 00 00 02 6F 04
					39 00 00 00 00 00 03 51 00 03
				];
				 qcom,mdss-dsi-ultra-low-power-aod-on-command = [
                                        39 00 00 40 00 00 06 F0 55 AA 52 08 00
                                        15 00 00 40 00 00 02 6F 08
                                        39 00 00 40 00 00 05 BB 01 00 00 00
                                        15 00 00 40 00 00 02 6F 0C
                                        39 00 00 40 00 00 05 BB 01 00 00 00
                                        15 00 00 40 00 00 02 6F 10
                                        39 00 00 40 00 00 05 BB 01 00 00 00
                                        15 00 00 40 00 00 02 6F 14
                                        39 00 00 40 00 00 05 BB 01 00 00 00
                                        15 00 00 40 00 00 02 6F 18
                                        39 00 00 40 00 00 06 BB 01 00 1D 1D 00
                                        15 00 00 40 00 00 02 6F 1D
                                        39 00 00 40 00 00 05 BB 01 00 00 00
                                        15 00 00 00 00 00 02 2F 30
                                ];
				qcom,mdss-dsi-ultra-low-power-aod-off-command = [
					39 00 00 40 00 00 06 F0 55 AA 52 08 00
					15 00 00 00 00 00 02 2F 02
				];
				qcom,mdss-dsi-loading-effect-1-command = [
					/* Loading On 100% */
					39 00 00 00 00 00 02 5F 00
				];
				qcom,mdss-dsi-loading-effect-2-command = [
					/* Loading On 110% */
					39 00 00 00 00 00 02 5F 01
				];
				qcom,mdss-dsi-loading-effect-3-command = [
				];
				qcom,mdss-dsi-loading-effect-4-command = [
				];
				qcom,mdss-dsi-loading-effect-off-command = [
					39 00 00 00 00 00 02 5F 02
				];
				qcom,mdss-dsi-loading-effect-1-command-state = "dsi_hs_mode";
				qcom,mdss-dsi-loading-effect-2-command-state = "dsi_hs_mode";
				qcom,mdss-dsi-loading-effect-3-command-state = "dsi_hs_mode";
				qcom,mdss-dsi-loading-effect-4-command-state = "dsi_hs_mode";
				qcom,mdss-dsi-timing-switch-command-state = "dsi_hs_mode";
				qcom,mdss-dsi-on-command-state = "dsi_lp_mode";
				qcom,mdss-dsi-optimize-on-command-state = "dsi_lp_mode";
				qcom,mdss-dsi-off-command-state = "dsi_hs_mode";
				qcom,mdss-dsi-panel-info-switch-page-command-state = "dsi_lp_mode";
				qcom,mdss-dsi-default-switch-page-command-state = "dsi_lp_mode";

				qcom,lm-split = <570 570>;
				qcom,compression-mode = "dsc";
				qcom,mdss-dsc-encoders = <2>;
				qcom,mdss-dsc-slice-height = <12>;
				qcom,mdss-dsc-slice-width = <570>;
				qcom,mdss-dsc-slice-per-pkt = <2>;
				qcom,mdss-dsc-bit-per-component = <10>;
				qcom,mdss-dsc-bit-per-pixel = <8>;
				qcom,mdss-dsc-block-prediction-enable;
				qcom,src-chroma-format = <1>;
				/* SPR CONFIG */
				qcom,spr-pack-type = "pentile";
			};
		};
	};
};

&soc {
	dsi_panel_AC140_S_3_A0014_dsc_cmd {
		qcom,dsi-display-active;
	};
};

&dsi_panel_AC140_S_3_A0014_dsc_cmd {
	qcom,panel-sec-supply-entries = <&oplus_petrel_sec_dsi_panel_pwr_supply>;
	qcom,mdss-dsi-sec-bl-pmic-control-type = "bl_ctrl_dcs";
	qcom,bl-update-flag = "delay_until_first_frame";
	qcom,mdss-dsi-bl-min-level = <1>;
	qcom,mdss-dsi-bl-max-level = <4094>;
	qcom,mdss-brightness-max-level = <4094>;
	oplus,dsi-bl-normal-max-level = <3515>;
	oplus,dsi-brightness-normal-max-level = <3515>;
	oplus,dsi-dc-backlight-threshold = <1960>;
	oplus,dsi-brightness-default-level = <1638>;
	oplus,dsi_demura2_offset_support;

	qcom,mdss-dsi-bl-inverted-dbv;
	qcom,ulps-enabled;

	qcom,platform-sec-reset-gpio = <&tlmm 112 0>;
	oplus,panel-gpio1 = <&tlmm 6 0>;
	oplus,panel-gpio2 = <&tlmm 107 0>;
	oplus,panel-gpio3 = <&tlmm 153 0>;

	oplus,panel-reset-position = <0x02>;
	oplus,panel-power-on-sequence = "1", "gpio1", "1", "vddio", "3", "gpio2", "3", "gpio3", "10";
	oplus,panel-power-off-sequence = "1", "gpio3", "3", "gpio2", "3", "vddio", "1", "gpio1", "1";

	/* a pair of oplus pinctrl names, in order [active, suspend] */
	//oplus,dsi-pinctrl-names = "oplus_panel_active", "oplus_panel_suspend";
	//qcom,dsi-ctrl-num = <1>;
	//qcom,dsi-phy-num = <1>;
	//qcom,dsi-select-clocks = "pll_byte_clk1", "pll_dsi_clk1";

	qcom,dsi-sec-ctrl-num = <1>;
	qcom,dsi-sec-phy-num = <1>;
	qcom,dsi-select-sec-clocks = "pll_byte_clk1", "pll_dsi_clk1";

	/* ofp config */
	oplus,ofp-fp-type = <0x82>;
	oplus,ofp-longrui-aod-config = <0x02>;
	oplus,ofp-need-to-wait-data-before-aod-on;

	qcom,mdss-dsi-display-timings {
		timing@sa_fhd_120 { /* FHD+ 120hz 550Mhz 1100Mbps */
			qcom,mdss-dsi-panel-phy-timings = [00 24 0A 0A 1A 24 0A 0A 09 02 04 00 1E 0F];
			qcom,display-topology = <1 1 1>,<2 2 1>;
			qcom,default-topology-index = <1>;
		};
		timing@sa_fhd_90 { /* FHD+ 90hz 550Mhz 1100Mbps */
			qcom,mdss-dsi-panel-phy-timings = [00 24 0A 0A 1A 24 0A 0A 09 02 04 00 1E 0F];
			qcom,display-topology = <1 1 1>,<2 2 1>;
			qcom,default-topology-index = <1>;
		};
		timing@sa_fhd_60 { /* FHD+ 60hz 550Mhz 1100Mbps */
			qcom,mdss-dsi-panel-phy-timings = [00 24 0A 0A 1A 24 0A 0A 09 02 04 00 1E 0F];
			qcom,display-topology = <1 1 1>,<2 2 1>;
			qcom,default-topology-index = <1>;
		};
	};
};

&dsi_panel_AC140_S_3_A0014_dsc_cmd {
	/* adfr config */
	oplus,adfr-config = <0x11>;  // 0b0000'0000'0001'0001
	oplus,adfr-test-te-gpio = <&tlmm 88 0>;
	/* just for qsync enable*/
	qcom,qsync-enable;
	qcom,mdss-dsi-qsync-min-refresh-rate = <30>;

	qcom,mdss-dsi-display-timings {
		timing@sa_fhd_120 { /* FHD+ 120hz 550Mhz 1100Mbps */
			/* standard adfr */
			qcom,mdss-dsi-h-sync-skew = <0>;
			oplus,adfr-min-fps-mapping-table = <120 60 30 20 10 5 1>;
			oplus,adfr-idle-off-min-fps = <20>;

			qcom,mdss-dsi-adfr-min-fps-0-command = [
				15 00 00 40 00 00 02 2F 30
				15 00 00 00 00 00 02 6D 00
			];
			qcom,mdss-dsi-adfr-min-fps-1-command = [
				15 00 00 40 00 00 02 2F 30
				15 00 00 00 00 00 02 6D 01
			];
			qcom,mdss-dsi-adfr-min-fps-2-command = [
				15 00 00 40 00 00 02 2F 30
				15 00 00 00 00 00 02 6D 03
			];
			qcom,mdss-dsi-adfr-min-fps-3-command = [
				15 00 00 40 00 00 02 2F 30
				15 00 00 00 00 00 02 6D 04
			];
			qcom,mdss-dsi-adfr-min-fps-4-command = [
				15 00 00 40 00 00 02 2F 30
				15 00 00 00 00 00 02 6D 05
			];
			qcom,mdss-dsi-adfr-min-fps-5-command = [
				15 00 00 40 00 00 02 2F 30
				15 00 00 00 00 00 02 6D 06
			];
			qcom,mdss-dsi-adfr-min-fps-6-command = [
				15 00 00 40 00 00 02 2F 30
				15 00 00 00 00 00 02 6D 07
			];
			qcom,mdss-dsi-hpwm-adfr-min-fps-0-command = [
				15 00 00 40 00 00 02 2F 30
				15 00 00 00 00 00 02 6D 00
			];
			qcom,mdss-dsi-hpwm-adfr-min-fps-1-command = [
				15 00 00 40 00 00 02 2F 30
				15 00 00 00 00 00 02 6D 01
			];
			qcom,mdss-dsi-hpwm-adfr-min-fps-2-command = [
				15 00 00 40 00 00 02 2F 30
				15 00 00 00 00 00 02 6D 03
			];
			qcom,mdss-dsi-hpwm-adfr-min-fps-3-command = [
				15 00 00 40 00 00 02 2F 30
				15 00 00 00 00 00 02 6D 04
			];
			qcom,mdss-dsi-hpwm-adfr-min-fps-4-command = [
				15 00 00 40 00 00 02 2F 30
				15 00 00 00 00 00 02 6D 05
			];
			qcom,mdss-dsi-hpwm-adfr-min-fps-5-command = [
				15 00 00 40 00 00 02 2F 30
				15 00 00 00 00 00 02 6D 06
			];
			qcom,mdss-dsi-hpwm-adfr-min-fps-6-command = [
				15 00 00 40 00 00 02 2F 30
				15 00 00 00 00 00 02 6D 07
			];

			qcom,mdss-dsi-adfr-min-fps-0-command-state = "dsi_hs_mode";
			qcom,mdss-dsi-adfr-min-fps-1-command-state = "dsi_hs_mode";
			qcom,mdss-dsi-adfr-min-fps-2-command-state = "dsi_hs_mode";
			qcom,mdss-dsi-adfr-min-fps-3-command-state = "dsi_hs_mode";
			qcom,mdss-dsi-adfr-min-fps-4-command-state = "dsi_hs_mode";
			qcom,mdss-dsi-adfr-min-fps-5-command-state = "dsi_hs_mode";
			qcom,mdss-dsi-adfr-min-fps-6-command-state = "dsi_hs_mode";
			qcom,mdss-dsi-hpwm-adfr-min-fps-0-command-state = "dsi_hs_mode";
			qcom,mdss-dsi-hpwm-adfr-min-fps-1-command-state = "dsi_hs_mode";
			qcom,mdss-dsi-hpwm-adfr-min-fps-2-command-state = "dsi_hs_mode";
			qcom,mdss-dsi-hpwm-adfr-min-fps-3-command-state = "dsi_hs_mode";
			qcom,mdss-dsi-hpwm-adfr-min-fps-4-command-state = "dsi_hs_mode";
			qcom,mdss-dsi-hpwm-adfr-min-fps-5-command-state = "dsi_hs_mode";
			qcom,mdss-dsi-hpwm-adfr-min-fps-6-command-state = "dsi_hs_mode";
		};
		timing@sa_fhd_90 { /* FHD+ 90hz 550Mhz 1100Mbps */
			/* standard adfr */
			qcom,mdss-dsi-h-sync-skew = <0>;
			oplus,adfr-min-fps-mapping-table = <90 30 15 10 5 1>;
			oplus,adfr-idle-off-min-fps = <15>;

			qcom,mdss-dsi-adfr-min-fps-0-command = [
				15 00 00 40 00 00 02 2F 30
				15 00 00 00 00 00 02 6D 08
			];
			qcom,mdss-dsi-adfr-min-fps-1-command = [
				15 00 00 40 00 00 02 2F 30
				15 00 00 00 00 00 02 6D 09
			];
			qcom,mdss-dsi-adfr-min-fps-2-command = [
				15 00 00 40 00 00 02 2F 30
				15 00 00 00 00 00 02 6D 0A
			];
			qcom,mdss-dsi-adfr-min-fps-3-command = [
				15 00 00 40 00 00 02 2F 30
				15 00 00 00 00 00 02 6D 0B
			];
			qcom,mdss-dsi-adfr-min-fps-4-command = [
				15 00 00 40 00 00 02 2F 30
				15 00 00 00 00 00 02 6D 0C
			];
			qcom,mdss-dsi-adfr-min-fps-5-command = [
				15 00 00 40 00 00 02 2F 30
				15 00 00 00 00 00 02 6D 0D
			];
			qcom,mdss-dsi-hpwm-adfr-min-fps-0-command = [
				15 00 00 40 00 00 02 2F 30
				15 00 00 00 00 00 02 6D 08
			];
			qcom,mdss-dsi-hpwm-adfr-min-fps-1-command = [
				15 00 00 40 00 00 02 2F 30
				15 00 00 00 00 00 02 6D 09
			];
			qcom,mdss-dsi-hpwm-adfr-min-fps-2-command = [
				15 00 00 40 00 00 02 2F 30
				15 00 00 00 00 00 02 6D 0A
			];
			qcom,mdss-dsi-hpwm-adfr-min-fps-3-command = [
				15 00 00 40 00 00 02 2F 30
				15 00 00 00 00 00 02 6D 0B
			];
			qcom,mdss-dsi-hpwm-adfr-min-fps-4-command = [
				15 00 00 40 00 00 02 2F 30
				15 00 00 00 00 00 02 6D 0C
			];
			qcom,mdss-dsi-hpwm-adfr-min-fps-5-command = [
				15 00 00 40 00 00 02 2F 30
				15 00 00 00 00 00 02 6D 0D
			];

			qcom,mdss-dsi-adfr-min-fps-0-command-state = "dsi_hs_mode";
			qcom,mdss-dsi-adfr-min-fps-1-command-state = "dsi_hs_mode";
			qcom,mdss-dsi-adfr-min-fps-2-command-state = "dsi_hs_mode";
			qcom,mdss-dsi-adfr-min-fps-3-command-state = "dsi_hs_mode";
			qcom,mdss-dsi-adfr-min-fps-4-command-state = "dsi_hs_mode";
			qcom,mdss-dsi-adfr-min-fps-5-command-state = "dsi_hs_mode";
			qcom,mdss-dsi-hpwm-adfr-min-fps-0-command-state = "dsi_hs_mode";
			qcom,mdss-dsi-hpwm-adfr-min-fps-1-command-state = "dsi_hs_mode";
			qcom,mdss-dsi-hpwm-adfr-min-fps-2-command-state = "dsi_hs_mode";
			qcom,mdss-dsi-hpwm-adfr-min-fps-3-command-state = "dsi_hs_mode";
			qcom,mdss-dsi-hpwm-adfr-min-fps-4-command-state = "dsi_hs_mode";
			qcom,mdss-dsi-hpwm-adfr-min-fps-5-command-state = "dsi_hs_mode";
		};
		timing@sa_fhd_60 { /* FHD+ 60hz 550Mhz 1100Mbps */
			/* standard adfr */
			qcom,mdss-dsi-h-sync-skew = <1>;
			oplus,adfr-min-fps-mapping-table = <60 30 20 10 5 1>;
			oplus,adfr-idle-off-min-fps = <20>;

			qcom,mdss-dsi-adfr-min-fps-0-command = [
				15 00 00 40 00 00 02 2F 30
				15 00 00 00 00 00 02 6D 01
			];
			qcom,mdss-dsi-adfr-min-fps-1-command = [
				15 00 00 40 00 00 02 2F 30
				15 00 00 00 00 00 02 6D 03
			];
			qcom,mdss-dsi-adfr-min-fps-2-command = [
				15 00 00 40 00 00 02 2F 30
				15 00 00 00 00 00 02 6D 04
			];
			qcom,mdss-dsi-adfr-min-fps-3-command = [
				15 00 00 40 00 00 02 2F 30
				15 00 00 00 00 00 02 6D 05
			];
			qcom,mdss-dsi-adfr-min-fps-4-command = [
				15 00 00 40 00 00 02 2F 30
				15 00 00 00 00 00 02 6D 06
			];
			qcom,mdss-dsi-adfr-min-fps-5-command = [
				15 00 00 40 00 00 02 2F 30
				15 00 00 00 00 00 02 6D 07
			];
			qcom,mdss-dsi-hpwm-adfr-min-fps-0-command = [
				15 00 00 40 00 00 02 2F 30
				15 00 00 00 00 00 02 6D 01
			];
			qcom,mdss-dsi-hpwm-adfr-min-fps-1-command = [
				15 00 00 40 00 00 02 2F 30
				15 00 00 00 00 00 02 6D 03
			];
			qcom,mdss-dsi-hpwm-adfr-min-fps-2-command = [
				15 00 00 40 00 00 02 2F 30
				15 00 00 00 00 00 02 6D 04
			];
			qcom,mdss-dsi-hpwm-adfr-min-fps-3-command = [
				15 00 00 40 00 00 02 2F 30
				15 00 00 00 00 00 02 6D 05
			];
			qcom,mdss-dsi-hpwm-adfr-min-fps-4-command = [
				15 00 00 40 00 00 02 2F 30
				15 00 00 00 00 00 02 6D 06
			];
			qcom,mdss-dsi-hpwm-adfr-min-fps-5-command = [
				15 00 00 40 00 00 02 2F 30
				15 00 00 00 00 00 02 6D 07
			];

			qcom,mdss-dsi-adfr-min-fps-0-command-state = "dsi_hs_mode";
			qcom,mdss-dsi-adfr-min-fps-1-command-state = "dsi_hs_mode";
			qcom,mdss-dsi-adfr-min-fps-2-command-state = "dsi_hs_mode";
			qcom,mdss-dsi-adfr-min-fps-3-command-state = "dsi_hs_mode";
			qcom,mdss-dsi-adfr-min-fps-4-command-state = "dsi_hs_mode";
			qcom,mdss-dsi-adfr-min-fps-5-command-state = "dsi_hs_mode";
			qcom,mdss-dsi-hpwm-adfr-min-fps-0-command-state = "dsi_hs_mode";
			qcom,mdss-dsi-hpwm-adfr-min-fps-1-command-state = "dsi_hs_mode";
			qcom,mdss-dsi-hpwm-adfr-min-fps-2-command-state = "dsi_hs_mode";
			qcom,mdss-dsi-hpwm-adfr-min-fps-3-command-state = "dsi_hs_mode";
			qcom,mdss-dsi-hpwm-adfr-min-fps-4-command-state = "dsi_hs_mode";
			qcom,mdss-dsi-hpwm-adfr-min-fps-5-command-state = "dsi_hs_mode";
		};
	};
};

&dsi_panel_AC140_S_3_A0014_dsc_cmd {
	qcom,panel_voltage_vddi_name = "vddio";
	qcom,panel_voltage_vddi = <0 1700000 1800000 1900000>;
//	qcom,panel_voltage_vddr_name = "vci";
//	qcom,panel_voltage_vddr = <1 3000000 3200000 3300000>;
};

&dsi_panel_AC140_S_3_A0014_dsc_cmd {
	oplus,color_vivid_status;
	oplus,color_srgb_status;
	oplus,color_oplus_calibrate_status;
	oplus,color_dual_panel_status;
	oplus,color_dual_brightness_status;
	oplus,color_loading_status;
	oplus,color_2nit_status;
	oplus,mdss-dsi-panel-type = <0>;

	/* OPLUS FEATURES CONFIG */
	oplus,dp-enabled;
	oplus,enhance_mipi_strength;

	/* pwm config */
	oplus,pwm-switch-config = <0x01>;
	oplus,pwm-switch-mode0-states-info = <2 1146 1>;

	/* ESD CONFIG */
	qcom,esd-check-enabled;
	qcom,mdss-dsi-panel-status-check-mode = "reg_read";
	qcom,mdss-dsi-panel-status-command = [
		06 00 00 00 00 00 01 0A
	];
	qcom,mdss-dsi-panel-status-command-state = "dsi_lp_mode";
	qcom,mdss-dsi-panel-status-value = <
		0x9C
	>;
	qcom,mdss-dsi-panel-status-read-length = <1>;
	oplus,mdss-dsi-panel-status-match-modes = <0x00000000>;

	/* MIPI ERR check config */
	/*  BIT(0): enable/disable check
	 ** BIT(1): enable/disable page switch
	 */
	oplus,mipi-err-check-config = <0x03>; // 0b0000'0011
	oplus,mipi-err-check-reg = [
		AB
	];
	oplus,mipi-err-check-value = [
		00 00
	];
	oplus,mipi-err-check-count = [
		02
	];
	/* 32-bit binary flag
	 ** Bit value identified how to match the return value of each register.
	 ** The value 0(default) means equal, and the value 1 means not equal.
	 */
	oplus,mipi-err-check-match-modes = <0x00000000>;

	/* serial num config */
	oplus,dsi-serial-number-enabled;
	oplus,dsi-serial-number-switch-page;
	oplus,dsi-serial-number-index= <0>;
	oplus,dsi-serial-number-reg= <0xA3>;
	oplus,dsi-serial-number-read-count= <7>;

	/* SPR CONFIG */
	qcom,spr-pack-type = "pentile";
};
